VERSION ""

NS_ :

BS_:

BU_: AHLM ASBS CADM CBC DIAGNOST DPDM DTCM ECM EHPS ESC ESL ESM ETM EVCU2 GPF IC IRCM LTM OCM ORC PTS RF_HUB SCCM SGW TBM TCM

BO_ 996 NET_CFG_PT: 8 CBC
 SG_ NetCfg_TTPM : 59|1@1+ (1,0) [0|0] ""  RF_HUB,SGW
 SG_ NetCfg_TIM : 60|1@1+ (1,0) [0|0] ""  RF_HUB,SGW
 SG_ NetCfg_DPDM : 33|1@1+ (1,0) [0|0] ""  CADM,IRCM,RF_HUB,SGW
 SG_ NetCfg_SGW : 34|1@1+ (1,0) [0|0] ""  RF_HUB,SGW
 SG_ NetCfg_HCP : 38|1@1+ (1,0) [0|0] ""  CADM,EHPS,IRCM,RF_HUB,SGW
 SG_ NetCfg_ANC : 39|1@1+ (1,0) [0|0] ""  RF_HUB,SGW
 SG_ NetCfg_GPF : 58|1@1+ (1,0) [0|0] ""  RF_HUB,SGW
 SG_ NetCfg_AFLS : 28|1@1+ (1,0) [0|0] ""  RF_HUB,SGW
 SG_ NetCfg_ITBM : 29|1@1+ (1,0) [0|0] ""  RF_HUB,SGW
 SG_ NetCfg_OCM : 30|1@1+ (1,0) [0|0] ""  ORC,RF_HUB,SGW
 SG_ NetCfg_BSMO : 36|1@1+ (1,0) [0|0] ""  CADM,EHPS,IRCM,RF_HUB,SGW
 SG_ NetCfg_ELSD : 24|1@1+ (1,0) [0|0] ""  ESC,RF_HUB,SGW
 SG_ NetCfg_TCM : 25|1@1+ (1,0) [0|0] ""  CADM,ECM,ESM,IRCM,ORC,RF_HUB,SGW
 SG_ NetCfg_TPM : 26|1@1+ (1,0) [0|0] ""  RF_HUB,SGW
 SG_ NetCfg_ORC : 19|1@1+ (1,0) [0|0] ""  CADM,ECM,IRCM,RF_HUB,SGW
 SG_ NetCfg_PTS : 20|1@1+ (1,0) [0|0] ""  IC,RF_HUB,SGW
 SG_ NetCfg_DASM : 16|1@1+ (1,0) [0|0] ""  CADM,ECM,ESC,IC,IRCM,ORC,RF_HUB,SCCM,SGW,TCM
 SG_ NetCfg_FDCM : 17|1@1+ (1,0) [0|0] ""  RF_HUB,SGW
 SG_ NetCfg_ECM : 9|1@1+ (1,0) [0|0] ""  CADM,ECM,EHPS,IRCM,RF_HUB,SGW,TCM
 SG_ NetCfg_EPS : 10|1@1+ (1,0) [0|0] ""  ECM,IC,ORC,RF_HUB,SGW
 SG_ NetCfg_ESM : 11|1@1+ (1,0) [0|0] ""  ECM,RF_HUB,SGW
 SG_ NetCfg_ESC : 12|1@1+ (1,0) [0|0] ""  CADM,ECM,EHPS,IRCM,RF_HUB,SGW,TCM
 SG_ NetCfg_EPB : 13|1@1+ (1,0) [0|0] ""  ECM,RF_HUB,SGW
 SG_ NetCfg_RF_HUB : 14|1@1+ (1,0) [0|0] ""  CADM,ECM,IRCM,RF_HUB,SGW
 SG_ NetCfg_ADCM : 3|1@1+ (1,0) [0|0] ""  RF_HUB,SGW
 SG_ NetCfg_AHLM : 4|1@1+ (1,0) [0|0] ""  AHLM,RF_HUB,SGW
 SG_ NetCfg_VSIM_C : 5|1@1+ (1,0) [0|0] ""  ECM,RF_HUB,SGW
 SG_ NetCfg_ASCM : 6|1@1+ (1,0) [0|0] ""  RF_HUB,SGW
 SG_ NetCfg_CBC_PT : 7|1@1+ (1,0) [0|0] ""  CADM,ECM,EHPS,IRCM,RF_HUB,SGW,TCM
 SG_ NET_CFG_STAT_PT : 0|2@1+ (1,0) [0|0] ""  AHLM,ASBS,CADM,DPDM,DTCM,ECM,EHPS,ESC,ESL,ESM,EVCU2,IC,IRCM,OCM,ORC,PTS,RF_HUB,SCCM,SGW,TCM
 SG_ NetCfg_ACC : 2|1@1+ (1,0) [0|0] ""  RF_HUB,SGW
 SG_ NetCfg_DTCM : 8|1@1+ (1,0) [0|0] ""  CADM,ECM,ESC,EVCU2,IC,IRCM,PTS,RF_HUB,SGW,TCM
 SG_ NetCfg_IC : 15|1@1+ (1,0) [0|0] ""  CADM,ECM,EHPS,IRCM,RF_HUB,SGW,TCM
 SG_ NetCfg_EPPM : 18|1@1+ (1,0) [0|0] ""  RF_HUB,SGW
 SG_ NetCfg_SCCM : 23|1@1+ (1,0) [0|0] ""  CADM,ECM,EHPS,IRCM,RF_HUB,SGW
 SG_ NetCfg_PASS_PT : 27|1@1+ (1,0) [0|0] ""  RF_HUB,SGW
 SG_ NetCfg_HaLF : 31|1@1+ (1,0) [0|0] ""  RF_HUB,SGW
 SG_ NetCfg_ASBS : 35|1@1+ (1,0) [0|0] ""  IC,RF_HUB,SGW
 SG_ NetCfg_ESL : 37|1@1+ (1,0) [0|0] ""  RF_HUB,SGW
 SG_ NetCfg_EVCU2 : 61|1@1+ (1,0) [0|0] ""  RF_HUB,SGW

BO_ 998 BU_NET_CFG_INT: 8 RF_HUB
 SG_ BU_NetCfg_TBM : 38|1@1+ (1,0) [0|0] ""  CBC,SGW
 SG_ BU_NetCfg_ANC_I : 39|1@1+ (1,0) [0|0] ""  CBC,SGW
 SG_ BU_NetCfg_UPFM : 46|1@1+ (1,0) [0|0] ""  CBC,SGW
 SG_ BU_NetCfg_TTM : 47|1@1+ (1,0) [0|0] ""  CBC,SGW
 SG_ BU_NetCfg_PSSM : 45|1@1+ (1,0) [0|0] ""  CBC,SGW
 SG_ BU_NetCfg_MSM_PASS : 35|1@1+ (1,0) [0|0] ""  CBC,SGW
 SG_ BU_NetCfg_VRM : 36|1@1+ (1,0) [0|0] ""  CBC,SGW
 SG_ BU_NetCfg_DCSD : 37|1@1+ (1,0) [0|0] ""  CBC,SGW
 SG_ BU_NetCfg_HVAC_R : 31|1@1+ (1,0) [0|0] ""  CBC,SGW
 SG_ BU_NetCfg_CVPM : 32|1@1+ (1,0) [0|0] ""  CBC,SGW
 SG_ BU_NetCfg_TMM : 33|1@1+ (1,0) [0|0] ""  CBC,SGW
 SG_ BU_NetCfg_HFM_CTM : 26|1@1+ (1,0) [0|0] ""  CBC,SGW
 SG_ BU_NetCfg_ICS_I : 27|1@1+ (1,0) [0|0] ""  CBC,SGW
 SG_ BU_NetCfg_VES2_I : 28|1@1+ (1,0) [0|0] ""  CBC,SGW
 SG_ BU_NetCfg_VES3_I : 29|1@1+ (1,0) [0|0] ""  CBC,SGW
 SG_ BU_NetCfg_AMP_I : 24|1@1+ (1,0) [0|0] ""  CBC,SGW
 SG_ BU_NetCfg_CLOCK : 21|1@1+ (1,0) [0|0] ""  CBC,SGW
 SG_ BU_NetCfg_VSIM : 22|1@1+ (1,0) [0|0] ""  CBC,SGW
 SG_ BU_NetCfg_DTV : 19|1@1+ (1,0) [0|0] ""  CBC,SGW
 SG_ BU_NetCfg_FSM : 16|1@1+ (1,0) [0|0] ""  CBC,SGW
 SG_ BU_NetCfg_PTCM : 17|1@1+ (1,0) [0|0] ""  CBC,SGW
 SG_ BU_NetCfg_DCM_RR : 9|1@1+ (1,0) [0|0] ""  CBC,SGW
 SG_ BU_NetCfg_HVAC : 10|1@1+ (1,0) [0|0] ""  CBC,SGW
 SG_ BU_NetCfg_MSM : 11|1@1+ (1,0) [0|0] ""  CBC,SGW
 SG_ BU_NetCfg_PLG : 12|1@1+ (1,0) [0|0] ""  CBC,SGW
 SG_ BU_NetCfg_VTM : 13|1@1+ (1,0) [0|0] ""  CBC,SGW
 SG_ BU_NetCfg_PSD_LT : 14|1@1+ (1,0) [0|0] ""  CBC,SGW
 SG_ BU_NetCfg_DCM_RL : 8|1@1+ (1,0) [0|0] ""  CBC,SGW
 SG_ BU_NetCfg_PSD_RT : 15|1@1+ (1,0) [0|0] ""  CBC,SGW
 SG_ BU_NetCfg_RBC : 18|1@1+ (1,0) [0|0] ""  CBC,SGW
 SG_ BU_NetCfg_RBSS : 2|1@1+ (1,0) [0|0] ""  CBC,SGW
 SG_ BU_NetCfg_BSM : 3|1@1+ (1,0) [0|0] ""  CBC,SGW
 SG_ BU_NetCfg_CBC_IN : 4|1@1+ (1,0) [0|0] ""  CBC,SGW
 SG_ BU_NetCfg_CSWM : 5|1@1+ (1,0) [0|0] ""  CBC,SGW
 SG_ BU_NetCfg_DCM_DR : 6|1@1+ (1,0) [0|0] ""  CBC,SGW
 SG_ BU_NetCfg_DCM_PASS : 7|1@1+ (1,0) [0|0] ""  CBC,SGW
 SG_ BU_NetCfg_TGW : 20|1@1+ (1,0) [0|0] ""  CBC,SGW
 SG_ BU_NetCfg_ITM : 23|1@1+ (1,0) [0|0] ""  CBC,SGW
 SG_ BU_NetCfg_DVD_CDM : 25|1@1+ (1,0) [0|0] ""  CBC,SGW
 SG_ BU_NetCfg_CRSM : 30|1@1+ (1,0) [0|0] ""  CBC,SGW
 SG_ BU_NetCfg_ICS_R : 34|1@1+ (1,0) [0|0] ""  CBC,SGW
 SG_ BU_NET_CFG_STAT_INT : 0|2@1+ (1,0) [0|0] ""  CBC,SGW
 SG_ BU_NetCfg_TGWM : 42|1@1+ (1,0) [0|0] ""  CBC,SGW

BO_ 999 BU_NET_CFG_PT: 8 RF_HUB
 SG_ BU_NetCfg_TIM : 60|1@1+ (1,0) [0|0] ""  CBC,SGW
 SG_ BU_NetCfg_ACC : 2|1@1+ (1,0) [0|0] ""  CBC,SGW
 SG_ BU_NetCfg_DTCM : 8|1@1+ (1,0) [0|0] ""  CBC,SGW
 SG_ BU_NetCfg_EPB : 13|1@1+ (1,0) [0|0] ""  CBC,SGW
 SG_ BU_NetCfg_ORC : 19|1@1+ (1,0) [0|0] ""  CBC,SGW
 SG_ BU_NetCfg_SCCM : 23|1@1+ (1,0) [0|0] ""  CBC,SGW
 SG_ BU_NetCfg_PASS_PT : 27|1@1+ (1,0) [0|0] ""  CBC,SGW
 SG_ BU_NetCfg_HaLF : 31|1@1+ (1,0) [0|0] ""  CBC,SGW
 SG_ BU_NetCfg_ASBS : 35|1@1+ (1,0) [0|0] ""  CBC,SGW
 SG_ BU_NetCfg_ANC : 39|1@1+ (1,0) [0|0] ""  CBC,SGW
 SG_ BU_NetCfg_GPF : 58|1@1+ (1,0) [0|0] ""  CBC,SGW
 SG_ BU_NetCfg_BSMO : 36|1@1+ (1,0) [0|0] ""  CBC,SGW
 SG_ BU_NetCfg_ESL : 37|1@1+ (1,0) [0|0] ""  CBC,SGW
 SG_ BU_NetCfg_HCP : 38|1@1+ (1,0) [0|0] ""  CBC,SGW
 SG_ BU_NetCfg_DPDM : 33|1@1+ (1,0) [0|0] ""  CBC,SGW
 SG_ BU_NetCfg_SGW : 34|1@1+ (1,0) [0|0] ""  CBC,SGW
 SG_ BU_NetCfg_AFLS : 28|1@1+ (1,0) [0|0] ""  CBC,SGW
 SG_ BU_NetCfg_ITBM : 29|1@1+ (1,0) [0|0] ""  CBC,SGW
 SG_ BU_NetCfg_OCM : 30|1@1+ (1,0) [0|0] ""  CBC,SGW
 SG_ BU_NetCfg_ELSD : 24|1@1+ (1,0) [0|0] ""  CBC,SGW
 SG_ BU_NetCfg_TCM : 25|1@1+ (1,0) [0|0] ""  CBC,SGW
 SG_ BU_NetCfg_TPM : 26|1@1+ (1,0) [0|0] ""  CBC,SGW
 SG_ BU_NetCfg_PTS : 20|1@1+ (1,0) [0|0] ""  CBC,SGW
 SG_ BU_NetCfg_RF_HUB : 14|1@1+ (1,0) [0|0] ""  CBC,SGW
 SG_ BU_NetCfg_IC : 15|1@1+ (1,0) [0|0] ""  CBC,SGW
 SG_ BU_NetCfg_DASM : 16|1@1+ (1,0) [0|0] ""  CBC,SGW
 SG_ BU_NetCfg_FDCM : 17|1@1+ (1,0) [0|0] ""  CBC,SGW
 SG_ BU_NetCfg_EPPM : 18|1@1+ (1,0) [0|0] ""  CBC,SGW
 SG_ BU_NetCfg_ECM : 9|1@1+ (1,0) [0|0] ""  CBC,SGW
 SG_ BU_NetCfg_EPS : 10|1@1+ (1,0) [0|0] ""  CBC,SGW
 SG_ BU_NetCfg_ESM : 11|1@1+ (1,0) [0|0] ""  CBC,SGW
 SG_ BU_NetCfg_ESC : 12|1@1+ (1,0) [0|0] ""  CBC,SGW
 SG_ BU_NetCfg_ADCM : 3|1@1+ (1,0) [0|0] ""  CBC,SGW
 SG_ BU_NetCfg_AHLM : 4|1@1+ (1,0) [0|0] ""  CBC,SGW
 SG_ BU_NetCfg_VSIM_C : 5|1@1+ (1,0) [0|0] ""  CBC,SGW
 SG_ BU_NetCfg_ASCM : 6|1@1+ (1,0) [0|0] ""  CBC,SGW
 SG_ BU_NetCfg_CBC_PT : 7|1@1+ (1,0) [0|0] ""  CBC,SGW
 SG_ BU_NET_CFG_STAT_PT : 0|2@1+ (1,0) [0|0] ""  CBC,SGW
 SG_ BU_NetCfg_TTPM : 59|1@1+ (1,0) [0|0] ""  CBC,SGW
 SG_ BU_NetCfg_EVCU2 : 61|1@1+ (1,0) [0|0] ""  CBC,SGW

BO_ 1000 VehCfg1: 8 CBC
 SG_ VC_MODEL_YEAR : 2|6@1+ (1,2000) [2000|2062] "model-year"  AHLM,ASBS,CADM,DPDM,DTCM,ECM,EHPS,ESC,ESL,ESM,ETM,EVCU2,IC,IRCM,OCM,ORC,PTS,RF_HUB,SCCM,SGW,TBM,TCM
 SG_ VC_COUNTRY : 16|5@1+ (1,0) [0|0] ""  AHLM,ASBS,CADM,DPDM,DTCM,ECM,EHPS,ESC,ESL,ESM,ETM,EVCU2,IC,IRCM,OCM,ORC,PTS,RF_HUB,SCCM,SGW,TBM,TCM
 SG_ VC_LHD_RHD : 21|2@1+ (1,0) [0|0] ""  CADM,DTCM,ESC,ETM,IC,IRCM,RF_HUB,SGW,TBM
 SG_ VC_VehCfg1_Stat : 0|2@1+ (1,0) [0|0] ""  AHLM,ASBS,CADM,DPDM,DTCM,ECM,EHPS,ESC,ESL,ESM,EVCU2,IC,IRCM,OCM,ORC,PTS,RF_HUB,SCCM,SGW,TCM
 SG_ VC_RemStPrsnt : 23|1@1+ (1,0) [0|0] ""  IC,ORC,RF_HUB,SGW,TCM
 SG_ VC_AUTO_HB : 27|1@1+ (1,0) [0|0] ""  CADM,IC,IRCM,RF_HUB,SGW
 SG_ VC_PTS_DispTyp : 44|3@1+ (1,0) [0|0] ""  RF_HUB,SGW
 SG_ VC_RVCM_Prsnt : 60|1@1+ (1,0) [0|0] ""  RF_HUB,SGW
 SG_ VC_VEH_LINE : 8|8@1+ (1,0) [0|0] ""  AHLM,ASBS,CADM,DPDM,DTCM,ECM,EHPS,ESC,ESL,ESM,ETM,EVCU2,IC,IRCM,OCM,ORC,PTS,RF_HUB,SCCM,SGW,TBM,TCM
 SG_ VC_CHMCM_Prsnt : 61|1@1+ (1,0) [0|0] ""  RF_HUB,SGW
 SG_ VC_HDC_Prsnt : 62|1@1+ (1,0) [0|0] ""  CADM,ECM,ESC,EVCU2,IC,IRCM,RF_HUB,SGW,TCM
 SG_ VC_SSC_Prsnt : 63|1@1+ (1,0) [0|0] ""  DTCM,ECM,ESC,EVCU2,IC,RF_HUB,SGW,TCM
 SG_ VC_PP_Prsnt : 47|1@1+ (1,0) [0|0] ""  RF_HUB,SGW
 SG_ VC_SpecialPKG : 48|8@1+ (1,0) [1|254] ""  RF_HUB,SGW
 SG_ VC_HdRstPrsnt : 56|1@1+ (1,0) [0|0] ""  RF_HUB,SGW
 SG_ VC_SCR_Prsnt : 57|1@1+ (1,0) [0|0] ""  IC,RF_HUB,SGW
 SG_ VC_PTS_Config : 58|2@1+ (1,0) [0|0] ""  IC,RF_HUB,SGW
 SG_ VC_BODY_STYLE : 28|4@1+ (1,0) [0|0] ""  AHLM,ASBS,CADM,DPDM,DTCM,ECM,EHPS,ESC,ESL,ESM,EVCU2,IC,IRCM,OCM,ORC,PTS,RF_HUB,SCCM,SGW,TCM
 SG_ VC_MAX_VEH_SPD : 32|8@1+ (2,0) [0|506] "kph"  CADM,IRCM,RF_HUB,SGW
 SG_ VC_ShftrTyp : 40|4@1+ (1,0) [0|0] ""  IC,RF_HUB,SGW,TCM
 SG_ VC_XWD : 24|2@1+ (1,0) [0|0] ""  CADM,DTCM,ECM,EHPS,ESC,EVCU2,IRCM,RF_HUB,SGW,TCM
 SG_ VC_EmodePrsnt : 26|1@1+ (1,0) [0|0] ""  RF_HUB,SGW

BO_ 1001 VehCfg2: 8 CBC
 SG_ VC_ThatchamPrsnt : 4|1@1+ (1,0) [0|0] ""  RF_HUB,SGW
 SG_ VC_MaseratiMd : 6|2@1+ (1,0) [0|0] ""  RF_HUB,SGW
 SG_ VC_RainSnsPrsnt : 9|1@1+ (1,0) [0|0] ""  CADM,RF_HUB,SGW
 SG_ VC_CRUISE_PRSNT : 12|1@1+ (1,0) [0|0] ""  CADM,ECM,EVCU2,IC,IRCM,ORC,RF_HUB,SCCM,SGW,TCM
 SG_ VC_DRVMD_Prsnt : 25|1@1+ (1,0) [0|0] ""  RF_HUB,SGW
 SG_ VC_ShftInd_Prsnt : 30|2@1+ (1,0) [0|0] ""  ECM,EVCU2,IC,RF_HUB,SGW
 SG_ VC_LgtLdPressFtTr : 56|8@1+ (1,0) [0|126] "psi"  RF_HUB,SGW
 SG_ VC_MaxLdPressRrTr : 32|8@1+ (1,0) [0|126] "psi"  IC,RF_HUB,SGW
 SG_ VC_MaxLdPressFtTr : 40|8@1+ (1,0) [0|126] "psi"  IC,RF_HUB,SGW
 SG_ VC_LgtLdPressRrTr : 48|8@1+ (1,0) [0|126] "psi"  RF_HUB,SGW
 SG_ VC_MemoryDRVMD_Prsnt : 26|1@1+ (1,0) [0|0] ""  RF_HUB,SGW
 SG_ VC_ESCDrvMd_Prsnt : 27|1@1+ (1,0) [0|0] ""  RF_HUB,SGW
 SG_ VC_EngPowerDrvMd_Prsnt : 28|1@1+ (1,0) [0|0] ""  RF_HUB,SGW
 SG_ VC_SecPrkPrsnt : 29|1@1+ (1,0) [0|0] ""  RF_HUB,SGW
 SG_ VC_FG_PRSNT : 13|1@1+ (1,0) [0|0] ""  RF_HUB,SGW
 SG_ VC_FULL_SPARE : 14|1@1+ (1,0) [0|0] ""  RF_HUB,SGW
 SG_ VC_OffRoad : 15|1@1+ (1,0) [0|0] ""  RF_HUB,SGW
 SG_ VC_ECO_Indicator : 24|1@1+ (1,0) [0|0] ""  RF_HUB,SGW
 SG_ VC_SKIM_PRSNT : 10|1@1+ (1,0) [0|0] ""  RF_HUB,SGW
 SG_ VC_AC_Prsnt : 11|1@1+ (1,0) [0|0] ""  RF_HUB,SGW
 SG_ VC_PADS_Prsnt : 8|1@1+ (1,0) [0|0] ""  IC,ORC,RF_HUB,SGW
 SG_ VC_RunFlatTirePrsnt : 5|1@1+ (1,0) [0|0] ""  RF_HUB,SGW
 SG_ VC_VehCfg2_Stat : 0|2@1+ (1,0) [0|0] ""  ECM,ESC,ESM,EVCU2,IC,IRCM,ORC,RF_HUB,SCCM,SGW,TCM
 SG_ VC_PwrIvtrTyp : 2|2@1+ (1,0) [0|0] ""  RF_HUB,SGW
 SG_ VC_SpecialPKG_IC : 16|8@1+ (1,0) [0|0] ""  CADM,IC,IRCM,RF_HUB,SGW

BO_ 1002 VehCfg3: 8 CBC
 SG_ VC_PDDL_PRSNT : 59|1@1+ (1,0) [0|0] ""  IC,RF_HUB,SGW,TCM
 SG_ VC_SPORT_PRSNT : 60|1@1+ (1,0) [0|0] ""  RF_HUB,SGW
 SG_ VC_HID_HL : 51|1@1+ (1,0) [0|0] ""  RF_HUB,SGW
 SG_ VC_SecLkPrsnt : 52|1@1+ (1,0) [0|0] ""  RF_HUB,SGW
 SG_ VC_Liftgate_Trunk : 53|2@1+ (1,0) [0|0] ""  RF_HUB,SGW
 SG_ VC_CMS : 55|1@1+ (1,0) [0|0] ""  IC,CADM,ESC,IRCM,ORC,RF_HUB,SGW
 SG_ VC_FCW : 56|1@1+ (1,0) [0|0] ""  IC,CADM,ESC,IRCM,ORC,RF_HUB,SGW
 SG_ VC_Base_TPM : 57|1@1+ (1,0) [0|0] ""  ORC,RF_HUB,SGW
 SG_ VC_TEMP_DISP : 39|1@1+ (1,0) [0|0] ""  IC,RF_HUB,SGW
 SG_ VC_HVAC_Config : 40|4@1+ (1,0) [0|0] ""  RF_HUB,SGW
 SG_ VC_VEH_BRAND : 44|4@1+ (1,0) [0|0] ""  PTS,RF_HUB,SGW
 SG_ VC_CMP_DISP : 48|1@1+ (1,0) [0|0] ""  IC,RF_HUB,SGW
 SG_ VC_IntEC_MIRR : 49|1@1+ (1,0) [0|0] ""  RF_HUB,SGW
 SG_ VC_SRT_PRSNT : 30|1@1+ (1,0) [0|0] ""  DTCM,IC,RF_HUB,SGW
 SG_ VC_DSBL_CLK_DISP : 31|1@1+ (1,0) [0|0] ""  RF_HUB,SGW
 SG_ VC_SunShade_Present : 7|1@1+ (1,0) [0|0] ""  RF_HUB,SGW
 SG_ VC_WIN_EXPR_FEAT : 24|2@1+ (1,0) [0|0] ""  RF_HUB,SGW
 SG_ VC_DualFuelSens : 29|1@1+ (1,0) [0|0] ""  IC,RF_HUB,SGW
 SG_ VC_ChassisType : 32|7@1+ (1,0) [0|126] ""  DTCM,EHPS,ESC,RF_HUB,SGW
 SG_ VC_ESCL_PRSNT : 50|1@1+ (1,0) [0|0] ""  RF_HUB,SGW
 SG_ VC_Prem_TPM : 58|1@1+ (1,0) [0|0] ""  IC,ORC,RF_HUB,SGW
 SG_ VC_AutoParkPrsnt : 61|1@1+ (1,0) [0|0] ""  RF_HUB,SGW
 SG_ VC_ADJ_PDL_PRSNT : 26|1@1+ (1,0) [0|0] ""  RF_HUB,SGW
 SG_ VC_AUTO_HL : 27|1@1+ (1,0) [0|0] ""  RF_HUB,SGW
 SG_ VC_DrAlrPrsnt : 28|1@1+ (1,0) [0|0] ""  RF_HUB,SGW
 SG_ VC_WHL_BASE : 12|2@1+ (1,0) [0|0] ""  CADM,IC,IRCM,RF_HUB,SGW
 SG_ VC_FOBIKsafeENBL : 14|1@1+ (1,0) [0|0] ""  RF_HUB,SGW
 SG_ VC_ELV_Prsnt : 15|1@1+ (1,0) [0|0] ""  RF_HUB,SGW
 SG_ VC_FUEL_CAP : 16|8@1+ (1,36) [36|290] "liters"  IC,RF_HUB,SGW
 SG_ VC_VehCfg3_Stat : 0|2@1+ (1,0) [0|0] ""  DTCM,ECM,EHPS,ESC,ESM,EVCU2,IC,IRCM,ORC,PTS,RF_HUB,SGW,TCM
 SG_ VC_POLICE : 2|1@1+ (1,0) [0|0] ""  RF_HUB,SGW
 SG_ VC_PWR_LFT_GT : 3|1@1+ (1,0) [0|0] ""  RF_HUB,SGW
 SG_ VC_PWR_RT_SLDR : 4|1@1+ (1,0) [0|0] ""  RF_HUB,SGW
 SG_ VC_PWR_LT_SLDR : 5|1@1+ (1,0) [0|0] ""  RF_HUB,SGW
 SG_ VC_RKE_PRSNT : 6|1@1+ (1,0) [0|0] ""  RF_HUB,SGW
 SG_ VC_TcaseTyp : 8|4@1+ (1,0) [0|0] ""  DTCM,ESC,EVCU2,IC,RF_HUB,SGW
 SG_ VC_PE_Prsnt : 62|1@1+ (1,0) [0|0] ""  RF_HUB,SGW
 SG_ VC_KG_Prsnt : 63|1@1+ (1,0) [0|0] ""  IC,RF_HUB,SGW,TCM

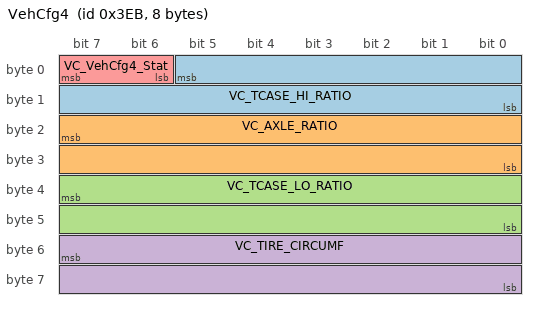
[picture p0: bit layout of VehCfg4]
BO_ 1003 VehCfg4: 8 CBC
 SG_ VC_TCASE_HI_RATIO : 5|14@0+ (0.001,0) [0|16.382] ""  DTCM,ECM,ESC,EVCU2,RF_HUB,SGW,TCM
 SG_ VC_AXLE_RATIO : 23|16@0+ (0.001,0) [0|65.534] ""  CADM,DTCM,ECM,ESC,EVCU2,IRCM,RF_HUB,SGW,TCM
 SG_ VC_TCASE_LO_RATIO : 39|16@0+ (0.001,0) [0|65.534] ""  DTCM,ECM,ESC,EVCU2,RF_HUB,SGW,TCM
 SG_ VC_TIRE_CIRCUMF : 55|16@0+ (1,0) [0|65534] "mm"  CADM,DTCM,ECM,EHPS,ESC,EVCU2,IRCM,ORC,RF_HUB,SGW,TCM
 SG_ VC_VehCfg4_Stat : 6|2@1+ (1,0) [0|0] ""  DTCM,ECM,EHPS,ESC,EVCU2,IRCM,ORC,PTS,RF_HUB,SGW,TCM

BO_ 1004 VehCfgBu1: 8 RF_HUB
 SG_ VC_BU_VehCfg1_Stat : 0|2@1+ (1,0) [0|0] ""  CBC,SGW
 SG_ VC_BU_COUNTRY : 16|5@1+ (1,0) [0|0] ""  CBC,SGW
 SG_ VC_BU_MAX_VEH_SPD : 32|8@1+ (2,0) [0|506] "kph"  CBC,SGW
 SG_ VC_BU_PTS_DispTyp : 44|3@1+ (1,0) [0|0] ""  CBC,SGW
 SG_ VC_BU_HdRstPrsnt : 56|1@1+ (1,0) [0|0] ""  CBC,SGW
 SG_ VC_BU_RVCM_Prsnt : 60|1@1+ (1,0) [0|0] ""  CBC,SGW
 SG_ VC_BU_SSC_Prsnt : 63|1@1+ (1,0) [0|0] ""  CBC,SGW
 SG_ VC_BU_CHMCM_Prsnt : 61|1@1+ (1,0) [0|0] ""  CBC,SGW
 SG_ VC_BU_HDC_Prsnt : 62|1@1+ (1,0) [0|0] ""  CBC,SGW
 SG_ VC_BU_SCR_Prsnt : 57|1@1+ (1,0) [0|0] ""  CBC,SGW
 SG_ VC_BU_PTS_Config : 58|2@1+ (1,0) [0|0] ""  CBC,SGW
 SG_ VC_BU_PP_Prsnt : 47|1@1+ (1,0) [0|0] ""  CBC,SGW
 SG_ VC_BU_SpecialPKG : 48|8@1+ (1,0) [1|254] ""  CBC,SGW
 SG_ VC_BU_ShftrTyp : 40|4@1+ (1,0) [0|0] ""  CBC,SGW
 SG_ VC_BU_LHD_RHD : 21|2@1+ (1,0) [0|0] ""  CBC,SGW
 SG_ VC_BU_RemStPrsnt : 23|1@1+ (1,0) [0|0] ""  CBC,SGW
 SG_ VC_BU_XWD : 24|2@1+ (1,0) [0|0] ""  CBC,SGW
 SG_ VC_BU_EmodePrsnt : 26|1@1+ (1,0) [0|0] ""  CBC,SGW
 SG_ VC_BU_AUTO_HB : 27|1@1+ (1,0) [0|0] ""  CBC,SGW
 SG_ VC_BU_BODY_STYLE : 28|4@1+ (1,0) [0|0] ""  CBC,SGW
 SG_ VC_BU_MODEL_YEAR : 2|6@1+ (1,2000) [2000|2062] "model-year"  CBC,SGW
 SG_ VC_BU_VEH_LINE : 8|8@1+ (1,0) [0|0] ""  CBC,SGW

CM_ SG_ 996 NetCfg_TTPM "TTPM (1=present)";
CM_ SG_ 996 NetCfg_TIM "TIM (1=present)";
CM_ SG_ 996 NetCfg_DPDM "Driver Presence Detection Module (1=present)";
CM_ SG_ 996 NetCfg_SGW "Security GateWay (1=present)";
CM_ SG_ 996 NetCfg_HCP "Hybrid Control Processor (1=present)";
CM_ SG_ 996 NetCfg_ANC "Active Noise Cancellation (1=present)";
CM_ SG_ 996 NetCfg_GPF "Gasoline Particulate Filter Net Config, Present=1";
CM_ SG_ 996 NetCfg_AFLS "Advanced Front Lighting System (1=present)";
CM_ SG_ 996 NetCfg_ITBM "Integrated Trailer Brake Module (1=present)";
CM_ SG_ 996 NetCfg_OCM "Occupant Classification Module (1=present)";
CM_ SG_ 996 NetCfg_BSMO "Brake System Module - OBD (1=present)";
CM_ SG_ 996 NetCfg_ELSD "Electric Limited Slip Differential (1=present)";
CM_ SG_ 996 NetCfg_TCM "Automatic Transmission Controller (1=present)";
CM_ SG_ 996 NetCfg_TPM "Tire Pressure Monitor (1=present)";
CM_ SG_ 996 NetCfg_ORC "Occupant Restraint Controller (1=present)";
CM_ SG_ 996 NetCfg_PTS "Parktronics System (1=present)";
CM_ SG_ 996 NetCfg_DASM "Driver Assistance System Module (1=present)";
CM_ SG_ 996 NetCfg_FDCM "Final Drive Control Module (1=present)";
CM_ SG_ 996 NetCfg_ECM "Engine Control Module (1=present)";
CM_ SG_ 996 NetCfg_EPS "Electric Power Steering (1=present)";
CM_ SG_ 996 NetCfg_ESM "Electronic Shift Module (1=present)";
CM_ SG_ 996 NetCfg_ESC "Electronic Stability Module / Anti-Lock Brake (1=present)";
CM_ SG_ 996 NetCfg_EPB "Electric Park Brake Module (1=present)";
CM_ SG_ 996 NetCfg_RF_HUB "RF Hub Node (1=present)";
CM_ SG_ 996 NetCfg_ADCM "Active Damping Control Module (1=present)";
CM_ SG_ 996 NetCfg_AHLM "Automatic Headlamp Leveling Module (1=present)";
CM_ SG_ 996 NetCfg_VSIM_C "Vehicle System Interface Module (1=present)";
CM_ SG_ 996 NetCfg_ASCM "Air Suspension Control Module (1=present)";
CM_ SG_ 996 NetCfg_CBC_PT "Common Body Controller PT Bus (1=present)";
CM_ SG_ 996 NET_CFG_STAT_PT "Network configuration status";
CM_ SG_ 996 NetCfg_ACC "Active Cruise Control (1=present)";
CM_ SG_ 996 NetCfg_DTCM "Drivetrain Control Module (1=present)";
CM_ SG_ 996 NetCfg_IC "Instrument Cluster (1=present)";
CM_ SG_ 996 NetCfg_EPPM "Elect. Pedestrian protection module (1=present)";
CM_ SG_ 996 NetCfg_SCCM "Steering Column Control Module (1=present)";
CM_ SG_ 996 NetCfg_PASS_PT "Personal Assistant Safety System Module PT Bus (1=present)";
CM_ SG_ 996 NetCfg_HaLF "Haptic Lane Feedback module (1=present)";
CM_ SG_ 996 NetCfg_ASBS "Automatic Sway Bar System Module (Present = 1, Not Present = 0)";
CM_ SG_ 996 NetCfg_ESL "Electric Steering Lock (1=present)";
CM_ SG_ 996 NetCfg_EVCU2 "Electric Vehicle Control Unit 2 (1=present)";
CM_ SG_ 998 BU_NetCfg_TBM "Backup for Telematics Box Module (1=present)";
CM_ SG_ 998 BU_NetCfg_ANC_I "Backup for Active Noise Cancellation interior (1=present)";
CM_ SG_ 998 BU_NetCfg_UPFM "Backup for Upfitter Module (1=present)";
CM_ SG_ 998 BU_NetCfg_TTM "0= Not Present;  1= Present";
CM_ SG_ 998 BU_NetCfg_PSSM "NetCfg PSSM";
CM_ SG_ 998 BU_NetCfg_MSM_PASS "Backup for CAN I Memory Seat Module Passenger (1=present)";
CM_ SG_ 998 BU_NetCfg_VRM "Backup for Video Routing Module (1=present)";
CM_ SG_ 998 BU_NetCfg_DCSD "Backup for Disassociated Center Stack Display Module (1=present)";
CM_ SG_ 998 BU_NetCfg_HVAC_R "Backup for CAN I Rear Heating Ventilation Air Conditioning (1=present)";
CM_ SG_ 998 BU_NetCfg_CVPM "Backup for CAN I Central Vision Processing Module (1=present)";
CM_ SG_ 998 BU_NetCfg_TMM "Backup for CAN I Track Mapping Module (1=present)";
CM_ SG_ 998 BU_NetCfg_HFM_CTM "Backup for Convergence Telematics Module (1=present)";
CM_ SG_ 998 BU_NetCfg_ICS_I "Backup for CAN I Integrated Center Stack Module (1=present)";
CM_ SG_ 998 BU_NetCfg_VES2_I "Backup for CAN I Video Ent. System screen 2 Module (1=present)";
CM_ SG_ 998 BU_NetCfg_VES3_I "Backup for CAN I Video Ent. System screen 1 Module (1=present)";
CM_ SG_ 998 BU_NetCfg_AMP_I "Backup for CAN I Amplifier Module (1=present)";
CM_ SG_ 998 BU_NetCfg_CLOCK "Backup for CAN I Clock Module (1=present)";
CM_ SG_ 998 BU_NetCfg_VSIM "Backup for Vehicle System Interface Module (1=present)";
CM_ SG_ 998 BU_NetCfg_DTV "Backup for Digital TV Module (1=present)";
CM_ SG_ 998 BU_NetCfg_FSM "Backup for Folding Seat Module (1=present)";
CM_ SG_ 998 BU_NetCfg_PTCM "Backup for Power Top Control Module (1=present)";
CM_ SG_ 998 BU_NetCfg_DCM_RR "Backup for Door Control Module Rear Right (1=present)";
CM_ SG_ 998 BU_NetCfg_HVAC "Backup for Heating Ventilation Air Conditioning (1=present)";
CM_ SG_ 998 BU_NetCfg_MSM "Backup for Memory Seat Module (1=present)";
CM_ SG_ 998 BU_NetCfg_PLG "Backup for Power Liftgate Module (1=present)";
CM_ SG_ 998 BU_NetCfg_VTM "Backup for vehicle theft / tax module (1=present)";
CM_ SG_ 998 BU_NetCfg_PSD_LT "Backup for Power Sliding Door Left Module (1=present)";
CM_ SG_ 998 BU_NetCfg_DCM_RL "Backup for Door Control Module Rear Left (1=present)";
CM_ SG_ 998 BU_NetCfg_PSD_RT "Backup for Power Sliding Door Right Module (1=present)";
CM_ SG_ 998 BU_NetCfg_RBC "Backup for Rear Body Controller Module (1=present)";
CM_ SG_ 998 BU_NetCfg_RBSS "Backup for Right Blind-Spot Module (1=present)";
CM_ SG_ 998 BU_NetCfg_BSM "Backup for Blind-Spot Module (1=present)";
CM_ SG_ 998 BU_NetCfg_CBC_IN "Backup for Common Body Controller Int Bus (1=present)";
CM_ SG_ 998 BU_NetCfg_CSWM "Backup for Comfot Seats and Wheel Module (1=present)";
CM_ SG_ 998 BU_NetCfg_DCM_DR "Backup for Door Control Module Driver (1=present)";
CM_ SG_ 998 BU_NetCfg_DCM_PASS "Backup for Door Control Module Passenger (1=present)";
CM_ SG_ 998 BU_NetCfg_TGW "Backup for Telematics gateway (1=present)";
CM_ SG_ 998 BU_NetCfg_ITM "Backup for Intrusion module (1=present)";
CM_ SG_ 998 BU_NetCfg_DVD_CDM "Backup for CAN I in-dash disc player module (1=present)";
CM_ SG_ 998 BU_NetCfg_CRSM "Backup for CAN I Comfort Rear Seat Module (1=present)";
CM_ SG_ 998 BU_NetCfg_ICS_R "Backup for CAN I Integrated rear Center Stack Module (1=present)";
CM_ SG_ 998 BU_NET_CFG_STAT_INT "Backup for network configuration status";
CM_ SG_ 998 BU_NetCfg_TGWM "Backup for NetCfg_TGWM(1=present)";
CM_ SG_ 999 BU_NetCfg_TIM "Backup for TIM (1=present)";
CM_ SG_ 999 BU_NetCfg_ACC "Backup for Active Cruise Control (1=present)";
CM_ SG_ 999 BU_NetCfg_DTCM "Backup for Drivetrain Control Module (1=present)";
CM_ SG_ 999 BU_NetCfg_EPB "Backup for Electric Park Brake Module (1=present)";
CM_ SG_ 999 BU_NetCfg_ORC "Backup for Occupant Restraint Controller (1=present)";
CM_ SG_ 999 BU_NetCfg_SCCM "Backup for Steering Column Control Module (1=present)";
CM_ SG_ 999 BU_NetCfg_PASS_PT "Backup for Personal Assistant Safety System Module PT Bus (1=present)";
CM_ SG_ 999 BU_NetCfg_HaLF "Backup for Haptic Lane Feedback module (1=present)";
CM_ SG_ 999 BU_NetCfg_ASBS "Automatic Sway Bar System Module (Present = 1, Not Present = 0)";
CM_ SG_ 999 BU_NetCfg_ANC "Backup for Active Noise Cancellation (1=present)";
CM_ SG_ 999 BU_NetCfg_GPF "Gasoline Particulate Filter Net Config Backup, Present=1";
CM_ SG_ 999 BU_NetCfg_BSMO "Backup for Brake System Module - OBD (1=present)";
CM_ SG_ 999 BU_NetCfg_ESL "Backup for Electric Steering Lock (1=present)";
CM_ SG_ 999 BU_NetCfg_HCP "Backup for Hybrid Control Processor (1=present)";
CM_ SG_ 999 BU_NetCfg_DPDM "Backup for Driver Presence Detection Module (1=present)";
CM_ SG_ 999 BU_NetCfg_SGW "Backup for Security GateWay (1=present)";
CM_ SG_ 999 BU_NetCfg_AFLS "Backup for Advanced Front Lighting System (1=present)";
CM_ SG_ 999 BU_NetCfg_ITBM "Backup for Integrated Trailer Brake Module (1=present)";
CM_ SG_ 999 BU_NetCfg_OCM "Backup for Occupant Classification Module (1=present)";
CM_ SG_ 999 BU_NetCfg_ELSD "Backup for Electric Limited Slip Differential (1=present)";
CM_ SG_ 999 BU_NetCfg_TCM "Backup for Automatic Transmission Controller (1=present)";
CM_ SG_ 999 BU_NetCfg_TPM "Backup for Tire Pressure Monitor (1=present)";
CM_ SG_ 999 BU_NetCfg_PTS "Backup for Parktronics System (1=present)";
CM_ SG_ 999 BU_NetCfg_RF_HUB "Backup for RF HUB Node (1=present)";
CM_ SG_ 999 BU_NetCfg_IC "Backup for Instrument Cluster (1=present)";
CM_ SG_ 999 BU_NetCfg_DASM "Backup for Driver Assistance System Module (1=present)";
CM_ SG_ 999 BU_NetCfg_FDCM "Backup for Final Drive Control Module (1=present)";
CM_ SG_ 999 BU_NetCfg_EPPM "Backup for  Elect. Pedestrian protection module (1=present)";
CM_ SG_ 999 BU_NetCfg_ECM "Backup for Engine Control Module (1=present)";
CM_ SG_ 999 BU_NetCfg_EPS "Backup for Electric Power Steering (1=present)";
CM_ SG_ 999 BU_NetCfg_ESM "Backup for Electronic Shift Module (1=present)";
CM_ SG_ 999 BU_NetCfg_ESC "Backup for Electronic Stability Module / Anti-Lock Brake (1=present)";
CM_ SG_ 999 BU_NetCfg_ADCM "Backup for Active Damping Control Module (1=present)";
CM_ SG_ 999 BU_NetCfg_AHLM "Backup for Automatic Headlamp Leveling Module (1=present)";
CM_ SG_ 999 BU_NetCfg_VSIM_C "Backup for Vehicle System Interface Module (1=present)";
CM_ SG_ 999 BU_NetCfg_ASCM "Backup for Air Suspension Control Module (1=present)";
CM_ SG_ 999 BU_NetCfg_CBC_PT "Backup for Common Body Controller PT Bus (1=present)";
CM_ SG_ 999 BU_NET_CFG_STAT_PT "Backup for network configuration status";
CM_ SG_ 999 BU_NetCfg_TTPM "Backup for TTPM (1=present)";
CM_ SG_ 999 BU_NetCfg_EVCU2 "Electric Vehicle Control Unit 2 (1=present)";
CM_ SG_ 1000 VC_MODEL_YEAR "Model year";
CM_ SG_ 1000 VC_COUNTRY "Country Code";
CM_ SG_ 1000 VC_LHD_RHD "Left/right hand drive";
CM_ SG_ 1000 VC_VehCfg1_Stat "Configuration messages status 1";
CM_ SG_ 1000 VC_RemStPrsnt "Remote start present; present = [1]";
CM_ SG_ 1000 VC_AUTO_HB "Auto Highbeam feature present; present = [1]";
CM_ SG_ 1000 VC_PTS_DispTyp "PTS display type and location";
CM_ SG_ 1000 VC_RVCM_Prsnt "Rear view camera (1=present)";
CM_ SG_ 1000 VC_VEH_LINE "Vehicle line";
CM_ SG_ 1000 VC_CHMCM_Prsnt "CHMSL camera (1=present)";
CM_ SG_ 1000 VC_HDC_Prsnt "Hill descent feature is present; present = [1]";
CM_ SG_ 1000 VC_SSC_Prsnt "Select speed control feature is present; present = [1]";
CM_ SG_ 1000 VC_PP_Prsnt "Performance Pages Present (1=present)";
CM_ SG_ 1000 VC_SpecialPKG "Special sales code package";
CM_ SG_ 1000 VC_HdRstPrsnt "Headrest present; present = [1]";
CM_ SG_ 1000 VC_SCR_Prsnt "Urea/SCR system present; present = [1]";
CM_ SG_ 1000 VC_PTS_Config "Parktronics system configuration";
CM_ SG_ 1000 VC_BODY_STYLE "Body style";
CM_ SG_ 1000 VC_MAX_VEH_SPD "Maximum vehicle speed";
CM_ SG_ 1000 VC_ShftrTyp "Shifter type";
CM_ SG_ 1000 VC_XWD "Drive configuration";
CM_ SG_ 1000 VC_EmodePrsnt "E-Mode feature present; True = [1]";
CM_ SG_ 1001 VC_ThatchamPrsnt "Thatcham present; present = [1]";
CM_ SG_ 1001 VC_MaseratiMd "Maserati vehicle mode";
CM_ SG_ 1001 VC_RainSnsPrsnt "Rain sensor present; present = [1]";
CM_ SG_ 1001 VC_CRUISE_PRSNT "Cruise feature is present; present = [1]";
CM_ SG_ 1001 VC_DRVMD_Prsnt "Drive mode feature configuration (1 = Present)";
CM_ SG_ 1001 VC_ShftInd_Prsnt "Configuration for performance & gear shift indication";
CM_ SG_ 1001 VC_LgtLdPressFtTr "Light Load Inflation Pressure Front Tire";
CM_ SG_ 1001 VC_MaxLdPressRrTr "Max Load Inflation Pressure Rear Tire";
CM_ SG_ 1001 VC_MaxLdPressFtTr "Max Load Inflation Pressure Front Tire";
CM_ SG_ 1001 VC_LgtLdPressRrTr "Light Load Inflation Pressure Rear Tire";
CM_ SG_ 1001 VC_MemoryDRVMD_Prsnt "Memory drive mode sub-feature configuration (1 = Present)";
CM_ SG_ 1001 VC_ESCDrvMd_Prsnt "ESC drive mode sub-feature configuration (1 = Present)";
CM_ SG_ 1001 VC_EngPowerDrvMd_Prsnt "ECM drive mode sub-feature configuration (1 = Present)";
CM_ SG_ 1001 VC_SecPrkPrsnt "Secure park feature present; present = [1]";
CM_ SG_ 1001 VC_FG_PRSNT "Flipper glass present; present = [1]";
CM_ SG_ 1001 VC_FULL_SPARE "Full size spare; present = [1]";
CM_ SG_ 1001 VC_OffRoad "Off road capable; present = [1]";
CM_ SG_ 1001 VC_ECO_Indicator "ECO Indicator present on vehicle; True = [1]";
CM_ SG_ 1001 VC_SKIM_PRSNT "SKIM system present; present = [1]";
CM_ SG_ 1001 VC_AC_Prsnt "Vehicle is equipped with air conditioning; present = [1]";
CM_ SG_ 1001 VC_PADS_Prsnt "Pass. airbag disable switch present; present = [1]";
CM_ SG_ 1001 VC_RunFlatTirePrsnt "Run flat tires present; present = [1]";
CM_ SG_ 1001 VC_VehCfg2_Stat "Configuration messages status 2";
CM_ SG_ 1001 VC_PwrIvtrTyp "Power inverter type";
CM_ SG_ 1001 VC_SpecialPKG_IC "Special sales code package";
CM_ SG_ 1002 VC_PDDL_PRSNT "Paddle shift feature is present; present = [1]";
CM_ SG_ 1002 VC_SPORT_PRSNT "Sport mode is present; present = [1]";
CM_ SG_ 1002 VC_HID_HL "High intensity discharge head lamps; present = [1]";
CM_ SG_ 1002 VC_SecLkPrsnt "Secondary Lock Present; [1] = True";
CM_ SG_ 1002 VC_Liftgate_Trunk "Liftgate or trunk";
CM_ SG_ 1002 VC_CMS "Collision Mitigation System present; present = [1]";
CM_ SG_ 1002 VC_FCW "Forward Collision Warning present; present = [1]";
CM_ SG_ 1002 VC_Base_TPM "Base TPM system present; present = [1]";
CM_ SG_ 1002 VC_TEMP_DISP "Display outside temperature present; present = [1]";
CM_ SG_ 1002 VC_HVAC_Config "HVAC Configuration";
CM_ SG_ 1002 VC_VEH_BRAND "Vehicle brand type";
CM_ SG_ 1002 VC_CMP_DISP "Display compass heading present; present = [1]";
CM_ SG_ 1002 VC_IntEC_MIRR "Vehicle is equipped with an interior EC mirror; present = [1]";
CM_ SG_ 1002 VC_SRT_PRSNT "Vehicle is an SRT; present = [1]";
CM_ SG_ 1002 VC_DSBL_CLK_DISP "Disable display of radio clock; 1 = clock display disabled";
CM_ SG_ 1002 VC_SunShade_Present "Vehicle equipped w/SunShade (1=present)";
CM_ SG_ 1002 VC_WIN_EXPR_FEAT "Window express feature configuration";
CM_ SG_ 1002 VC_DualFuelSens "Vehicle equipped with two fuel sending units; present = [1]";
CM_ SG_ 1002 VC_ChassisType "Chassis type (including suspension, brakes, and tires)";
CM_ SG_ 1002 VC_ESCL_PRSNT "ESCL system present; enabled=[1], disabled=[0]";
CM_ SG_ 1002 VC_Prem_TPM "Premium TPM system present; present = [1]";
CM_ SG_ 1002 VC_AutoParkPrsnt "Automatic transmission parking feature is present; present = [1]";
CM_ SG_ 1002 VC_ADJ_PDL_PRSNT "Adjustable pedal system present (non-memory); present = [1]";
CM_ SG_ 1002 VC_AUTO_HL "Auto headlamp feature present; present = [1]";
CM_ SG_ 1002 VC_DrAlrPrsnt "Door alert feature present; present = [1]";
CM_ SG_ 1002 VC_WHL_BASE "Wheel base";
CM_ SG_ 1002 VC_FOBIKsafeENBL "Feature FOBIK safe is enabled; present = [1]";
CM_ SG_ 1002 VC_ELV_Prsnt "ELV system present; enabled=[1], disabled=[0]";
CM_ SG_ 1002 VC_FUEL_CAP "Fuel capacity";
CM_ SG_ 1002 VC_VehCfg3_Stat "Configuration messages status 3";
CM_ SG_ 1002 VC_POLICE "Police lighting feature; present = [1]";
CM_ SG_ 1002 VC_PWR_LFT_GT "Power lift gate present; present = [1]";
CM_ SG_ 1002 VC_PWR_RT_SLDR "Power right sliding door present; present = [1]";
CM_ SG_ 1002 VC_PWR_LT_SLDR "Power left sliding door present; present = [1]";
CM_ SG_ 1002 VC_RKE_PRSNT "RKE system present; present = [1]";
CM_ SG_ 1002 VC_TcaseTyp "Tcase type";
CM_ SG_ 1002 VC_PE_Prsnt "Feature passive entry is present; present = [1]";
CM_ SG_ 1002 VC_KG_Prsnt "Feature keyless go is present; present = [1]";
CM_ SG_ 1003 VC_TCASE_HI_RATIO "Transfer case high ratio";
CM_ SG_ 1003 VC_AXLE_RATIO "Axle ratio";
CM_ SG_ 1003 VC_TCASE_LO_RATIO "Transfer case low range reduction ratio";
CM_ SG_ 1003 VC_TIRE_CIRCUMF "Dynamic tire circumference (all or rear)";
CM_ SG_ 1003 VC_VehCfg4_Stat "Configuration messages status 4";
CM_ SG_ 1004 VC_BU_VehCfg1_Stat "Backup for Configuration messages status 1";
CM_ SG_ 1004 VC_BU_COUNTRY "Backup for Country Code";
CM_ SG_ 1004 VC_BU_MAX_VEH_SPD "Backup for Maximum vehicle speed";
CM_ SG_ 1004 VC_BU_PTS_DispTyp "PTS display type and location";
CM_ SG_ 1004 VC_BU_HdRstPrsnt "Backup for headrest present; present = [1]";
CM_ SG_ 1004 VC_BU_RVCM_Prsnt "Backup for rear view camera (1=present)";
CM_ SG_ 1004 VC_BU_SSC_Prsnt "Backup for Select speed control feature is present; present = [1]";
CM_ SG_ 1004 VC_BU_CHMCM_Prsnt "Backup for CHMSL camera (1=present)";
CM_ SG_ 1004 VC_BU_HDC_Prsnt "Backup for Hill descent feature is present; present = [1]";
CM_ SG_ 1004 VC_BU_SCR_Prsnt "Backup for Urea/SCR system present; present = [1]";
CM_ SG_ 1004 VC_BU_PTS_Config "Backup for Parktronics system configuration";
CM_ SG_ 1004 VC_BU_PP_Prsnt "Backup for Performance Pages Present (1=present)";
CM_ SG_ 1004 VC_BU_SpecialPKG "Special sales code package";
CM_ SG_ 1004 VC_BU_ShftrTyp "Shifter type";
CM_ SG_ 1004 VC_BU_LHD_RHD "Backup for Left/right hand drive";
CM_ SG_ 1004 VC_BU_RemStPrsnt "Backup for Remote start present; present = [1]";
CM_ SG_ 1004 VC_BU_XWD "Backup for Drive configuration";
CM_ SG_ 1004 VC_BU_EmodePrsnt "Backup for E-Mode feature present; True = [1]";
CM_ SG_ 1004 VC_BU_AUTO_HB "Backup for Auto Highbeam feature present; present = [1]";
CM_ SG_ 1004 VC_BU_BODY_STYLE "Backup for Body style";
CM_ SG_ 1004 VC_BU_MODEL_YEAR "Backup for Model year";
CM_ SG_ 1004 VC_BU_VEH_LINE "Backup for Vehicle line";
BA_DEF_ BO_  "App-Botschaft" ENUM  "nein","ja";
BA_DEF_ BO_  "CanMsgMinLen" INT 0 8;
BA_DEF_ BO_  "DiagRequest" ENUM  "nein","ja";
BA_DEF_ BO_  "DiagResponse" ENUM  "nein","ja";
BA_DEF_ BO_  "DiagState" ENUM  "nein","ja";
BA_DEF_ BO_  "GenMsgCycleTime" INT 0 65535;
BA_DEF_ BO_  "GenMsgCycleTimeActive" INT 0 65535;
BA_DEF_ BO_  "GenMsgDelayTime" INT 0 65535;
BA_DEF_ BO_  "GenMsgNrOfRepetitions" INT 0 65535;
BA_DEF_ BO_  "GenMsgSendType" ENUM  "cyclicX","spontanX","cyclicIfActiveX","spontanWithDelay","cyclicAndSpontanX","cyclicAndSpontanWithDelay","spontanWithRepitition","cyclicIfActiveAndSpontanWD","cyclicIfActiveFast","cyclicWithRepeatOnDemand","none";
BA_DEF_ BO_  "GenMsgStartDelayTime" INT 0 65535;
BA_DEF_ BO_  "GenMsgStartValue" STRING ;
BA_DEF_ BO_  "NWM-Botschaft" ENUM  "nein","ja";
BA_DEF_ BO_  "TpTxIndex" INT 0 99;
BA_DEF_ SG_  "FlexKomComment" STRING ;
BA_DEF_ SG_  "FlexKomIsMotorola" ENUM  "nein","ja";
BA_DEF_ SG_  "FlexKomSID" INT 0 2147483647;
BA_DEF_ SG_  "FlexKomSigLaenge" INT 0 64;
BA_DEF_ SG_  "FlexKomSigName" STRING ;
BA_DEF_ SG_  "FlexKomSigStartPos" INT 0 63;
BA_DEF_ SG_  "FlexKomSigStartValue" STRING ;
BA_DEF_ SG_  "GenSigCycleTime" INT 0 65535;
BA_DEF_ SG_  "GenSigCycleTimeActive" INT 0 65535;
BA_DEF_ SG_  "GenSigSendType" ENUM  "cyclicX","spontanX","cyclicIfActiveX","spontanWithDelay","cyclicAndSpontanX","cyclicAndSpontanWithDelay","spontanWithRepitition","cyclicIfActiveAndSpontanWD","cyclicIfActiveFast","cyclicWithRepeatOnDemand","none";
BA_DEF_ SG_  "GenSigSNA" STRING ;
BA_DEF_ SG_  "GenSigStartValue" HEX 0 2147483648;
BA_DEF_ SG_  "GenSigTimeout_AHLM" INT 0 65535;
BA_DEF_ SG_  "GenSigTimeout_ASBS" INT 0 65535;
BA_DEF_ SG_  "GenSigTimeout_CBC" INT 0 65535;
BA_DEF_ SG_  "GenSigTimeout_DPDM" INT 0 65535;
BA_DEF_ SG_  "GenSigTimeout_DTCM" INT 0 65535;
BA_DEF_ SG_  "GenSigTimeout_EHPS" INT 0 65535;
BA_DEF_ SG_  "GenSigTimeout_ESC" INT 0 65535;
BA_DEF_ SG_  "GenSigTimeout_ESL" INT 0 65535;
BA_DEF_ SG_  "GenSigTimeout_ESM" INT 0 65535;
BA_DEF_ SG_  "GenSigTimeout_ETM" INT 0 65535;
BA_DEF_ SG_  "GenSigTimeout_IC" INT 0 65535;
BA_DEF_ SG_  "GenSigTimeout_OCM" INT 0 65535;
BA_DEF_ SG_  "GenSigTimeout_ORC" INT 0 65535;
BA_DEF_ SG_  "GenSigTimeout_PTS" INT 0 65535;
BA_DEF_ SG_  "GenSigTimeout_RF_HUB" INT 0 65535;
BA_DEF_ SG_  "GenSigTimeout_SCCM" INT 0 65535;
BA_DEF_ SG_  "GenSigTimeout_TBM" INT 0 65535;
BA_DEF_ SG_  "GenSigTimeout_TCM" INT 0 65535;
BA_DEF_ SG_  "GenSigTimeout_TPM" INT 0 65535;
BA_DEF_ SG_  "RID" STRING ;
BA_DEF_ SG_  "SystemSignalLongSymbol" STRING ;
BA_DEF_DEF_  "App-Botschaft" "nein";
BA_DEF_DEF_  "CanMsgMinLen" 0;
BA_DEF_DEF_  "DiagRequest" "nein";
BA_DEF_DEF_  "DiagResponse" "nein";
BA_DEF_DEF_  "DiagState" "nein";
BA_DEF_DEF_  "GenMsgCycleTime" 0;
BA_DEF_DEF_  "GenMsgCycleTimeActive" 0;
BA_DEF_DEF_  "GenMsgDelayTime" 0;
BA_DEF_DEF_  "GenMsgNrOfRepetitions" 0;
BA_DEF_DEF_  "GenMsgSendType" "cyclicX";
BA_DEF_DEF_  "GenMsgStartDelayTime" 0;
BA_DEF_DEF_  "GenMsgStartValue" "";
BA_DEF_DEF_  "NWM-Botschaft" "nein";
BA_DEF_DEF_  "TpTxIndex" 0;
BA_DEF_DEF_  "FlexKomComment" "";
BA_DEF_DEF_  "FlexKomIsMotorola" "nein";
BA_DEF_DEF_  "FlexKomSID" 0;
BA_DEF_DEF_  "FlexKomSigLaenge" 0;
BA_DEF_DEF_  "FlexKomSigName" "";
BA_DEF_DEF_  "FlexKomSigStartPos" 0;
BA_DEF_DEF_  "FlexKomSigStartValue" "";
BA_DEF_DEF_  "GenSigCycleTime" 0;
BA_DEF_DEF_  "GenSigCycleTimeActive" 0;
BA_DEF_DEF_  "GenSigSendType" "cyclicX";
BA_DEF_DEF_  "GenSigSNA" "";
BA_DEF_DEF_  "GenSigStartValue" 0;
BA_DEF_DEF_  "GenSigTimeout_AHLM" 0;
BA_DEF_DEF_  "GenSigTimeout_ASBS" 0;
BA_DEF_DEF_  "GenSigTimeout_CBC" 0;
BA_DEF_DEF_  "GenSigTimeout_DPDM" 0;
BA_DEF_DEF_  "GenSigTimeout_DTCM" 0;
BA_DEF_DEF_  "GenSigTimeout_EHPS" 0;
BA_DEF_DEF_  "GenSigTimeout_ESC" 0;
BA_DEF_DEF_  "GenSigTimeout_ESL" 0;
BA_DEF_DEF_  "GenSigTimeout_ESM" 0;
BA_DEF_DEF_  "GenSigTimeout_ETM" 0;
BA_DEF_DEF_  "GenSigTimeout_IC" 0;
BA_DEF_DEF_  "GenSigTimeout_OCM" 0;
BA_DEF_DEF_  "GenSigTimeout_ORC" 0;
BA_DEF_DEF_  "GenSigTimeout_PTS" 0;
BA_DEF_DEF_  "GenSigTimeout_RF_HUB" 0;
BA_DEF_DEF_  "GenSigTimeout_SCCM" 0;
BA_DEF_DEF_  "GenSigTimeout_TBM" 0;
BA_DEF_DEF_  "GenSigTimeout_TCM" 0;
BA_DEF_DEF_  "GenSigTimeout_TPM" 0;
BA_DEF_DEF_  "RID" "";
BA_DEF_DEF_  "SystemSignalLongSymbol" "";
BA_ "GenMsgStartValue" BO_ 996 "0300000000000000h";
BA_ "GenMsgStartDelayTime" BO_ 996 10;
BA_ "GenMsgSendType" BO_ 996 5;
BA_ "GenMsgNrOfRepetitions" BO_ 996 2;
BA_ "GenMsgDelayTime" BO_ 996 20;
BA_ "GenMsgCycleTime" BO_ 996 2000;
BA_ "GenMsgStartValue" BO_ 998 "0300000000000000h";
BA_ "GenMsgSendType" BO_ 998 1;
BA_ "GenMsgNrOfRepetitions" BO_ 998 2;
BA_ "GenMsgDelayTime" BO_ 998 20;
BA_ "GenMsgStartValue" BO_ 999 "0300000000000000h";
BA_ "GenMsgSendType" BO_ 999 1;
BA_ "GenMsgNrOfRepetitions" BO_ 999 2;
BA_ "GenMsgDelayTime" BO_ 999 20;
BA_ "GenMsgStartValue" BO_ 1000 "FFFF7FF0FF0FFF00h";
BA_ "GenMsgStartDelayTime" BO_ 1000 50;
BA_ "GenMsgSendType" BO_ 1000 5;
BA_ "GenMsgNrOfRepetitions" BO_ 1000 2;
BA_ "GenMsgDelayTime" BO_ 1000 20;
BA_ "GenMsgCycleTime" BO_ 1000 500;
BA_ "GenMsgStartValue" BO_ 1001 "0300FF00FFFFFFFFh";
BA_ "GenMsgStartDelayTime" BO_ 1001 40;
BA_ "GenMsgSendType" BO_ 1001 5;
BA_ "GenMsgNrOfRepetitions" BO_ 1001 2;
BA_ "GenMsgDelayTime" BO_ 1001 20;
BA_ "GenMsgCycleTime" BO_ 1001 2000;
BA_ "GenMsgStartValue" BO_ 1002 "0370FF037FFF0000h";
BA_ "GenMsgStartDelayTime" BO_ 1002 50;
BA_ "GenMsgSendType" BO_ 1002 5;
BA_ "GenMsgNrOfRepetitions" BO_ 1002 2;
BA_ "GenMsgDelayTime" BO_ 1002 20;
BA_ "GenMsgCycleTime" BO_ 1002 2000;
BA_ "GenMsgStartValue" BO_ 1003 "FFFFFFFFFFFFFFFFh";
BA_ "GenMsgStartDelayTime" BO_ 1003 120;
BA_ "GenMsgSendType" BO_ 1003 5;
BA_ "GenMsgNrOfRepetitions" BO_ 1003 2;
BA_ "GenMsgDelayTime" BO_ 1003 20;
BA_ "GenMsgCycleTime" BO_ 1003 1000;
BA_ "GenMsgStartValue" BO_ 1004 "FFFF7FF0FF0FFF00h";
BA_ "GenMsgSendType" BO_ 1004 1;
BA_ "GenMsgNrOfRepetitions" BO_ 1004 2;
BA_ "GenMsgDelayTime" BO_ 1004 20;
BA_ "GenSigSNA" SG_ 996 NetCfg_TTPM "0h";
BA_ "GenSigSendType" SG_ 996 NetCfg_TTPM 5;
BA_ "GenSigCycleTime" SG_ 996 NetCfg_TTPM 2000;
BA_ "FlexKomSigStartValue" SG_ 996 NetCfg_TTPM "0300000000000000h";
BA_ "FlexKomSigStartPos" SG_ 996 NetCfg_TTPM 7;
BA_ "FlexKomSigName" SG_ 996 NetCfg_TTPM "NET_CFG_DATA_PT";
BA_ "FlexKomSigLaenge" SG_ 996 NetCfg_TTPM 64;
BA_ "FlexKomSID" SG_ 996 NetCfg_TTPM 39;
BA_ "FlexKomIsMotorola" SG_ 996 NetCfg_TTPM 1;
BA_ "FlexKomComment" SG_ 996 NetCfg_TTPM "Network ECU config data for Powertrain";
BA_ "GenSigSNA" SG_ 996 NetCfg_TIM "0h";
BA_ "GenSigSendType" SG_ 996 NetCfg_TIM 5;
BA_ "GenSigCycleTime" SG_ 996 NetCfg_TIM 2000;
BA_ "FlexKomSigStartValue" SG_ 996 NetCfg_TIM "0300000000000000h";
BA_ "FlexKomSigStartPos" SG_ 996 NetCfg_TIM 7;
BA_ "FlexKomSigName" SG_ 996 NetCfg_TIM "NET_CFG_DATA_PT";
BA_ "FlexKomSigLaenge" SG_ 996 NetCfg_TIM 64;
BA_ "FlexKomSID" SG_ 996 NetCfg_TIM 39;
BA_ "FlexKomIsMotorola" SG_ 996 NetCfg_TIM 1;
BA_ "FlexKomComment" SG_ 996 NetCfg_TIM "Network ECU config data for Powertrain";
BA_ "GenSigSNA" SG_ 996 NetCfg_DPDM "0h";
BA_ "GenSigSendType" SG_ 996 NetCfg_DPDM 5;
BA_ "GenSigCycleTime" SG_ 996 NetCfg_DPDM 2000;
BA_ "FlexKomSigStartValue" SG_ 996 NetCfg_DPDM "0300000000000000h";
BA_ "FlexKomSigStartPos" SG_ 996 NetCfg_DPDM 7;
BA_ "FlexKomSigName" SG_ 996 NetCfg_DPDM "NET_CFG_DATA_PT";
BA_ "FlexKomSigLaenge" SG_ 996 NetCfg_DPDM 64;
BA_ "FlexKomSID" SG_ 996 NetCfg_DPDM 39;
BA_ "FlexKomIsMotorola" SG_ 996 NetCfg_DPDM 1;
BA_ "FlexKomComment" SG_ 996 NetCfg_DPDM "Network ECU config data for Powertrain";
BA_ "GenSigSNA" SG_ 996 NetCfg_SGW "0h";
BA_ "GenSigSendType" SG_ 996 NetCfg_SGW 5;
BA_ "GenSigCycleTime" SG_ 996 NetCfg_SGW 2000;
BA_ "FlexKomSigStartValue" SG_ 996 NetCfg_SGW "0300000000000000h";
BA_ "FlexKomSigStartPos" SG_ 996 NetCfg_SGW 7;
BA_ "FlexKomSigName" SG_ 996 NetCfg_SGW "NET_CFG_DATA_PT";
BA_ "FlexKomSigLaenge" SG_ 996 NetCfg_SGW 64;
BA_ "FlexKomSID" SG_ 996 NetCfg_SGW 39;
BA_ "FlexKomIsMotorola" SG_ 996 NetCfg_SGW 1;
BA_ "FlexKomComment" SG_ 996 NetCfg_SGW "Network ECU config data for Powertrain";
BA_ "GenSigTimeout_ORC" SG_ 996 NetCfg_HCP 7000;
BA_ "GenSigSNA" SG_ 996 NetCfg_HCP "0h";
BA_ "GenSigSendType" SG_ 996 NetCfg_HCP 5;
BA_ "GenSigCycleTime" SG_ 996 NetCfg_HCP 2000;
BA_ "FlexKomSigStartValue" SG_ 996 NetCfg_HCP "0300000000000000h";
BA_ "FlexKomSigStartPos" SG_ 996 NetCfg_HCP 7;
BA_ "FlexKomSigName" SG_ 996 NetCfg_HCP "NET_CFG_DATA_PT";
BA_ "FlexKomSigLaenge" SG_ 996 NetCfg_HCP 64;
BA_ "FlexKomSID" SG_ 996 NetCfg_HCP 39;
BA_ "FlexKomIsMotorola" SG_ 996 NetCfg_HCP 1;
BA_ "FlexKomComment" SG_ 996 NetCfg_HCP "Network ECU config data for Powertrain";
BA_ "GenSigSNA" SG_ 996 NetCfg_ANC "0h";
BA_ "GenSigSendType" SG_ 996 NetCfg_ANC 5;
BA_ "GenSigCycleTime" SG_ 996 NetCfg_ANC 2000;
BA_ "FlexKomSigStartValue" SG_ 996 NetCfg_ANC "0300000000000000h";
BA_ "FlexKomSigStartPos" SG_ 996 NetCfg_ANC 7;
BA_ "FlexKomSigName" SG_ 996 NetCfg_ANC "NET_CFG_DATA_PT";
BA_ "FlexKomSigLaenge" SG_ 996 NetCfg_ANC 64;
BA_ "FlexKomSID" SG_ 996 NetCfg_ANC 39;
BA_ "FlexKomIsMotorola" SG_ 996 NetCfg_ANC 1;
BA_ "FlexKomComment" SG_ 996 NetCfg_ANC "Network ECU config data for Powertrain";
BA_ "GenSigTimeout_ORC" SG_ 996 NetCfg_GPF 7000;
BA_ "GenSigTimeout_OCM" SG_ 996 NetCfg_GPF 21000;
BA_ "GenSigTimeout_IC" SG_ 996 NetCfg_GPF 21000;
BA_ "GenSigTimeout_ESM" SG_ 996 NetCfg_GPF 21000;
BA_ "GenSigTimeout_EHPS" SG_ 996 NetCfg_GPF 21000;
BA_ "GenSigTimeout_DTCM" SG_ 996 NetCfg_GPF 21000;
BA_ "GenSigTimeout_DPDM" SG_ 996 NetCfg_GPF 21000;
BA_ "GenSigSNA" SG_ 996 NetCfg_GPF "0h";
BA_ "GenSigSendType" SG_ 996 NetCfg_GPF 5;
BA_ "GenSigCycleTime" SG_ 996 NetCfg_GPF 2000;
BA_ "FlexKomSigStartValue" SG_ 996 NetCfg_GPF "0300000000000000h";
BA_ "FlexKomSigStartPos" SG_ 996 NetCfg_GPF 7;
BA_ "FlexKomSigName" SG_ 996 NetCfg_GPF "NET_CFG_DATA_PT";
BA_ "FlexKomSigLaenge" SG_ 996 NetCfg_GPF 64;
BA_ "FlexKomSID" SG_ 996 NetCfg_GPF 39;
BA_ "FlexKomIsMotorola" SG_ 996 NetCfg_GPF 1;
BA_ "FlexKomComment" SG_ 996 NetCfg_GPF "Network ECU config data for Powertrain";
BA_ "GenSigTimeout_IC" SG_ 996 NetCfg_AFLS 21000;
BA_ "GenSigSNA" SG_ 996 NetCfg_AFLS "0h";
BA_ "GenSigSendType" SG_ 996 NetCfg_AFLS 5;
BA_ "GenSigCycleTime" SG_ 996 NetCfg_AFLS 2000;
BA_ "FlexKomSigStartValue" SG_ 996 NetCfg_AFLS "0300000000000000h";
BA_ "FlexKomSigStartPos" SG_ 996 NetCfg_AFLS 7;
BA_ "FlexKomSigName" SG_ 996 NetCfg_AFLS "NET_CFG_DATA_PT";
BA_ "FlexKomSigLaenge" SG_ 996 NetCfg_AFLS 64;
BA_ "FlexKomSID" SG_ 996 NetCfg_AFLS 39;
BA_ "FlexKomIsMotorola" SG_ 996 NetCfg_AFLS 1;
BA_ "FlexKomComment" SG_ 996 NetCfg_AFLS "Network ECU config data for Powertrain";
BA_ "GenSigTimeout_IC" SG_ 996 NetCfg_ITBM 21000;
BA_ "GenSigSNA" SG_ 996 NetCfg_ITBM "0h";
BA_ "GenSigSendType" SG_ 996 NetCfg_ITBM 5;
BA_ "GenSigCycleTime" SG_ 996 NetCfg_ITBM 2000;
BA_ "FlexKomSigStartValue" SG_ 996 NetCfg_ITBM "0300000000000000h";
BA_ "FlexKomSigStartPos" SG_ 996 NetCfg_ITBM 7;
BA_ "FlexKomSigName" SG_ 996 NetCfg_ITBM "NET_CFG_DATA_PT";
BA_ "FlexKomSigLaenge" SG_ 996 NetCfg_ITBM 64;
BA_ "FlexKomSID" SG_ 996 NetCfg_ITBM 39;
BA_ "FlexKomIsMotorola" SG_ 996 NetCfg_ITBM 1;
BA_ "FlexKomComment" SG_ 996 NetCfg_ITBM "Network ECU config data for Powertrain";
BA_ "GenSigTimeout_ORC" SG_ 996 NetCfg_OCM 7000;
BA_ "GenSigSNA" SG_ 996 NetCfg_OCM "0h";
BA_ "GenSigSendType" SG_ 996 NetCfg_OCM 5;
BA_ "GenSigCycleTime" SG_ 996 NetCfg_OCM 2000;
BA_ "FlexKomSigStartValue" SG_ 996 NetCfg_OCM "0300000000000000h";
BA_ "FlexKomSigStartPos" SG_ 996 NetCfg_OCM 7;
BA_ "FlexKomSigName" SG_ 996 NetCfg_OCM "NET_CFG_DATA_PT";
BA_ "FlexKomSigLaenge" SG_ 996 NetCfg_OCM 64;
BA_ "FlexKomSID" SG_ 996 NetCfg_OCM 39;
BA_ "FlexKomIsMotorola" SG_ 996 NetCfg_OCM 1;
BA_ "FlexKomComment" SG_ 996 NetCfg_OCM "Network ECU config data for Powertrain";
BA_ "GenSigSNA" SG_ 996 NetCfg_BSMO "0h";
BA_ "GenSigSendType" SG_ 996 NetCfg_BSMO 5;
BA_ "GenSigCycleTime" SG_ 996 NetCfg_BSMO 2000;
BA_ "FlexKomSigStartValue" SG_ 996 NetCfg_BSMO "0300000000000000h";
BA_ "FlexKomSigStartPos" SG_ 996 NetCfg_BSMO 7;
BA_ "FlexKomSigName" SG_ 996 NetCfg_BSMO "NET_CFG_DATA_PT";
BA_ "FlexKomSigLaenge" SG_ 996 NetCfg_BSMO 64;
BA_ "FlexKomSID" SG_ 996 NetCfg_BSMO 39;
BA_ "FlexKomIsMotorola" SG_ 996 NetCfg_BSMO 1;
BA_ "FlexKomComment" SG_ 996 NetCfg_BSMO "Network ECU config data for Powertrain";
BA_ "GenSigTimeout_IC" SG_ 996 NetCfg_ELSD 21000;
BA_ "GenSigSNA" SG_ 996 NetCfg_ELSD "0h";
BA_ "GenSigSendType" SG_ 996 NetCfg_ELSD 5;
BA_ "GenSigCycleTime" SG_ 996 NetCfg_ELSD 2000;
BA_ "FlexKomSigStartValue" SG_ 996 NetCfg_ELSD "0300000000000000h";
BA_ "FlexKomSigStartPos" SG_ 996 NetCfg_ELSD 7;
BA_ "FlexKomSigName" SG_ 996 NetCfg_ELSD "NET_CFG_DATA_PT";
BA_ "FlexKomSigLaenge" SG_ 996 NetCfg_ELSD 64;
BA_ "FlexKomSID" SG_ 996 NetCfg_ELSD 39;
BA_ "FlexKomIsMotorola" SG_ 996 NetCfg_ELSD 1;
BA_ "FlexKomComment" SG_ 996 NetCfg_ELSD "Network ECU config data for Powertrain";
BA_ "GenSigTimeout_ORC" SG_ 996 NetCfg_TCM 7000;
BA_ "GenSigTimeout_IC" SG_ 996 NetCfg_TCM 21000;
BA_ "GenSigTimeout_ESM" SG_ 996 NetCfg_TCM 21000;
BA_ "GenSigTimeout_DTCM" SG_ 996 NetCfg_TCM 21000;
BA_ "GenSigSNA" SG_ 996 NetCfg_TCM "0h";
BA_ "GenSigSendType" SG_ 996 NetCfg_TCM 5;
BA_ "GenSigCycleTime" SG_ 996 NetCfg_TCM 2000;
BA_ "FlexKomSigStartValue" SG_ 996 NetCfg_TCM "0300000000000000h";
BA_ "FlexKomSigStartPos" SG_ 996 NetCfg_TCM 7;
BA_ "FlexKomSigName" SG_ 996 NetCfg_TCM "NET_CFG_DATA_PT";
BA_ "FlexKomSigLaenge" SG_ 996 NetCfg_TCM 64;
BA_ "FlexKomSID" SG_ 996 NetCfg_TCM 39;
BA_ "FlexKomIsMotorola" SG_ 996 NetCfg_TCM 1;
BA_ "FlexKomComment" SG_ 996 NetCfg_TCM "Network ECU config data for Powertrain";
BA_ "GenSigTimeout_ORC" SG_ 996 NetCfg_TPM 7000;
BA_ "GenSigTimeout_IC" SG_ 996 NetCfg_TPM 21000;
BA_ "GenSigSNA" SG_ 996 NetCfg_TPM "0h";
BA_ "GenSigSendType" SG_ 996 NetCfg_TPM 5;
BA_ "GenSigCycleTime" SG_ 996 NetCfg_TPM 2000;
BA_ "FlexKomSigStartValue" SG_ 996 NetCfg_TPM "0300000000000000h";
BA_ "FlexKomSigStartPos" SG_ 996 NetCfg_TPM 7;
BA_ "FlexKomSigName" SG_ 996 NetCfg_TPM "NET_CFG_DATA_PT";
BA_ "FlexKomSigLaenge" SG_ 996 NetCfg_TPM 64;
BA_ "FlexKomSID" SG_ 996 NetCfg_TPM 39;
BA_ "FlexKomIsMotorola" SG_ 996 NetCfg_TPM 1;
BA_ "FlexKomComment" SG_ 996 NetCfg_TPM "Network ECU config data for Powertrain";
BA_ "GenSigTimeout_OCM" SG_ 996 NetCfg_ORC 21000;
BA_ "GenSigTimeout_IC" SG_ 996 NetCfg_ORC 21000;
BA_ "GenSigTimeout_DPDM" SG_ 996 NetCfg_ORC 21000;
BA_ "GenSigSNA" SG_ 996 NetCfg_ORC "0h";
BA_ "GenSigSendType" SG_ 996 NetCfg_ORC 5;
BA_ "GenSigCycleTime" SG_ 996 NetCfg_ORC 2000;
BA_ "FlexKomSigStartValue" SG_ 996 NetCfg_ORC "0300000000000000h";
BA_ "FlexKomSigStartPos" SG_ 996 NetCfg_ORC 7;
BA_ "FlexKomSigName" SG_ 996 NetCfg_ORC "NET_CFG_DATA_PT";
BA_ "FlexKomSigLaenge" SG_ 996 NetCfg_ORC 64;
BA_ "FlexKomSID" SG_ 996 NetCfg_ORC 39;
BA_ "FlexKomIsMotorola" SG_ 996 NetCfg_ORC 1;
BA_ "FlexKomComment" SG_ 996 NetCfg_ORC "Network ECU config data for Powertrain";
BA_ "GenSigTimeout_IC" SG_ 996 NetCfg_PTS 21000;
BA_ "GenSigSNA" SG_ 996 NetCfg_PTS "0h";
BA_ "GenSigSendType" SG_ 996 NetCfg_PTS 5;
BA_ "GenSigCycleTime" SG_ 996 NetCfg_PTS 2000;
BA_ "FlexKomSigStartValue" SG_ 996 NetCfg_PTS "0300000000000000h";
BA_ "FlexKomSigStartPos" SG_ 996 NetCfg_PTS 7;
BA_ "FlexKomSigName" SG_ 996 NetCfg_PTS "NET_CFG_DATA_PT";
BA_ "FlexKomSigLaenge" SG_ 996 NetCfg_PTS 64;
BA_ "FlexKomSID" SG_ 996 NetCfg_PTS 39;
BA_ "FlexKomIsMotorola" SG_ 996 NetCfg_PTS 1;
BA_ "FlexKomComment" SG_ 996 NetCfg_PTS "Network ECU config data for Powertrain";
BA_ "GenSigTimeout_ORC" SG_ 996 NetCfg_DASM 7000;
BA_ "GenSigTimeout_IC" SG_ 996 NetCfg_DASM 21000;
BA_ "GenSigSNA" SG_ 996 NetCfg_DASM "0h";
BA_ "GenSigSendType" SG_ 996 NetCfg_DASM 5;
BA_ "GenSigCycleTime" SG_ 996 NetCfg_DASM 2000;
BA_ "FlexKomSigStartValue" SG_ 996 NetCfg_DASM "0300000000000000h";
BA_ "FlexKomSigStartPos" SG_ 996 NetCfg_DASM 7;
BA_ "FlexKomSigName" SG_ 996 NetCfg_DASM "NET_CFG_DATA_PT";
BA_ "FlexKomSigLaenge" SG_ 996 NetCfg_DASM 64;
BA_ "FlexKomSID" SG_ 996 NetCfg_DASM 39;
BA_ "FlexKomIsMotorola" SG_ 996 NetCfg_DASM 1;
BA_ "FlexKomComment" SG_ 996 NetCfg_DASM "Network ECU config data for Powertrain";
BA_ "GenSigSNA" SG_ 996 NetCfg_FDCM "0h";
BA_ "GenSigSendType" SG_ 996 NetCfg_FDCM 5;
BA_ "GenSigCycleTime" SG_ 996 NetCfg_FDCM 2000;
BA_ "FlexKomSigStartValue" SG_ 996 NetCfg_FDCM "0300000000000000h";
BA_ "FlexKomSigStartPos" SG_ 996 NetCfg_FDCM 7;
BA_ "FlexKomSigName" SG_ 996 NetCfg_FDCM "NET_CFG_DATA_PT";
BA_ "FlexKomSigLaenge" SG_ 996 NetCfg_FDCM 64;
BA_ "FlexKomSID" SG_ 996 NetCfg_FDCM 39;
BA_ "FlexKomIsMotorola" SG_ 996 NetCfg_FDCM 1;
BA_ "FlexKomComment" SG_ 996 NetCfg_FDCM "Network ECU config data for Powertrain";
BA_ "GenSigTimeout_ORC" SG_ 996 NetCfg_ECM 7000;
BA_ "GenSigTimeout_OCM" SG_ 996 NetCfg_ECM 21000;
BA_ "GenSigTimeout_IC" SG_ 996 NetCfg_ECM 21000;
BA_ "GenSigTimeout_ESM" SG_ 996 NetCfg_ECM 21000;
BA_ "GenSigTimeout_EHPS" SG_ 996 NetCfg_ECM 21000;
BA_ "GenSigTimeout_DTCM" SG_ 996 NetCfg_ECM 21000;
BA_ "GenSigTimeout_DPDM" SG_ 996 NetCfg_ECM 21000;
BA_ "GenSigSNA" SG_ 996 NetCfg_ECM "0h";
BA_ "GenSigSendType" SG_ 996 NetCfg_ECM 5;
BA_ "GenSigCycleTime" SG_ 996 NetCfg_ECM 2000;
BA_ "FlexKomSigStartValue" SG_ 996 NetCfg_ECM "0300000000000000h";
BA_ "FlexKomSigStartPos" SG_ 996 NetCfg_ECM 7;
BA_ "FlexKomSigName" SG_ 996 NetCfg_ECM "NET_CFG_DATA_PT";
BA_ "FlexKomSigLaenge" SG_ 996 NetCfg_ECM 64;
BA_ "FlexKomSID" SG_ 996 NetCfg_ECM 39;
BA_ "FlexKomIsMotorola" SG_ 996 NetCfg_ECM 1;
BA_ "FlexKomComment" SG_ 996 NetCfg_ECM "Network ECU config data for Powertrain";
BA_ "GenSigTimeout_ORC" SG_ 996 NetCfg_EPS 7000;
BA_ "GenSigTimeout_IC" SG_ 996 NetCfg_EPS 21000;
BA_ "GenSigSNA" SG_ 996 NetCfg_EPS "0h";
BA_ "GenSigSendType" SG_ 996 NetCfg_EPS 5;
BA_ "GenSigCycleTime" SG_ 996 NetCfg_EPS 2000;
BA_ "FlexKomSigStartValue" SG_ 996 NetCfg_EPS "0300000000000000h";
BA_ "FlexKomSigStartPos" SG_ 996 NetCfg_EPS 7;
BA_ "FlexKomSigName" SG_ 996 NetCfg_EPS "NET_CFG_DATA_PT";
BA_ "FlexKomSigLaenge" SG_ 996 NetCfg_EPS 64;
BA_ "FlexKomSID" SG_ 996 NetCfg_EPS 39;
BA_ "FlexKomIsMotorola" SG_ 996 NetCfg_EPS 1;
BA_ "FlexKomComment" SG_ 996 NetCfg_EPS "Network ECU config data for Powertrain";
BA_ "GenSigTimeout_IC" SG_ 996 NetCfg_ESM 21000;
BA_ "GenSigTimeout_ESM" SG_ 996 NetCfg_ESM 21000;
BA_ "GenSigTimeout_DTCM" SG_ 996 NetCfg_ESM 21000;
BA_ "GenSigSNA" SG_ 996 NetCfg_ESM "0h";
BA_ "GenSigSendType" SG_ 996 NetCfg_ESM 5;
BA_ "GenSigCycleTime" SG_ 996 NetCfg_ESM 2000;
BA_ "FlexKomSigStartValue" SG_ 996 NetCfg_ESM "0300000000000000h";
BA_ "FlexKomSigStartPos" SG_ 996 NetCfg_ESM 7;
BA_ "FlexKomSigName" SG_ 996 NetCfg_ESM "NET_CFG_DATA_PT";
BA_ "FlexKomSigLaenge" SG_ 996 NetCfg_ESM 64;
BA_ "FlexKomSID" SG_ 996 NetCfg_ESM 39;
BA_ "FlexKomIsMotorola" SG_ 996 NetCfg_ESM 1;
BA_ "FlexKomComment" SG_ 996 NetCfg_ESM "Network ECU config data for Powertrain";
BA_ "GenSigTimeout_ORC" SG_ 996 NetCfg_ESC 7000;
BA_ "GenSigTimeout_IC" SG_ 996 NetCfg_ESC 21000;
BA_ "GenSigTimeout_ESM" SG_ 996 NetCfg_ESC 21000;
BA_ "GenSigTimeout_EHPS" SG_ 996 NetCfg_ESC 21000;
BA_ "GenSigTimeout_DTCM" SG_ 996 NetCfg_ESC 21000;
BA_ "GenSigSNA" SG_ 996 NetCfg_ESC "0h";
BA_ "GenSigSendType" SG_ 996 NetCfg_ESC 5;
BA_ "GenSigCycleTime" SG_ 996 NetCfg_ESC 2000;
BA_ "FlexKomSigStartValue" SG_ 996 NetCfg_ESC "0300000000000000h";
BA_ "FlexKomSigStartPos" SG_ 996 NetCfg_ESC 7;
BA_ "FlexKomSigName" SG_ 996 NetCfg_ESC "NET_CFG_DATA_PT";
BA_ "FlexKomSigLaenge" SG_ 996 NetCfg_ESC 64;
BA_ "FlexKomSID" SG_ 996 NetCfg_ESC 39;
BA_ "FlexKomIsMotorola" SG_ 996 NetCfg_ESC 1;
BA_ "FlexKomComment" SG_ 996 NetCfg_ESC "Network ECU config data for Powertrain";
BA_ "GenSigTimeout_ORC" SG_ 996 NetCfg_EPB 7000;
BA_ "GenSigTimeout_IC" SG_ 996 NetCfg_EPB 21000;
BA_ "GenSigSNA" SG_ 996 NetCfg_EPB "0h";
BA_ "GenSigSendType" SG_ 996 NetCfg_EPB 5;
BA_ "GenSigCycleTime" SG_ 996 NetCfg_EPB 2000;
BA_ "FlexKomSigStartValue" SG_ 996 NetCfg_EPB "0300000000000000h";
BA_ "FlexKomSigStartPos" SG_ 996 NetCfg_EPB 7;
BA_ "FlexKomSigName" SG_ 996 NetCfg_EPB "NET_CFG_DATA_PT";
BA_ "FlexKomSigLaenge" SG_ 996 NetCfg_EPB 64;
BA_ "FlexKomSID" SG_ 996 NetCfg_EPB 39;
BA_ "FlexKomIsMotorola" SG_ 996 NetCfg_EPB 1;
BA_ "FlexKomComment" SG_ 996 NetCfg_EPB "Network ECU config data for Powertrain";
BA_ "GenSigTimeout_IC" SG_ 996 NetCfg_RF_HUB 21000;
BA_ "GenSigSNA" SG_ 996 NetCfg_RF_HUB "0h";
BA_ "GenSigSendType" SG_ 996 NetCfg_RF_HUB 5;
BA_ "GenSigCycleTime" SG_ 996 NetCfg_RF_HUB 2000;
BA_ "FlexKomSigStartValue" SG_ 996 NetCfg_RF_HUB "0300000000000000h";
BA_ "FlexKomSigStartPos" SG_ 996 NetCfg_RF_HUB 7;
BA_ "FlexKomSigName" SG_ 996 NetCfg_RF_HUB "NET_CFG_DATA_PT";
BA_ "FlexKomSigLaenge" SG_ 996 NetCfg_RF_HUB 64;
BA_ "FlexKomSID" SG_ 996 NetCfg_RF_HUB 39;
BA_ "FlexKomIsMotorola" SG_ 996 NetCfg_RF_HUB 1;
BA_ "FlexKomComment" SG_ 996 NetCfg_RF_HUB "Network ECU config data for Powertrain";
BA_ "GenSigTimeout_ORC" SG_ 996 NetCfg_ADCM 7000;
BA_ "GenSigTimeout_IC" SG_ 996 NetCfg_ADCM 21000;
BA_ "GenSigSNA" SG_ 996 NetCfg_ADCM "0h";
BA_ "GenSigSendType" SG_ 996 NetCfg_ADCM 5;
BA_ "GenSigCycleTime" SG_ 996 NetCfg_ADCM 2000;
BA_ "FlexKomSigStartValue" SG_ 996 NetCfg_ADCM "0300000000000000h";
BA_ "FlexKomSigStartPos" SG_ 996 NetCfg_ADCM 7;
BA_ "FlexKomSigName" SG_ 996 NetCfg_ADCM "NET_CFG_DATA_PT";
BA_ "FlexKomSigLaenge" SG_ 996 NetCfg_ADCM 64;
BA_ "FlexKomSID" SG_ 996 NetCfg_ADCM 39;
BA_ "FlexKomIsMotorola" SG_ 996 NetCfg_ADCM 1;
BA_ "FlexKomComment" SG_ 996 NetCfg_ADCM "Network ECU config data for Powertrain";
BA_ "GenSigTimeout_IC" SG_ 996 NetCfg_AHLM 21000;
BA_ "GenSigSNA" SG_ 996 NetCfg_AHLM "0h";
BA_ "GenSigSendType" SG_ 996 NetCfg_AHLM 5;
BA_ "GenSigCycleTime" SG_ 996 NetCfg_AHLM 2000;
BA_ "FlexKomSigStartValue" SG_ 996 NetCfg_AHLM "0300000000000000h";
BA_ "FlexKomSigStartPos" SG_ 996 NetCfg_AHLM 7;
BA_ "FlexKomSigName" SG_ 996 NetCfg_AHLM "NET_CFG_DATA_PT";
BA_ "FlexKomSigLaenge" SG_ 996 NetCfg_AHLM 64;
BA_ "FlexKomSID" SG_ 996 NetCfg_AHLM 39;
BA_ "FlexKomIsMotorola" SG_ 996 NetCfg_AHLM 1;
BA_ "FlexKomComment" SG_ 996 NetCfg_AHLM "Network ECU config data for Powertrain";
BA_ "GenSigTimeout_IC" SG_ 996 NetCfg_VSIM_C 21000;
BA_ "GenSigSNA" SG_ 996 NetCfg_VSIM_C "0h";
BA_ "GenSigSendType" SG_ 996 NetCfg_VSIM_C 5;
BA_ "GenSigCycleTime" SG_ 996 NetCfg_VSIM_C 2000;
BA_ "FlexKomSigStartValue" SG_ 996 NetCfg_VSIM_C "0300000000000000h";
BA_ "FlexKomSigStartPos" SG_ 996 NetCfg_VSIM_C 7;
BA_ "FlexKomSigName" SG_ 996 NetCfg_VSIM_C "NET_CFG_DATA_PT";
BA_ "FlexKomSigLaenge" SG_ 996 NetCfg_VSIM_C 64;
BA_ "FlexKomSID" SG_ 996 NetCfg_VSIM_C 39;
BA_ "FlexKomIsMotorola" SG_ 996 NetCfg_VSIM_C 1;
BA_ "FlexKomComment" SG_ 996 NetCfg_VSIM_C "Network ECU config data for Powertrain";
BA_ "GenSigTimeout_IC" SG_ 996 NetCfg_ASCM 21000;
BA_ "GenSigSNA" SG_ 996 NetCfg_ASCM "0h";
BA_ "GenSigSendType" SG_ 996 NetCfg_ASCM 5;
BA_ "GenSigCycleTime" SG_ 996 NetCfg_ASCM 2000;
BA_ "FlexKomSigStartValue" SG_ 996 NetCfg_ASCM "0300000000000000h";
BA_ "FlexKomSigStartPos" SG_ 996 NetCfg_ASCM 7;
BA_ "FlexKomSigName" SG_ 996 NetCfg_ASCM "NET_CFG_DATA_PT";
BA_ "FlexKomSigLaenge" SG_ 996 NetCfg_ASCM 64;
BA_ "FlexKomSID" SG_ 996 NetCfg_ASCM 39;
BA_ "FlexKomIsMotorola" SG_ 996 NetCfg_ASCM 1;
BA_ "FlexKomComment" SG_ 996 NetCfg_ASCM "Network ECU config data for Powertrain";
BA_ "GenSigTimeout_ORC" SG_ 996 NetCfg_CBC_PT 7000;
BA_ "GenSigTimeout_OCM" SG_ 996 NetCfg_CBC_PT 21000;
BA_ "GenSigTimeout_IC" SG_ 996 NetCfg_CBC_PT 21000;
BA_ "GenSigTimeout_ESM" SG_ 996 NetCfg_CBC_PT 21000;
BA_ "GenSigTimeout_EHPS" SG_ 996 NetCfg_CBC_PT 21000;
BA_ "GenSigTimeout_DPDM" SG_ 996 NetCfg_CBC_PT 21000;
BA_ "GenSigSNA" SG_ 996 NetCfg_CBC_PT "0h";
BA_ "GenSigSendType" SG_ 996 NetCfg_CBC_PT 5;
BA_ "GenSigCycleTime" SG_ 996 NetCfg_CBC_PT 2000;
BA_ "FlexKomSigStartValue" SG_ 996 NetCfg_CBC_PT "0300000000000000h";
BA_ "FlexKomSigStartPos" SG_ 996 NetCfg_CBC_PT 7;
BA_ "FlexKomSigName" SG_ 996 NetCfg_CBC_PT "NET_CFG_DATA_PT";
BA_ "FlexKomSigLaenge" SG_ 996 NetCfg_CBC_PT 64;
BA_ "FlexKomSID" SG_ 996 NetCfg_CBC_PT 39;
BA_ "FlexKomIsMotorola" SG_ 996 NetCfg_CBC_PT 1;
BA_ "FlexKomComment" SG_ 996 NetCfg_CBC_PT "Network ECU config data for Powertrain";
BA_ "GenSigTimeout_ORC" SG_ 996 NET_CFG_STAT_PT 7000;
BA_ "GenSigTimeout_OCM" SG_ 996 NET_CFG_STAT_PT 21000;
BA_ "GenSigTimeout_IC" SG_ 996 NET_CFG_STAT_PT 21000;
BA_ "GenSigTimeout_ESM" SG_ 996 NET_CFG_STAT_PT 21000;
BA_ "GenSigTimeout_EHPS" SG_ 996 NET_CFG_STAT_PT 21000;
BA_ "GenSigTimeout_DTCM" SG_ 996 NET_CFG_STAT_PT 21000;
BA_ "GenSigTimeout_DPDM" SG_ 996 NET_CFG_STAT_PT 21000;
BA_ "GenSigStartValue" SG_ 996 NET_CFG_STAT_PT 3;
BA_ "GenSigSNA" SG_ 996 NET_CFG_STAT_PT "3h";
BA_ "GenSigSendType" SG_ 996 NET_CFG_STAT_PT 5;
BA_ "GenSigCycleTime" SG_ 996 NET_CFG_STAT_PT 2000;
BA_ "FlexKomSigStartValue" SG_ 996 NET_CFG_STAT_PT "0300000000000000h";
BA_ "FlexKomSigStartPos" SG_ 996 NET_CFG_STAT_PT 7;
BA_ "FlexKomSigName" SG_ 996 NET_CFG_STAT_PT "NET_CFG_DATA_PT";
BA_ "FlexKomSigLaenge" SG_ 996 NET_CFG_STAT_PT 64;
BA_ "FlexKomSID" SG_ 996 NET_CFG_STAT_PT 39;
BA_ "FlexKomIsMotorola" SG_ 996 NET_CFG_STAT_PT 1;
BA_ "FlexKomComment" SG_ 996 NET_CFG_STAT_PT "Network ECU config data for Powertrain";
BA_ "GenSigTimeout_IC" SG_ 996 NetCfg_ACC 21000;
BA_ "GenSigSNA" SG_ 996 NetCfg_ACC "0h";
BA_ "GenSigSendType" SG_ 996 NetCfg_ACC 5;
BA_ "GenSigCycleTime" SG_ 996 NetCfg_ACC 2000;
BA_ "FlexKomSigStartValue" SG_ 996 NetCfg_ACC "0300000000000000h";
BA_ "FlexKomSigStartPos" SG_ 996 NetCfg_ACC 7;
BA_ "FlexKomSigName" SG_ 996 NetCfg_ACC "NET_CFG_DATA_PT";
BA_ "FlexKomSigLaenge" SG_ 996 NetCfg_ACC 64;
BA_ "FlexKomSID" SG_ 996 NetCfg_ACC 39;
BA_ "FlexKomIsMotorola" SG_ 996 NetCfg_ACC 1;
BA_ "FlexKomComment" SG_ 996 NetCfg_ACC "Network ECU config data for Powertrain";
BA_ "GenSigTimeout_ORC" SG_ 996 NetCfg_DTCM 7000;
BA_ "GenSigTimeout_IC" SG_ 996 NetCfg_DTCM 21000;
BA_ "GenSigSNA" SG_ 996 NetCfg_DTCM "0h";
BA_ "GenSigSendType" SG_ 996 NetCfg_DTCM 5;
BA_ "GenSigCycleTime" SG_ 996 NetCfg_DTCM 2000;
BA_ "FlexKomSigStartValue" SG_ 996 NetCfg_DTCM "0300000000000000h";
BA_ "FlexKomSigStartPos" SG_ 996 NetCfg_DTCM 7;
BA_ "FlexKomSigName" SG_ 996 NetCfg_DTCM "NET_CFG_DATA_PT";
BA_ "FlexKomSigLaenge" SG_ 996 NetCfg_DTCM 64;
BA_ "FlexKomSID" SG_ 996 NetCfg_DTCM 39;
BA_ "FlexKomIsMotorola" SG_ 996 NetCfg_DTCM 1;
BA_ "FlexKomComment" SG_ 996 NetCfg_DTCM "Network ECU config data for Powertrain";
BA_ "GenSigTimeout_IC" SG_ 996 NetCfg_IC 21000;
BA_ "GenSigTimeout_ESM" SG_ 996 NetCfg_IC 21000;
BA_ "GenSigTimeout_EHPS" SG_ 996 NetCfg_IC 21000;
BA_ "GenSigSNA" SG_ 996 NetCfg_IC "0h";
BA_ "GenSigSendType" SG_ 996 NetCfg_IC 5;
BA_ "GenSigCycleTime" SG_ 996 NetCfg_IC 2000;
BA_ "FlexKomSigStartValue" SG_ 996 NetCfg_IC "0300000000000000h";
BA_ "FlexKomSigStartPos" SG_ 996 NetCfg_IC 7;
BA_ "FlexKomSigName" SG_ 996 NetCfg_IC "NET_CFG_DATA_PT";
BA_ "FlexKomSigLaenge" SG_ 996 NetCfg_IC 64;
BA_ "FlexKomSID" SG_ 996 NetCfg_IC 39;
BA_ "FlexKomIsMotorola" SG_ 996 NetCfg_IC 1;
BA_ "FlexKomComment" SG_ 996 NetCfg_IC "Network ECU config data for Powertrain";
BA_ "GenSigTimeout_ORC" SG_ 996 NetCfg_EPPM 7000;
BA_ "GenSigSNA" SG_ 996 NetCfg_EPPM "0h";
BA_ "GenSigSendType" SG_ 996 NetCfg_EPPM 5;
BA_ "GenSigCycleTime" SG_ 996 NetCfg_EPPM 2000;
BA_ "FlexKomSigStartValue" SG_ 996 NetCfg_EPPM "0300000000000000h";
BA_ "FlexKomSigStartPos" SG_ 996 NetCfg_EPPM 7;
BA_ "FlexKomSigName" SG_ 996 NetCfg_EPPM "NET_CFG_DATA_PT";
BA_ "FlexKomSigLaenge" SG_ 996 NetCfg_EPPM 64;
BA_ "FlexKomSID" SG_ 996 NetCfg_EPPM 39;
BA_ "FlexKomIsMotorola" SG_ 996 NetCfg_EPPM 1;
BA_ "FlexKomComment" SG_ 996 NetCfg_EPPM "Network ECU config data for Powertrain";
BA_ "GenSigTimeout_SCCM" SG_ 996 NetCfg_SCCM 21000;
BA_ "GenSigTimeout_ORC" SG_ 996 NetCfg_SCCM 7000;
BA_ "GenSigTimeout_IC" SG_ 996 NetCfg_SCCM 21000;
BA_ "GenSigTimeout_EHPS" SG_ 996 NetCfg_SCCM 21000;
BA_ "GenSigTimeout_DTCM" SG_ 996 NetCfg_SCCM 21000;
BA_ "GenSigSNA" SG_ 996 NetCfg_SCCM "0h";
BA_ "GenSigSendType" SG_ 996 NetCfg_SCCM 5;
BA_ "GenSigCycleTime" SG_ 996 NetCfg_SCCM 2000;
BA_ "FlexKomSigStartValue" SG_ 996 NetCfg_SCCM "0300000000000000h";
BA_ "FlexKomSigStartPos" SG_ 996 NetCfg_SCCM 7;
BA_ "FlexKomSigName" SG_ 996 NetCfg_SCCM "NET_CFG_DATA_PT";
BA_ "FlexKomSigLaenge" SG_ 996 NetCfg_SCCM 64;
BA_ "FlexKomSID" SG_ 996 NetCfg_SCCM 39;
BA_ "FlexKomIsMotorola" SG_ 996 NetCfg_SCCM 1;
BA_ "FlexKomComment" SG_ 996 NetCfg_SCCM "Network ECU config data for Powertrain";
BA_ "GenSigTimeout_IC" SG_ 996 NetCfg_PASS_PT 21000;
BA_ "GenSigSNA" SG_ 996 NetCfg_PASS_PT "0h";
BA_ "GenSigSendType" SG_ 996 NetCfg_PASS_PT 5;
BA_ "GenSigCycleTime" SG_ 996 NetCfg_PASS_PT 2000;
BA_ "FlexKomSigStartValue" SG_ 996 NetCfg_PASS_PT "0300000000000000h";
BA_ "FlexKomSigStartPos" SG_ 996 NetCfg_PASS_PT 7;
BA_ "FlexKomSigName" SG_ 996 NetCfg_PASS_PT "NET_CFG_DATA_PT";
BA_ "FlexKomSigLaenge" SG_ 996 NetCfg_PASS_PT 64;
BA_ "FlexKomSID" SG_ 996 NetCfg_PASS_PT 39;
BA_ "FlexKomIsMotorola" SG_ 996 NetCfg_PASS_PT 1;
BA_ "FlexKomComment" SG_ 996 NetCfg_PASS_PT "Network ECU config data for Powertrain";
BA_ "GenSigSNA" SG_ 996 NetCfg_HaLF "0h";
BA_ "GenSigSendType" SG_ 996 NetCfg_HaLF 5;
BA_ "GenSigCycleTime" SG_ 996 NetCfg_HaLF 2000;
BA_ "FlexKomSigStartValue" SG_ 996 NetCfg_HaLF "0300000000000000h";
BA_ "FlexKomSigStartPos" SG_ 996 NetCfg_HaLF 7;
BA_ "FlexKomSigName" SG_ 996 NetCfg_HaLF "NET_CFG_DATA_PT";
BA_ "FlexKomSigLaenge" SG_ 996 NetCfg_HaLF 64;
BA_ "FlexKomSID" SG_ 996 NetCfg_HaLF 39;
BA_ "FlexKomIsMotorola" SG_ 996 NetCfg_HaLF 1;
BA_ "FlexKomComment" SG_ 996 NetCfg_HaLF "Network ECU config data for Powertrain";
BA_ "GenSigTimeout_IC" SG_ 996 NetCfg_ASBS 21000;
BA_ "GenSigSNA" SG_ 996 NetCfg_ASBS "0h";
BA_ "GenSigSendType" SG_ 996 NetCfg_ASBS 5;
BA_ "GenSigCycleTime" SG_ 996 NetCfg_ASBS 2000;
BA_ "FlexKomSigStartValue" SG_ 996 NetCfg_ASBS "0300000000000000h";
BA_ "FlexKomSigStartPos" SG_ 996 NetCfg_ASBS 7;
BA_ "FlexKomSigName" SG_ 996 NetCfg_ASBS "NET_CFG_DATA_PT";
BA_ "FlexKomSigLaenge" SG_ 996 NetCfg_ASBS 64;
BA_ "FlexKomSID" SG_ 996 NetCfg_ASBS 39;
BA_ "FlexKomIsMotorola" SG_ 996 NetCfg_ASBS 1;
BA_ "FlexKomComment" SG_ 996 NetCfg_ASBS "Network ECU config data for Powertrain";
BA_ "GenSigSNA" SG_ 996 NetCfg_ESL "0h";
BA_ "GenSigSendType" SG_ 996 NetCfg_ESL 5;
BA_ "GenSigCycleTime" SG_ 996 NetCfg_ESL 2000;
BA_ "FlexKomSigStartValue" SG_ 996 NetCfg_ESL "0300000000000000h";
BA_ "FlexKomSigStartPos" SG_ 996 NetCfg_ESL 7;
BA_ "FlexKomSigName" SG_ 996 NetCfg_ESL "NET_CFG_DATA_PT";
BA_ "FlexKomSigLaenge" SG_ 996 NetCfg_ESL 64;
BA_ "FlexKomSID" SG_ 996 NetCfg_ESL 39;
BA_ "FlexKomIsMotorola" SG_ 996 NetCfg_ESL 1;
BA_ "FlexKomComment" SG_ 996 NetCfg_ESL "Network ECU config data for Powertrain";
BA_ "GenSigSNA" SG_ 996 NetCfg_EVCU2 "0h";
BA_ "GenSigSendType" SG_ 996 NetCfg_EVCU2 5;
BA_ "GenSigCycleTime" SG_ 996 NetCfg_EVCU2 2000;
BA_ "FlexKomSigStartValue" SG_ 996 NetCfg_EVCU2 "0300000000000000h";
BA_ "FlexKomSigStartPos" SG_ 996 NetCfg_EVCU2 7;
BA_ "FlexKomSigName" SG_ 996 NetCfg_EVCU2 "NET_CFG_DATA_PT";
BA_ "FlexKomSigLaenge" SG_ 996 NetCfg_EVCU2 64;
BA_ "FlexKomSID" SG_ 996 NetCfg_EVCU2 39;
BA_ "FlexKomIsMotorola" SG_ 996 NetCfg_EVCU2 1;
BA_ "FlexKomComment" SG_ 996 NetCfg_EVCU2 "Network ECU config data for Powertrain";
BA_ "GenSigSNA" SG_ 998 BU_NetCfg_TBM "0h";
BA_ "GenSigSendType" SG_ 998 BU_NetCfg_TBM 1;
BA_ "FlexKomSigStartValue" SG_ 998 BU_NetCfg_TBM "0300000000000000h";
BA_ "FlexKomSigStartPos" SG_ 998 BU_NetCfg_TBM 7;
BA_ "FlexKomSigName" SG_ 998 BU_NetCfg_TBM "BU_NET_CFG_DATA_INT";
BA_ "FlexKomSigLaenge" SG_ 998 BU_NetCfg_TBM 64;
BA_ "FlexKomSID" SG_ 998 BU_NetCfg_TBM 871;
BA_ "FlexKomIsMotorola" SG_ 998 BU_NetCfg_TBM 1;
BA_ "FlexKomComment" SG_ 998 BU_NetCfg_TBM "Backup for network ECU config data for interior";
BA_ "GenSigSNA" SG_ 998 BU_NetCfg_ANC_I "0h";
BA_ "GenSigSendType" SG_ 998 BU_NetCfg_ANC_I 1;
BA_ "FlexKomSigStartValue" SG_ 998 BU_NetCfg_ANC_I "0300000000000000h";
BA_ "FlexKomSigStartPos" SG_ 998 BU_NetCfg_ANC_I 7;
BA_ "FlexKomSigName" SG_ 998 BU_NetCfg_ANC_I "BU_NET_CFG_DATA_INT";
BA_ "FlexKomSigLaenge" SG_ 998 BU_NetCfg_ANC_I 64;
BA_ "FlexKomSID" SG_ 998 BU_NetCfg_ANC_I 871;
BA_ "FlexKomIsMotorola" SG_ 998 BU_NetCfg_ANC_I 1;
BA_ "FlexKomComment" SG_ 998 BU_NetCfg_ANC_I "Backup for network ECU config data for interior";
BA_ "GenSigSNA" SG_ 998 BU_NetCfg_UPFM "0h";
BA_ "GenSigSendType" SG_ 998 BU_NetCfg_UPFM 1;
BA_ "FlexKomSigStartValue" SG_ 998 BU_NetCfg_UPFM "0300000000000000h";
BA_ "FlexKomSigStartPos" SG_ 998 BU_NetCfg_UPFM 7;
BA_ "FlexKomSigName" SG_ 998 BU_NetCfg_UPFM "BU_NET_CFG_DATA_INT";
BA_ "FlexKomSigLaenge" SG_ 998 BU_NetCfg_UPFM 64;
BA_ "FlexKomSID" SG_ 998 BU_NetCfg_UPFM 871;
BA_ "FlexKomIsMotorola" SG_ 998 BU_NetCfg_UPFM 1;
BA_ "FlexKomComment" SG_ 998 BU_NetCfg_UPFM "Backup for network ECU config data for interior";
BA_ "GenSigSNA" SG_ 998 BU_NetCfg_TTM "0h";
BA_ "GenSigSendType" SG_ 998 BU_NetCfg_TTM 1;
BA_ "FlexKomSigStartValue" SG_ 998 BU_NetCfg_TTM "0300000000000000h";
BA_ "FlexKomSigStartPos" SG_ 998 BU_NetCfg_TTM 7;
BA_ "FlexKomSigName" SG_ 998 BU_NetCfg_TTM "BU_NET_CFG_DATA_INT";
BA_ "FlexKomSigLaenge" SG_ 998 BU_NetCfg_TTM 64;
BA_ "FlexKomSID" SG_ 998 BU_NetCfg_TTM 871;
BA_ "FlexKomIsMotorola" SG_ 998 BU_NetCfg_TTM 1;
BA_ "FlexKomComment" SG_ 998 BU_NetCfg_TTM "Backup for network ECU config data for interior";
BA_ "GenSigSNA" SG_ 998 BU_NetCfg_PSSM "0h";
BA_ "GenSigSendType" SG_ 998 BU_NetCfg_PSSM 1;
BA_ "FlexKomSigStartValue" SG_ 998 BU_NetCfg_PSSM "0300000000000000h";
BA_ "FlexKomSigStartPos" SG_ 998 BU_NetCfg_PSSM 7;
BA_ "FlexKomSigName" SG_ 998 BU_NetCfg_PSSM "BU_NET_CFG_DATA_INT";
BA_ "FlexKomSigLaenge" SG_ 998 BU_NetCfg_PSSM 64;
BA_ "FlexKomSID" SG_ 998 BU_NetCfg_PSSM 871;
BA_ "FlexKomIsMotorola" SG_ 998 BU_NetCfg_PSSM 1;
BA_ "FlexKomComment" SG_ 998 BU_NetCfg_PSSM "Backup for network ECU config data for interior";
BA_ "GenSigSNA" SG_ 998 BU_NetCfg_MSM_PASS "0h";
BA_ "GenSigSendType" SG_ 998 BU_NetCfg_MSM_PASS 1;
BA_ "FlexKomSigStartValue" SG_ 998 BU_NetCfg_MSM_PASS "0300000000000000h";
BA_ "FlexKomSigStartPos" SG_ 998 BU_NetCfg_MSM_PASS 7;
BA_ "FlexKomSigName" SG_ 998 BU_NetCfg_MSM_PASS "BU_NET_CFG_DATA_INT";
BA_ "FlexKomSigLaenge" SG_ 998 BU_NetCfg_MSM_PASS 64;
BA_ "FlexKomSID" SG_ 998 BU_NetCfg_MSM_PASS 871;
BA_ "FlexKomIsMotorola" SG_ 998 BU_NetCfg_MSM_PASS 1;
BA_ "FlexKomComment" SG_ 998 BU_NetCfg_MSM_PASS "Backup for network ECU config data for interior";
BA_ "GenSigSNA" SG_ 998 BU_NetCfg_VRM "0h";
BA_ "GenSigSendType" SG_ 998 BU_NetCfg_VRM 1;
BA_ "FlexKomSigStartValue" SG_ 998 BU_NetCfg_VRM "0300000000000000h";
BA_ "FlexKomSigStartPos" SG_ 998 BU_NetCfg_VRM 7;
BA_ "FlexKomSigName" SG_ 998 BU_NetCfg_VRM "BU_NET_CFG_DATA_INT";
BA_ "FlexKomSigLaenge" SG_ 998 BU_NetCfg_VRM 64;
BA_ "FlexKomSID" SG_ 998 BU_NetCfg_VRM 871;
BA_ "FlexKomIsMotorola" SG_ 998 BU_NetCfg_VRM 1;
BA_ "FlexKomComment" SG_ 998 BU_NetCfg_VRM "Backup for network ECU config data for interior";
BA_ "GenSigSNA" SG_ 998 BU_NetCfg_DCSD "0h";
BA_ "GenSigSendType" SG_ 998 BU_NetCfg_DCSD 1;
BA_ "FlexKomSigStartValue" SG_ 998 BU_NetCfg_DCSD "0300000000000000h";
BA_ "FlexKomSigStartPos" SG_ 998 BU_NetCfg_DCSD 7;
BA_ "FlexKomSigName" SG_ 998 BU_NetCfg_DCSD "BU_NET_CFG_DATA_INT";
BA_ "FlexKomSigLaenge" SG_ 998 BU_NetCfg_DCSD 64;
BA_ "FlexKomSID" SG_ 998 BU_NetCfg_DCSD 871;
BA_ "FlexKomIsMotorola" SG_ 998 BU_NetCfg_DCSD 1;
BA_ "FlexKomComment" SG_ 998 BU_NetCfg_DCSD "Backup for network ECU config data for interior";
BA_ "GenSigSNA" SG_ 998 BU_NetCfg_HVAC_R "0h";
BA_ "GenSigSendType" SG_ 998 BU_NetCfg_HVAC_R 1;
BA_ "FlexKomSigStartValue" SG_ 998 BU_NetCfg_HVAC_R "0300000000000000h";
BA_ "FlexKomSigStartPos" SG_ 998 BU_NetCfg_HVAC_R 7;
BA_ "FlexKomSigName" SG_ 998 BU_NetCfg_HVAC_R "BU_NET_CFG_DATA_INT";
BA_ "FlexKomSigLaenge" SG_ 998 BU_NetCfg_HVAC_R 64;
BA_ "FlexKomSID" SG_ 998 BU_NetCfg_HVAC_R 871;
BA_ "FlexKomIsMotorola" SG_ 998 BU_NetCfg_HVAC_R 1;
BA_ "FlexKomComment" SG_ 998 BU_NetCfg_HVAC_R "Backup for network ECU config data for interior";
BA_ "GenSigSNA" SG_ 998 BU_NetCfg_CVPM "0h";
BA_ "GenSigSendType" SG_ 998 BU_NetCfg_CVPM 1;
BA_ "FlexKomSigStartValue" SG_ 998 BU_NetCfg_CVPM "0300000000000000h";
BA_ "FlexKomSigStartPos" SG_ 998 BU_NetCfg_CVPM 7;
BA_ "FlexKomSigName" SG_ 998 BU_NetCfg_CVPM "BU_NET_CFG_DATA_INT";
BA_ "FlexKomSigLaenge" SG_ 998 BU_NetCfg_CVPM 64;
BA_ "FlexKomSID" SG_ 998 BU_NetCfg_CVPM 871;
BA_ "FlexKomIsMotorola" SG_ 998 BU_NetCfg_CVPM 1;
BA_ "FlexKomComment" SG_ 998 BU_NetCfg_CVPM "Backup for network ECU config data for interior";
BA_ "GenSigSNA" SG_ 998 BU_NetCfg_TMM "0h";
BA_ "GenSigSendType" SG_ 998 BU_NetCfg_TMM 1;
BA_ "FlexKomSigStartValue" SG_ 998 BU_NetCfg_TMM "0300000000000000h";
BA_ "FlexKomSigStartPos" SG_ 998 BU_NetCfg_TMM 7;
BA_ "FlexKomSigName" SG_ 998 BU_NetCfg_TMM "BU_NET_CFG_DATA_INT";
BA_ "FlexKomSigLaenge" SG_ 998 BU_NetCfg_TMM 64;
BA_ "FlexKomSID" SG_ 998 BU_NetCfg_TMM 871;
BA_ "FlexKomIsMotorola" SG_ 998 BU_NetCfg_TMM 1;
BA_ "FlexKomComment" SG_ 998 BU_NetCfg_TMM "Backup for network ECU config data for interior";
BA_ "GenSigSNA" SG_ 998 BU_NetCfg_HFM_CTM "0h";
BA_ "GenSigSendType" SG_ 998 BU_NetCfg_HFM_CTM 1;
BA_ "FlexKomSigStartValue" SG_ 998 BU_NetCfg_HFM_CTM "0300000000000000h";
BA_ "FlexKomSigStartPos" SG_ 998 BU_NetCfg_HFM_CTM 7;
BA_ "FlexKomSigName" SG_ 998 BU_NetCfg_HFM_CTM "BU_NET_CFG_DATA_INT";
BA_ "FlexKomSigLaenge" SG_ 998 BU_NetCfg_HFM_CTM 64;
BA_ "FlexKomSID" SG_ 998 BU_NetCfg_HFM_CTM 871;
BA_ "FlexKomIsMotorola" SG_ 998 BU_NetCfg_HFM_CTM 1;
BA_ "FlexKomComment" SG_ 998 BU_NetCfg_HFM_CTM "Backup for network ECU config data for interior";
BA_ "GenSigSNA" SG_ 998 BU_NetCfg_ICS_I "0h";
BA_ "GenSigSendType" SG_ 998 BU_NetCfg_ICS_I 1;
BA_ "FlexKomSigStartValue" SG_ 998 BU_NetCfg_ICS_I "0300000000000000h";
BA_ "FlexKomSigStartPos" SG_ 998 BU_NetCfg_ICS_I 7;
BA_ "FlexKomSigName" SG_ 998 BU_NetCfg_ICS_I "BU_NET_CFG_DATA_INT";
BA_ "FlexKomSigLaenge" SG_ 998 BU_NetCfg_ICS_I 64;
BA_ "FlexKomSID" SG_ 998 BU_NetCfg_ICS_I 871;
BA_ "FlexKomIsMotorola" SG_ 998 BU_NetCfg_ICS_I 1;
BA_ "FlexKomComment" SG_ 998 BU_NetCfg_ICS_I "Backup for network ECU config data for interior";
BA_ "GenSigSNA" SG_ 998 BU_NetCfg_VES2_I "0h";
BA_ "GenSigSendType" SG_ 998 BU_NetCfg_VES2_I 1;
BA_ "FlexKomSigStartValue" SG_ 998 BU_NetCfg_VES2_I "0300000000000000h";
BA_ "FlexKomSigStartPos" SG_ 998 BU_NetCfg_VES2_I 7;
BA_ "FlexKomSigName" SG_ 998 BU_NetCfg_VES2_I "BU_NET_CFG_DATA_INT";
BA_ "FlexKomSigLaenge" SG_ 998 BU_NetCfg_VES2_I 64;
BA_ "FlexKomSID" SG_ 998 BU_NetCfg_VES2_I 871;
BA_ "FlexKomIsMotorola" SG_ 998 BU_NetCfg_VES2_I 1;
BA_ "FlexKomComment" SG_ 998 BU_NetCfg_VES2_I "Backup for network ECU config data for interior";
BA_ "GenSigSNA" SG_ 998 BU_NetCfg_VES3_I "0h";
BA_ "GenSigSendType" SG_ 998 BU_NetCfg_VES3_I 1;
BA_ "FlexKomSigStartValue" SG_ 998 BU_NetCfg_VES3_I "0300000000000000h";
BA_ "FlexKomSigStartPos" SG_ 998 BU_NetCfg_VES3_I 7;
BA_ "FlexKomSigName" SG_ 998 BU_NetCfg_VES3_I "BU_NET_CFG_DATA_INT";
BA_ "FlexKomSigLaenge" SG_ 998 BU_NetCfg_VES3_I 64;
BA_ "FlexKomSID" SG_ 998 BU_NetCfg_VES3_I 871;
BA_ "FlexKomIsMotorola" SG_ 998 BU_NetCfg_VES3_I 1;
BA_ "FlexKomComment" SG_ 998 BU_NetCfg_VES3_I "Backup for network ECU config data for interior";
BA_ "GenSigSNA" SG_ 998 BU_NetCfg_AMP_I "0h";
BA_ "GenSigSendType" SG_ 998 BU_NetCfg_AMP_I 1;
BA_ "FlexKomSigStartValue" SG_ 998 BU_NetCfg_AMP_I "0300000000000000h";
BA_ "FlexKomSigStartPos" SG_ 998 BU_NetCfg_AMP_I 7;
BA_ "FlexKomSigName" SG_ 998 BU_NetCfg_AMP_I "BU_NET_CFG_DATA_INT";
BA_ "FlexKomSigLaenge" SG_ 998 BU_NetCfg_AMP_I 64;
BA_ "FlexKomSID" SG_ 998 BU_NetCfg_AMP_I 871;
BA_ "FlexKomIsMotorola" SG_ 998 BU_NetCfg_AMP_I 1;
BA_ "FlexKomComment" SG_ 998 BU_NetCfg_AMP_I "Backup for network ECU config data for interior";
BA_ "GenSigSNA" SG_ 998 BU_NetCfg_CLOCK "0h";
BA_ "GenSigSendType" SG_ 998 BU_NetCfg_CLOCK 1;
BA_ "FlexKomSigStartValue" SG_ 998 BU_NetCfg_CLOCK "0300000000000000h";
BA_ "FlexKomSigStartPos" SG_ 998 BU_NetCfg_CLOCK 7;
BA_ "FlexKomSigName" SG_ 998 BU_NetCfg_CLOCK "BU_NET_CFG_DATA_INT";
BA_ "FlexKomSigLaenge" SG_ 998 BU_NetCfg_CLOCK 64;
BA_ "FlexKomSID" SG_ 998 BU_NetCfg_CLOCK 871;
BA_ "FlexKomIsMotorola" SG_ 998 BU_NetCfg_CLOCK 1;
BA_ "FlexKomComment" SG_ 998 BU_NetCfg_CLOCK "Backup for network ECU config data for interior";
BA_ "GenSigSNA" SG_ 998 BU_NetCfg_VSIM "0h";
BA_ "GenSigSendType" SG_ 998 BU_NetCfg_VSIM 1;
BA_ "FlexKomSigStartValue" SG_ 998 BU_NetCfg_VSIM "0300000000000000h";
BA_ "FlexKomSigStartPos" SG_ 998 BU_NetCfg_VSIM 7;
BA_ "FlexKomSigName" SG_ 998 BU_NetCfg_VSIM "BU_NET_CFG_DATA_INT";
BA_ "FlexKomSigLaenge" SG_ 998 BU_NetCfg_VSIM 64;
BA_ "FlexKomSID" SG_ 998 BU_NetCfg_VSIM 871;
BA_ "FlexKomIsMotorola" SG_ 998 BU_NetCfg_VSIM 1;
BA_ "FlexKomComment" SG_ 998 BU_NetCfg_VSIM "Backup for network ECU config data for interior";
BA_ "GenSigSNA" SG_ 998 BU_NetCfg_DTV "0h";
BA_ "GenSigSendType" SG_ 998 BU_NetCfg_DTV 1;
BA_ "FlexKomSigStartValue" SG_ 998 BU_NetCfg_DTV "0300000000000000h";
BA_ "FlexKomSigStartPos" SG_ 998 BU_NetCfg_DTV 7;
BA_ "FlexKomSigName" SG_ 998 BU_NetCfg_DTV "BU_NET_CFG_DATA_INT";
BA_ "FlexKomSigLaenge" SG_ 998 BU_NetCfg_DTV 64;
BA_ "FlexKomSID" SG_ 998 BU_NetCfg_DTV 871;
BA_ "FlexKomIsMotorola" SG_ 998 BU_NetCfg_DTV 1;
BA_ "FlexKomComment" SG_ 998 BU_NetCfg_DTV "Backup for network ECU config data for interior";
BA_ "GenSigSNA" SG_ 998 BU_NetCfg_FSM "0h";
BA_ "GenSigSendType" SG_ 998 BU_NetCfg_FSM 1;
BA_ "FlexKomSigStartValue" SG_ 998 BU_NetCfg_FSM "0300000000000000h";
BA_ "FlexKomSigStartPos" SG_ 998 BU_NetCfg_FSM 7;
BA_ "FlexKomSigName" SG_ 998 BU_NetCfg_FSM "BU_NET_CFG_DATA_INT";
BA_ "FlexKomSigLaenge" SG_ 998 BU_NetCfg_FSM 64;
BA_ "FlexKomSID" SG_ 998 BU_NetCfg_FSM 871;
BA_ "FlexKomIsMotorola" SG_ 998 BU_NetCfg_FSM 1;
BA_ "FlexKomComment" SG_ 998 BU_NetCfg_FSM "Backup for network ECU config data for interior";
BA_ "GenSigSNA" SG_ 998 BU_NetCfg_PTCM "0h";
BA_ "GenSigSendType" SG_ 998 BU_NetCfg_PTCM 1;
BA_ "FlexKomSigStartValue" SG_ 998 BU_NetCfg_PTCM "0300000000000000h";
BA_ "FlexKomSigStartPos" SG_ 998 BU_NetCfg_PTCM 7;
BA_ "FlexKomSigName" SG_ 998 BU_NetCfg_PTCM "BU_NET_CFG_DATA_INT";
BA_ "FlexKomSigLaenge" SG_ 998 BU_NetCfg_PTCM 64;
BA_ "FlexKomSID" SG_ 998 BU_NetCfg_PTCM 871;
BA_ "FlexKomIsMotorola" SG_ 998 BU_NetCfg_PTCM 1;
BA_ "FlexKomComment" SG_ 998 BU_NetCfg_PTCM "Backup for network ECU config data for interior";
BA_ "GenSigSNA" SG_ 998 BU_NetCfg_DCM_RR "0h";
BA_ "GenSigSendType" SG_ 998 BU_NetCfg_DCM_RR 1;
BA_ "FlexKomSigStartValue" SG_ 998 BU_NetCfg_DCM_RR "0300000000000000h";
BA_ "FlexKomSigStartPos" SG_ 998 BU_NetCfg_DCM_RR 7;
BA_ "FlexKomSigName" SG_ 998 BU_NetCfg_DCM_RR "BU_NET_CFG_DATA_INT";
BA_ "FlexKomSigLaenge" SG_ 998 BU_NetCfg_DCM_RR 64;
BA_ "FlexKomSID" SG_ 998 BU_NetCfg_DCM_RR 871;
BA_ "FlexKomIsMotorola" SG_ 998 BU_NetCfg_DCM_RR 1;
BA_ "FlexKomComment" SG_ 998 BU_NetCfg_DCM_RR "Backup for network ECU config data for interior";
BA_ "GenSigSNA" SG_ 998 BU_NetCfg_HVAC "0h";
BA_ "GenSigSendType" SG_ 998 BU_NetCfg_HVAC 1;
BA_ "FlexKomSigStartValue" SG_ 998 BU_NetCfg_HVAC "0300000000000000h";
BA_ "FlexKomSigStartPos" SG_ 998 BU_NetCfg_HVAC 7;
BA_ "FlexKomSigName" SG_ 998 BU_NetCfg_HVAC "BU_NET_CFG_DATA_INT";
BA_ "FlexKomSigLaenge" SG_ 998 BU_NetCfg_HVAC 64;
BA_ "FlexKomSID" SG_ 998 BU_NetCfg_HVAC 871;
BA_ "FlexKomIsMotorola" SG_ 998 BU_NetCfg_HVAC 1;
BA_ "FlexKomComment" SG_ 998 BU_NetCfg_HVAC "Backup for network ECU config data for interior";
BA_ "GenSigSNA" SG_ 998 BU_NetCfg_MSM "0h";
BA_ "GenSigSendType" SG_ 998 BU_NetCfg_MSM 1;
BA_ "FlexKomSigStartValue" SG_ 998 BU_NetCfg_MSM "0300000000000000h";
BA_ "FlexKomSigStartPos" SG_ 998 BU_NetCfg_MSM 7;
BA_ "FlexKomSigName" SG_ 998 BU_NetCfg_MSM "BU_NET_CFG_DATA_INT";
BA_ "FlexKomSigLaenge" SG_ 998 BU_NetCfg_MSM 64;
BA_ "FlexKomSID" SG_ 998 BU_NetCfg_MSM 871;
BA_ "FlexKomIsMotorola" SG_ 998 BU_NetCfg_MSM 1;
BA_ "FlexKomComment" SG_ 998 BU_NetCfg_MSM "Backup for network ECU config data for interior";
BA_ "GenSigSNA" SG_ 998 BU_NetCfg_PLG "0h";
BA_ "GenSigSendType" SG_ 998 BU_NetCfg_PLG 1;
BA_ "FlexKomSigStartValue" SG_ 998 BU_NetCfg_PLG "0300000000000000h";
BA_ "FlexKomSigStartPos" SG_ 998 BU_NetCfg_PLG 7;
BA_ "FlexKomSigName" SG_ 998 BU_NetCfg_PLG "BU_NET_CFG_DATA_INT";
BA_ "FlexKomSigLaenge" SG_ 998 BU_NetCfg_PLG 64;
BA_ "FlexKomSID" SG_ 998 BU_NetCfg_PLG 871;
BA_ "FlexKomIsMotorola" SG_ 998 BU_NetCfg_PLG 1;
BA_ "FlexKomComment" SG_ 998 BU_NetCfg_PLG "Backup for network ECU config data for interior";
BA_ "GenSigSNA" SG_ 998 BU_NetCfg_VTM "0h";
BA_ "GenSigSendType" SG_ 998 BU_NetCfg_VTM 1;
BA_ "FlexKomSigStartValue" SG_ 998 BU_NetCfg_VTM "0300000000000000h";
BA_ "FlexKomSigStartPos" SG_ 998 BU_NetCfg_VTM 7;
BA_ "FlexKomSigName" SG_ 998 BU_NetCfg_VTM "BU_NET_CFG_DATA_INT";
BA_ "FlexKomSigLaenge" SG_ 998 BU_NetCfg_VTM 64;
BA_ "FlexKomSID" SG_ 998 BU_NetCfg_VTM 871;
BA_ "FlexKomIsMotorola" SG_ 998 BU_NetCfg_VTM 1;
BA_ "FlexKomComment" SG_ 998 BU_NetCfg_VTM "Backup for network ECU config data for interior";
BA_ "GenSigSNA" SG_ 998 BU_NetCfg_PSD_LT "0h";
BA_ "GenSigSendType" SG_ 998 BU_NetCfg_PSD_LT 1;
BA_ "FlexKomSigStartValue" SG_ 998 BU_NetCfg_PSD_LT "0300000000000000h";
BA_ "FlexKomSigStartPos" SG_ 998 BU_NetCfg_PSD_LT 7;
BA_ "FlexKomSigName" SG_ 998 BU_NetCfg_PSD_LT "BU_NET_CFG_DATA_INT";
BA_ "FlexKomSigLaenge" SG_ 998 BU_NetCfg_PSD_LT 64;
BA_ "FlexKomSID" SG_ 998 BU_NetCfg_PSD_LT 871;
BA_ "FlexKomIsMotorola" SG_ 998 BU_NetCfg_PSD_LT 1;
BA_ "FlexKomComment" SG_ 998 BU_NetCfg_PSD_LT "Backup for network ECU config data for interior";
BA_ "GenSigSNA" SG_ 998 BU_NetCfg_DCM_RL "0h";
BA_ "GenSigSendType" SG_ 998 BU_NetCfg_DCM_RL 1;
BA_ "FlexKomSigStartValue" SG_ 998 BU_NetCfg_DCM_RL "0300000000000000h";
BA_ "FlexKomSigStartPos" SG_ 998 BU_NetCfg_DCM_RL 7;
BA_ "FlexKomSigName" SG_ 998 BU_NetCfg_DCM_RL "BU_NET_CFG_DATA_INT";
BA_ "FlexKomSigLaenge" SG_ 998 BU_NetCfg_DCM_RL 64;
BA_ "FlexKomSID" SG_ 998 BU_NetCfg_DCM_RL 871;
BA_ "FlexKomIsMotorola" SG_ 998 BU_NetCfg_DCM_RL 1;
BA_ "FlexKomComment" SG_ 998 BU_NetCfg_DCM_RL "Backup for network ECU config data for interior";
BA_ "GenSigSNA" SG_ 998 BU_NetCfg_PSD_RT "0h";
BA_ "GenSigSendType" SG_ 998 BU_NetCfg_PSD_RT 1;
BA_ "FlexKomSigStartValue" SG_ 998 BU_NetCfg_PSD_RT "0300000000000000h";
BA_ "FlexKomSigStartPos" SG_ 998 BU_NetCfg_PSD_RT 7;
BA_ "FlexKomSigName" SG_ 998 BU_NetCfg_PSD_RT "BU_NET_CFG_DATA_INT";
BA_ "FlexKomSigLaenge" SG_ 998 BU_NetCfg_PSD_RT 64;
BA_ "FlexKomSID" SG_ 998 BU_NetCfg_PSD_RT 871;
BA_ "FlexKomIsMotorola" SG_ 998 BU_NetCfg_PSD_RT 1;
BA_ "FlexKomComment" SG_ 998 BU_NetCfg_PSD_RT "Backup for network ECU config data for interior";
BA_ "GenSigSNA" SG_ 998 BU_NetCfg_RBC "0h";
BA_ "GenSigSendType" SG_ 998 BU_NetCfg_RBC 1;
BA_ "FlexKomSigStartValue" SG_ 998 BU_NetCfg_RBC "0300000000000000h";
BA_ "FlexKomSigStartPos" SG_ 998 BU_NetCfg_RBC 7;
BA_ "FlexKomSigName" SG_ 998 BU_NetCfg_RBC "BU_NET_CFG_DATA_INT";
BA_ "FlexKomSigLaenge" SG_ 998 BU_NetCfg_RBC 64;
BA_ "FlexKomSID" SG_ 998 BU_NetCfg_RBC 871;
BA_ "FlexKomIsMotorola" SG_ 998 BU_NetCfg_RBC 1;
BA_ "FlexKomComment" SG_ 998 BU_NetCfg_RBC "Backup for network ECU config data for interior";
BA_ "GenSigSNA" SG_ 998 BU_NetCfg_RBSS "0h";
BA_ "GenSigSendType" SG_ 998 BU_NetCfg_RBSS 1;
BA_ "FlexKomSigStartValue" SG_ 998 BU_NetCfg_RBSS "0300000000000000h";
BA_ "FlexKomSigStartPos" SG_ 998 BU_NetCfg_RBSS 7;
BA_ "FlexKomSigName" SG_ 998 BU_NetCfg_RBSS "BU_NET_CFG_DATA_INT";
BA_ "FlexKomSigLaenge" SG_ 998 BU_NetCfg_RBSS 64;
BA_ "FlexKomSID" SG_ 998 BU_NetCfg_RBSS 871;
BA_ "FlexKomIsMotorola" SG_ 998 BU_NetCfg_RBSS 1;
BA_ "FlexKomComment" SG_ 998 BU_NetCfg_RBSS "Backup for network ECU config data for interior";
BA_ "GenSigSNA" SG_ 998 BU_NetCfg_BSM "0h";
BA_ "GenSigSendType" SG_ 998 BU_NetCfg_BSM 1;
BA_ "FlexKomSigStartValue" SG_ 998 BU_NetCfg_BSM "0300000000000000h";
BA_ "FlexKomSigStartPos" SG_ 998 BU_NetCfg_BSM 7;
BA_ "FlexKomSigName" SG_ 998 BU_NetCfg_BSM "BU_NET_CFG_DATA_INT";
BA_ "FlexKomSigLaenge" SG_ 998 BU_NetCfg_BSM 64;
BA_ "FlexKomSID" SG_ 998 BU_NetCfg_BSM 871;
BA_ "FlexKomIsMotorola" SG_ 998 BU_NetCfg_BSM 1;
BA_ "FlexKomComment" SG_ 998 BU_NetCfg_BSM "Backup for network ECU config data for interior";
BA_ "GenSigSNA" SG_ 998 BU_NetCfg_CBC_IN "0h";
BA_ "GenSigSendType" SG_ 998 BU_NetCfg_CBC_IN 1;
BA_ "FlexKomSigStartValue" SG_ 998 BU_NetCfg_CBC_IN "0300000000000000h";
BA_ "FlexKomSigStartPos" SG_ 998 BU_NetCfg_CBC_IN 7;
BA_ "FlexKomSigName" SG_ 998 BU_NetCfg_CBC_IN "BU_NET_CFG_DATA_INT";
BA_ "FlexKomSigLaenge" SG_ 998 BU_NetCfg_CBC_IN 64;
BA_ "FlexKomSID" SG_ 998 BU_NetCfg_CBC_IN 871;
BA_ "FlexKomIsMotorola" SG_ 998 BU_NetCfg_CBC_IN 1;
BA_ "FlexKomComment" SG_ 998 BU_NetCfg_CBC_IN "Backup for network ECU config data for interior";
BA_ "GenSigSNA" SG_ 998 BU_NetCfg_CSWM "0h";
BA_ "GenSigSendType" SG_ 998 BU_NetCfg_CSWM 1;
BA_ "FlexKomSigStartValue" SG_ 998 BU_NetCfg_CSWM "0300000000000000h";
BA_ "FlexKomSigStartPos" SG_ 998 BU_NetCfg_CSWM 7;
BA_ "FlexKomSigName" SG_ 998 BU_NetCfg_CSWM "BU_NET_CFG_DATA_INT";
BA_ "FlexKomSigLaenge" SG_ 998 BU_NetCfg_CSWM 64;
BA_ "FlexKomSID" SG_ 998 BU_NetCfg_CSWM 871;
BA_ "FlexKomIsMotorola" SG_ 998 BU_NetCfg_CSWM 1;
BA_ "FlexKomComment" SG_ 998 BU_NetCfg_CSWM "Backup for network ECU config data for interior";
BA_ "GenSigSNA" SG_ 998 BU_NetCfg_DCM_DR "0h";
BA_ "GenSigSendType" SG_ 998 BU_NetCfg_DCM_DR 1;
BA_ "FlexKomSigStartValue" SG_ 998 BU_NetCfg_DCM_DR "0300000000000000h";
BA_ "FlexKomSigStartPos" SG_ 998 BU_NetCfg_DCM_DR 7;
BA_ "FlexKomSigName" SG_ 998 BU_NetCfg_DCM_DR "BU_NET_CFG_DATA_INT";
BA_ "FlexKomSigLaenge" SG_ 998 BU_NetCfg_DCM_DR 64;
BA_ "FlexKomSID" SG_ 998 BU_NetCfg_DCM_DR 871;
BA_ "FlexKomIsMotorola" SG_ 998 BU_NetCfg_DCM_DR 1;
BA_ "FlexKomComment" SG_ 998 BU_NetCfg_DCM_DR "Backup for network ECU config data for interior";
BA_ "GenSigSNA" SG_ 998 BU_NetCfg_DCM_PASS "0h";
BA_ "GenSigSendType" SG_ 998 BU_NetCfg_DCM_PASS 1;
BA_ "FlexKomSigStartValue" SG_ 998 BU_NetCfg_DCM_PASS "0300000000000000h";
BA_ "FlexKomSigStartPos" SG_ 998 BU_NetCfg_DCM_PASS 7;
BA_ "FlexKomSigName" SG_ 998 BU_NetCfg_DCM_PASS "BU_NET_CFG_DATA_INT";
BA_ "FlexKomSigLaenge" SG_ 998 BU_NetCfg_DCM_PASS 64;
BA_ "FlexKomSID" SG_ 998 BU_NetCfg_DCM_PASS 871;
BA_ "FlexKomIsMotorola" SG_ 998 BU_NetCfg_DCM_PASS 1;
BA_ "FlexKomComment" SG_ 998 BU_NetCfg_DCM_PASS "Backup for network ECU config data for interior";
BA_ "GenSigSNA" SG_ 998 BU_NetCfg_TGW "0h";
BA_ "GenSigSendType" SG_ 998 BU_NetCfg_TGW 1;
BA_ "FlexKomSigStartValue" SG_ 998 BU_NetCfg_TGW "0300000000000000h";
BA_ "FlexKomSigStartPos" SG_ 998 BU_NetCfg_TGW 7;
BA_ "FlexKomSigName" SG_ 998 BU_NetCfg_TGW "BU_NET_CFG_DATA_INT";
BA_ "FlexKomSigLaenge" SG_ 998 BU_NetCfg_TGW 64;
BA_ "FlexKomSID" SG_ 998 BU_NetCfg_TGW 871;
BA_ "FlexKomIsMotorola" SG_ 998 BU_NetCfg_TGW 1;
BA_ "FlexKomComment" SG_ 998 BU_NetCfg_TGW "Backup for network ECU config data for interior";
BA_ "GenSigSNA" SG_ 998 BU_NetCfg_ITM "0h";
BA_ "GenSigSendType" SG_ 998 BU_NetCfg_ITM 1;
BA_ "FlexKomSigStartValue" SG_ 998 BU_NetCfg_ITM "0300000000000000h";
BA_ "FlexKomSigStartPos" SG_ 998 BU_NetCfg_ITM 7;
BA_ "FlexKomSigName" SG_ 998 BU_NetCfg_ITM "BU_NET_CFG_DATA_INT";
BA_ "FlexKomSigLaenge" SG_ 998 BU_NetCfg_ITM 64;
BA_ "FlexKomSID" SG_ 998 BU_NetCfg_ITM 871;
BA_ "FlexKomIsMotorola" SG_ 998 BU_NetCfg_ITM 1;
BA_ "FlexKomComment" SG_ 998 BU_NetCfg_ITM "Backup for network ECU config data for interior";
BA_ "GenSigSNA" SG_ 998 BU_NetCfg_DVD_CDM "0h";
BA_ "GenSigSendType" SG_ 998 BU_NetCfg_DVD_CDM 1;
BA_ "FlexKomSigStartValue" SG_ 998 BU_NetCfg_DVD_CDM "0300000000000000h";
BA_ "FlexKomSigStartPos" SG_ 998 BU_NetCfg_DVD_CDM 7;
BA_ "FlexKomSigName" SG_ 998 BU_NetCfg_DVD_CDM "BU_NET_CFG_DATA_INT";
BA_ "FlexKomSigLaenge" SG_ 998 BU_NetCfg_DVD_CDM 64;
BA_ "FlexKomSID" SG_ 998 BU_NetCfg_DVD_CDM 871;
BA_ "FlexKomIsMotorola" SG_ 998 BU_NetCfg_DVD_CDM 1;
BA_ "FlexKomComment" SG_ 998 BU_NetCfg_DVD_CDM "Backup for network ECU config data for interior";
BA_ "GenSigSNA" SG_ 998 BU_NetCfg_CRSM "0h";
BA_ "GenSigSendType" SG_ 998 BU_NetCfg_CRSM 1;
BA_ "FlexKomSigStartValue" SG_ 998 BU_NetCfg_CRSM "0300000000000000h";
BA_ "FlexKomSigStartPos" SG_ 998 BU_NetCfg_CRSM 7;
BA_ "FlexKomSigName" SG_ 998 BU_NetCfg_CRSM "BU_NET_CFG_DATA_INT";
BA_ "FlexKomSigLaenge" SG_ 998 BU_NetCfg_CRSM 64;
BA_ "FlexKomSID" SG_ 998 BU_NetCfg_CRSM 871;
BA_ "FlexKomIsMotorola" SG_ 998 BU_NetCfg_CRSM 1;
BA_ "FlexKomComment" SG_ 998 BU_NetCfg_CRSM "Backup for network ECU config data for interior";
BA_ "GenSigSNA" SG_ 998 BU_NetCfg_ICS_R "0h";
BA_ "GenSigSendType" SG_ 998 BU_NetCfg_ICS_R 1;
BA_ "FlexKomSigStartValue" SG_ 998 BU_NetCfg_ICS_R "0300000000000000h";
BA_ "FlexKomSigStartPos" SG_ 998 BU_NetCfg_ICS_R 7;
BA_ "FlexKomSigName" SG_ 998 BU_NetCfg_ICS_R "BU_NET_CFG_DATA_INT";
BA_ "FlexKomSigLaenge" SG_ 998 BU_NetCfg_ICS_R 64;
BA_ "FlexKomSID" SG_ 998 BU_NetCfg_ICS_R 871;
BA_ "FlexKomIsMotorola" SG_ 998 BU_NetCfg_ICS_R 1;
BA_ "FlexKomComment" SG_ 998 BU_NetCfg_ICS_R "Backup for network ECU config data for interior";
BA_ "GenSigStartValue" SG_ 998 BU_NET_CFG_STAT_INT 3;
BA_ "GenSigSNA" SG_ 998 BU_NET_CFG_STAT_INT "3h";
BA_ "GenSigSendType" SG_ 998 BU_NET_CFG_STAT_INT 1;
BA_ "FlexKomSigStartValue" SG_ 998 BU_NET_CFG_STAT_INT "0300000000000000h";
BA_ "FlexKomSigStartPos" SG_ 998 BU_NET_CFG_STAT_INT 7;
BA_ "FlexKomSigName" SG_ 998 BU_NET_CFG_STAT_INT "BU_NET_CFG_DATA_INT";
BA_ "FlexKomSigLaenge" SG_ 998 BU_NET_CFG_STAT_INT 64;
BA_ "FlexKomSID" SG_ 998 BU_NET_CFG_STAT_INT 871;
BA_ "FlexKomIsMotorola" SG_ 998 BU_NET_CFG_STAT_INT 1;
BA_ "FlexKomComment" SG_ 998 BU_NET_CFG_STAT_INT "Backup for network ECU config data for interior";
BA_ "GenSigSNA" SG_ 998 BU_NetCfg_TGWM "0h";
BA_ "GenSigSendType" SG_ 998 BU_NetCfg_TGWM 1;
BA_ "FlexKomSigStartValue" SG_ 998 BU_NetCfg_TGWM "0300000000000000h";
BA_ "FlexKomSigStartPos" SG_ 998 BU_NetCfg_TGWM 7;
BA_ "FlexKomSigName" SG_ 998 BU_NetCfg_TGWM "BU_NET_CFG_DATA_INT";
BA_ "FlexKomSigLaenge" SG_ 998 BU_NetCfg_TGWM 64;
BA_ "FlexKomSID" SG_ 998 BU_NetCfg_TGWM 871;
BA_ "FlexKomIsMotorola" SG_ 998 BU_NetCfg_TGWM 1;
BA_ "FlexKomComment" SG_ 998 BU_NetCfg_TGWM "Backup for network ECU config data for interior";
BA_ "GenSigSNA" SG_ 999 BU_NetCfg_TIM "0h";
BA_ "GenSigSendType" SG_ 999 BU_NetCfg_TIM 1;
BA_ "FlexKomSigStartValue" SG_ 999 BU_NetCfg_TIM "0300000000000000h";
BA_ "FlexKomSigStartPos" SG_ 999 BU_NetCfg_TIM 7;
BA_ "FlexKomSigName" SG_ 999 BU_NetCfg_TIM "BU_NET_CFG_DATA_PT";
BA_ "FlexKomSigLaenge" SG_ 999 BU_NetCfg_TIM 64;
BA_ "FlexKomSID" SG_ 999 BU_NetCfg_TIM 872;
BA_ "FlexKomIsMotorola" SG_ 999 BU_NetCfg_TIM 1;
BA_ "FlexKomComment" SG_ 999 BU_NetCfg_TIM "Backup for network ECU config data for Powertrain";
BA_ "GenSigSNA" SG_ 999 BU_NetCfg_ACC "0h";
BA_ "GenSigSendType" SG_ 999 BU_NetCfg_ACC 1;
BA_ "FlexKomSigStartValue" SG_ 999 BU_NetCfg_ACC "0300000000000000h";
BA_ "FlexKomSigStartPos" SG_ 999 BU_NetCfg_ACC 7;
BA_ "FlexKomSigName" SG_ 999 BU_NetCfg_ACC "BU_NET_CFG_DATA_PT";
BA_ "FlexKomSigLaenge" SG_ 999 BU_NetCfg_ACC 64;
BA_ "FlexKomSID" SG_ 999 BU_NetCfg_ACC 872;
BA_ "FlexKomIsMotorola" SG_ 999 BU_NetCfg_ACC 1;
BA_ "FlexKomComment" SG_ 999 BU_NetCfg_ACC "Backup for network ECU config data for Powertrain";
BA_ "GenSigSNA" SG_ 999 BU_NetCfg_DTCM "0h";
BA_ "GenSigSendType" SG_ 999 BU_NetCfg_DTCM 1;
BA_ "FlexKomSigStartValue" SG_ 999 BU_NetCfg_DTCM "0300000000000000h";
BA_ "FlexKomSigStartPos" SG_ 999 BU_NetCfg_DTCM 7;
BA_ "FlexKomSigName" SG_ 999 BU_NetCfg_DTCM "BU_NET_CFG_DATA_PT";
BA_ "FlexKomSigLaenge" SG_ 999 BU_NetCfg_DTCM 64;
BA_ "FlexKomSID" SG_ 999 BU_NetCfg_DTCM 872;
BA_ "FlexKomIsMotorola" SG_ 999 BU_NetCfg_DTCM 1;
BA_ "FlexKomComment" SG_ 999 BU_NetCfg_DTCM "Backup for network ECU config data for Powertrain";
BA_ "GenSigSNA" SG_ 999 BU_NetCfg_EPB "0h";
BA_ "GenSigSendType" SG_ 999 BU_NetCfg_EPB 1;
BA_ "FlexKomSigStartValue" SG_ 999 BU_NetCfg_EPB "0300000000000000h";
BA_ "FlexKomSigStartPos" SG_ 999 BU_NetCfg_EPB 7;
BA_ "FlexKomSigName" SG_ 999 BU_NetCfg_EPB "BU_NET_CFG_DATA_PT";
BA_ "FlexKomSigLaenge" SG_ 999 BU_NetCfg_EPB 64;
BA_ "FlexKomSID" SG_ 999 BU_NetCfg_EPB 872;
BA_ "FlexKomIsMotorola" SG_ 999 BU_NetCfg_EPB 1;
BA_ "FlexKomComment" SG_ 999 BU_NetCfg_EPB "Backup for network ECU config data for Powertrain";
BA_ "GenSigSNA" SG_ 999 BU_NetCfg_ORC "0h";
BA_ "GenSigSendType" SG_ 999 BU_NetCfg_ORC 1;
BA_ "FlexKomSigStartValue" SG_ 999 BU_NetCfg_ORC "0300000000000000h";
BA_ "FlexKomSigStartPos" SG_ 999 BU_NetCfg_ORC 7;
BA_ "FlexKomSigName" SG_ 999 BU_NetCfg_ORC "BU_NET_CFG_DATA_PT";
BA_ "FlexKomSigLaenge" SG_ 999 BU_NetCfg_ORC 64;
BA_ "FlexKomSID" SG_ 999 BU_NetCfg_ORC 872;
BA_ "FlexKomIsMotorola" SG_ 999 BU_NetCfg_ORC 1;
BA_ "FlexKomComment" SG_ 999 BU_NetCfg_ORC "Backup for network ECU config data for Powertrain";
BA_ "GenSigSNA" SG_ 999 BU_NetCfg_SCCM "0h";
BA_ "GenSigSendType" SG_ 999 BU_NetCfg_SCCM 1;
BA_ "FlexKomSigStartValue" SG_ 999 BU_NetCfg_SCCM "0300000000000000h";
BA_ "FlexKomSigStartPos" SG_ 999 BU_NetCfg_SCCM 7;
BA_ "FlexKomSigName" SG_ 999 BU_NetCfg_SCCM "BU_NET_CFG_DATA_PT";
BA_ "FlexKomSigLaenge" SG_ 999 BU_NetCfg_SCCM 64;
BA_ "FlexKomSID" SG_ 999 BU_NetCfg_SCCM 872;
BA_ "FlexKomIsMotorola" SG_ 999 BU_NetCfg_SCCM 1;
BA_ "FlexKomComment" SG_ 999 BU_NetCfg_SCCM "Backup for network ECU config data for Powertrain";
BA_ "GenSigSNA" SG_ 999 BU_NetCfg_PASS_PT "0h";
BA_ "GenSigSendType" SG_ 999 BU_NetCfg_PASS_PT 1;
BA_ "FlexKomSigStartValue" SG_ 999 BU_NetCfg_PASS_PT "0300000000000000h";
BA_ "FlexKomSigStartPos" SG_ 999 BU_NetCfg_PASS_PT 7;
BA_ "FlexKomSigName" SG_ 999 BU_NetCfg_PASS_PT "BU_NET_CFG_DATA_PT";
BA_ "FlexKomSigLaenge" SG_ 999 BU_NetCfg_PASS_PT 64;
BA_ "FlexKomSID" SG_ 999 BU_NetCfg_PASS_PT 872;
BA_ "FlexKomIsMotorola" SG_ 999 BU_NetCfg_PASS_PT 1;
BA_ "FlexKomComment" SG_ 999 BU_NetCfg_PASS_PT "Backup for network ECU config data for Powertrain";
BA_ "GenSigSNA" SG_ 999 BU_NetCfg_HaLF "0h";
BA_ "GenSigSendType" SG_ 999 BU_NetCfg_HaLF 1;
BA_ "FlexKomSigStartValue" SG_ 999 BU_NetCfg_HaLF "0300000000000000h";
BA_ "FlexKomSigStartPos" SG_ 999 BU_NetCfg_HaLF 7;
BA_ "FlexKomSigName" SG_ 999 BU_NetCfg_HaLF "BU_NET_CFG_DATA_PT";
BA_ "FlexKomSigLaenge" SG_ 999 BU_NetCfg_HaLF 64;
BA_ "FlexKomSID" SG_ 999 BU_NetCfg_HaLF 872;
BA_ "FlexKomIsMotorola" SG_ 999 BU_NetCfg_HaLF 1;
BA_ "FlexKomComment" SG_ 999 BU_NetCfg_HaLF "Backup for network ECU config data for Powertrain";
BA_ "GenSigSNA" SG_ 999 BU_NetCfg_ASBS "0h";
BA_ "GenSigSendType" SG_ 999 BU_NetCfg_ASBS 1;
BA_ "FlexKomSigStartValue" SG_ 999 BU_NetCfg_ASBS "0300000000000000h";
BA_ "FlexKomSigStartPos" SG_ 999 BU_NetCfg_ASBS 7;
BA_ "FlexKomSigName" SG_ 999 BU_NetCfg_ASBS "BU_NET_CFG_DATA_PT";
BA_ "FlexKomSigLaenge" SG_ 999 BU_NetCfg_ASBS 64;
BA_ "FlexKomSID" SG_ 999 BU_NetCfg_ASBS 872;
BA_ "FlexKomIsMotorola" SG_ 999 BU_NetCfg_ASBS 1;
BA_ "FlexKomComment" SG_ 999 BU_NetCfg_ASBS "Backup for network ECU config data for Powertrain";
BA_ "GenSigSNA" SG_ 999 BU_NetCfg_ANC "0h";
BA_ "GenSigSendType" SG_ 999 BU_NetCfg_ANC 1;
BA_ "FlexKomSigStartValue" SG_ 999 BU_NetCfg_ANC "0300000000000000h";
BA_ "FlexKomSigStartPos" SG_ 999 BU_NetCfg_ANC 7;
BA_ "FlexKomSigName" SG_ 999 BU_NetCfg_ANC "BU_NET_CFG_DATA_PT";
BA_ "FlexKomSigLaenge" SG_ 999 BU_NetCfg_ANC 64;
BA_ "FlexKomSID" SG_ 999 BU_NetCfg_ANC 872;
BA_ "FlexKomIsMotorola" SG_ 999 BU_NetCfg_ANC 1;
BA_ "FlexKomComment" SG_ 999 BU_NetCfg_ANC "Backup for network ECU config data for Powertrain";
BA_ "GenSigSNA" SG_ 999 BU_NetCfg_GPF "0h";
BA_ "GenSigSendType" SG_ 999 BU_NetCfg_GPF 1;
BA_ "FlexKomSigStartValue" SG_ 999 BU_NetCfg_GPF "0300000000000000h";
BA_ "FlexKomSigStartPos" SG_ 999 BU_NetCfg_GPF 7;
BA_ "FlexKomSigName" SG_ 999 BU_NetCfg_GPF "BU_NET_CFG_DATA_PT";
BA_ "FlexKomSigLaenge" SG_ 999 BU_NetCfg_GPF 64;
BA_ "FlexKomSID" SG_ 999 BU_NetCfg_GPF 872;
BA_ "FlexKomIsMotorola" SG_ 999 BU_NetCfg_GPF 1;
BA_ "FlexKomComment" SG_ 999 BU_NetCfg_GPF "Backup for network ECU config data for Powertrain";
BA_ "GenSigSNA" SG_ 999 BU_NetCfg_BSMO "0h";
BA_ "GenSigSendType" SG_ 999 BU_NetCfg_BSMO 1;
BA_ "FlexKomSigStartValue" SG_ 999 BU_NetCfg_BSMO "0300000000000000h";
BA_ "FlexKomSigStartPos" SG_ 999 BU_NetCfg_BSMO 7;
BA_ "FlexKomSigName" SG_ 999 BU_NetCfg_BSMO "BU_NET_CFG_DATA_PT";
BA_ "FlexKomSigLaenge" SG_ 999 BU_NetCfg_BSMO 64;
BA_ "FlexKomSID" SG_ 999 BU_NetCfg_BSMO 872;
BA_ "FlexKomIsMotorola" SG_ 999 BU_NetCfg_BSMO 1;
BA_ "FlexKomComment" SG_ 999 BU_NetCfg_BSMO "Backup for network ECU config data for Powertrain";
BA_ "GenSigSNA" SG_ 999 BU_NetCfg_ESL "0h";
BA_ "GenSigSendType" SG_ 999 BU_NetCfg_ESL 1;
BA_ "FlexKomSigStartValue" SG_ 999 BU_NetCfg_ESL "0300000000000000h";
BA_ "FlexKomSigStartPos" SG_ 999 BU_NetCfg_ESL 7;
BA_ "FlexKomSigName" SG_ 999 BU_NetCfg_ESL "BU_NET_CFG_DATA_PT";
BA_ "FlexKomSigLaenge" SG_ 999 BU_NetCfg_ESL 64;
BA_ "FlexKomSID" SG_ 999 BU_NetCfg_ESL 872;
BA_ "FlexKomIsMotorola" SG_ 999 BU_NetCfg_ESL 1;
BA_ "FlexKomComment" SG_ 999 BU_NetCfg_ESL "Backup for network ECU config data for Powertrain";
BA_ "GenSigSNA" SG_ 999 BU_NetCfg_HCP "0h";
BA_ "GenSigSendType" SG_ 999 BU_NetCfg_HCP 1;
BA_ "FlexKomSigStartValue" SG_ 999 BU_NetCfg_HCP "0300000000000000h";
BA_ "FlexKomSigStartPos" SG_ 999 BU_NetCfg_HCP 7;
BA_ "FlexKomSigName" SG_ 999 BU_NetCfg_HCP "BU_NET_CFG_DATA_PT";
BA_ "FlexKomSigLaenge" SG_ 999 BU_NetCfg_HCP 64;
BA_ "FlexKomSID" SG_ 999 BU_NetCfg_HCP 872;
BA_ "FlexKomIsMotorola" SG_ 999 BU_NetCfg_HCP 1;
BA_ "FlexKomComment" SG_ 999 BU_NetCfg_HCP "Backup for network ECU config data for Powertrain";
BA_ "GenSigSNA" SG_ 999 BU_NetCfg_DPDM "0h";
BA_ "GenSigSendType" SG_ 999 BU_NetCfg_DPDM 1;
BA_ "FlexKomSigStartValue" SG_ 999 BU_NetCfg_DPDM "0300000000000000h";
BA_ "FlexKomSigStartPos" SG_ 999 BU_NetCfg_DPDM 7;
BA_ "FlexKomSigName" SG_ 999 BU_NetCfg_DPDM "BU_NET_CFG_DATA_PT";
BA_ "FlexKomSigLaenge" SG_ 999 BU_NetCfg_DPDM 64;
BA_ "FlexKomSID" SG_ 999 BU_NetCfg_DPDM 872;
BA_ "FlexKomIsMotorola" SG_ 999 BU_NetCfg_DPDM 1;
BA_ "FlexKomComment" SG_ 999 BU_NetCfg_DPDM "Backup for network ECU config data for Powertrain";
BA_ "GenSigSNA" SG_ 999 BU_NetCfg_SGW "0h";
BA_ "GenSigSendType" SG_ 999 BU_NetCfg_SGW 1;
BA_ "FlexKomSigStartValue" SG_ 999 BU_NetCfg_SGW "0300000000000000h";
BA_ "FlexKomSigStartPos" SG_ 999 BU_NetCfg_SGW 7;
BA_ "FlexKomSigName" SG_ 999 BU_NetCfg_SGW "BU_NET_CFG_DATA_PT";
BA_ "FlexKomSigLaenge" SG_ 999 BU_NetCfg_SGW 64;
BA_ "FlexKomSID" SG_ 999 BU_NetCfg_SGW 872;
BA_ "FlexKomIsMotorola" SG_ 999 BU_NetCfg_SGW 1;
BA_ "FlexKomComment" SG_ 999 BU_NetCfg_SGW "Backup for network ECU config data for Powertrain";
BA_ "GenSigSNA" SG_ 999 BU_NetCfg_AFLS "0h";
BA_ "GenSigSendType" SG_ 999 BU_NetCfg_AFLS 1;
BA_ "FlexKomSigStartValue" SG_ 999 BU_NetCfg_AFLS "0300000000000000h";
BA_ "FlexKomSigStartPos" SG_ 999 BU_NetCfg_AFLS 7;
BA_ "FlexKomSigName" SG_ 999 BU_NetCfg_AFLS "BU_NET_CFG_DATA_PT";
BA_ "FlexKomSigLaenge" SG_ 999 BU_NetCfg_AFLS 64;
BA_ "FlexKomSID" SG_ 999 BU_NetCfg_AFLS 872;
BA_ "FlexKomIsMotorola" SG_ 999 BU_NetCfg_AFLS 1;
BA_ "FlexKomComment" SG_ 999 BU_NetCfg_AFLS "Backup for network ECU config data for Powertrain";
BA_ "GenSigSNA" SG_ 999 BU_NetCfg_ITBM "0h";
BA_ "GenSigSendType" SG_ 999 BU_NetCfg_ITBM 1;
BA_ "FlexKomSigStartValue" SG_ 999 BU_NetCfg_ITBM "0300000000000000h";
BA_ "FlexKomSigStartPos" SG_ 999 BU_NetCfg_ITBM 7;
BA_ "FlexKomSigName" SG_ 999 BU_NetCfg_ITBM "BU_NET_CFG_DATA_PT";
BA_ "FlexKomSigLaenge" SG_ 999 BU_NetCfg_ITBM 64;
BA_ "FlexKomSID" SG_ 999 BU_NetCfg_ITBM 872;
BA_ "FlexKomIsMotorola" SG_ 999 BU_NetCfg_ITBM 1;
BA_ "FlexKomComment" SG_ 999 BU_NetCfg_ITBM "Backup for network ECU config data for Powertrain";
BA_ "GenSigSNA" SG_ 999 BU_NetCfg_OCM "0h";
BA_ "GenSigSendType" SG_ 999 BU_NetCfg_OCM 1;
BA_ "FlexKomSigStartValue" SG_ 999 BU_NetCfg_OCM "0300000000000000h";
BA_ "FlexKomSigStartPos" SG_ 999 BU_NetCfg_OCM 7;
BA_ "FlexKomSigName" SG_ 999 BU_NetCfg_OCM "BU_NET_CFG_DATA_PT";
BA_ "FlexKomSigLaenge" SG_ 999 BU_NetCfg_OCM 64;
BA_ "FlexKomSID" SG_ 999 BU_NetCfg_OCM 872;
BA_ "FlexKomIsMotorola" SG_ 999 BU_NetCfg_OCM 1;
BA_ "FlexKomComment" SG_ 999 BU_NetCfg_OCM "Backup for network ECU config data for Powertrain";
BA_ "GenSigSNA" SG_ 999 BU_NetCfg_ELSD "0h";
BA_ "GenSigSendType" SG_ 999 BU_NetCfg_ELSD 1;
BA_ "FlexKomSigStartValue" SG_ 999 BU_NetCfg_ELSD "0300000000000000h";
BA_ "FlexKomSigStartPos" SG_ 999 BU_NetCfg_ELSD 7;
BA_ "FlexKomSigName" SG_ 999 BU_NetCfg_ELSD "BU_NET_CFG_DATA_PT";
BA_ "FlexKomSigLaenge" SG_ 999 BU_NetCfg_ELSD 64;
BA_ "FlexKomSID" SG_ 999 BU_NetCfg_ELSD 872;
BA_ "FlexKomIsMotorola" SG_ 999 BU_NetCfg_ELSD 1;
BA_ "FlexKomComment" SG_ 999 BU_NetCfg_ELSD "Backup for network ECU config data for Powertrain";
BA_ "GenSigSNA" SG_ 999 BU_NetCfg_TCM "0h";
BA_ "GenSigSendType" SG_ 999 BU_NetCfg_TCM 1;
BA_ "FlexKomSigStartValue" SG_ 999 BU_NetCfg_TCM "0300000000000000h";
BA_ "FlexKomSigStartPos" SG_ 999 BU_NetCfg_TCM 7;
BA_ "FlexKomSigName" SG_ 999 BU_NetCfg_TCM "BU_NET_CFG_DATA_PT";
BA_ "FlexKomSigLaenge" SG_ 999 BU_NetCfg_TCM 64;
BA_ "FlexKomSID" SG_ 999 BU_NetCfg_TCM 872;
BA_ "FlexKomIsMotorola" SG_ 999 BU_NetCfg_TCM 1;
BA_ "FlexKomComment" SG_ 999 BU_NetCfg_TCM "Backup for network ECU config data for Powertrain";
BA_ "GenSigSNA" SG_ 999 BU_NetCfg_TPM "0h";
BA_ "GenSigSendType" SG_ 999 BU_NetCfg_TPM 1;
BA_ "FlexKomSigStartValue" SG_ 999 BU_NetCfg_TPM "0300000000000000h";
BA_ "FlexKomSigStartPos" SG_ 999 BU_NetCfg_TPM 7;
BA_ "FlexKomSigName" SG_ 999 BU_NetCfg_TPM "BU_NET_CFG_DATA_PT";
BA_ "FlexKomSigLaenge" SG_ 999 BU_NetCfg_TPM 64;
BA_ "FlexKomSID" SG_ 999 BU_NetCfg_TPM 872;
BA_ "FlexKomIsMotorola" SG_ 999 BU_NetCfg_TPM 1;
BA_ "FlexKomComment" SG_ 999 BU_NetCfg_TPM "Backup for network ECU config data for Powertrain";
BA_ "GenSigSNA" SG_ 999 BU_NetCfg_PTS "0h";
BA_ "GenSigSendType" SG_ 999 BU_NetCfg_PTS 1;
BA_ "FlexKomSigStartValue" SG_ 999 BU_NetCfg_PTS "0300000000000000h";
BA_ "FlexKomSigStartPos" SG_ 999 BU_NetCfg_PTS 7;
BA_ "FlexKomSigName" SG_ 999 BU_NetCfg_PTS "BU_NET_CFG_DATA_PT";
BA_ "FlexKomSigLaenge" SG_ 999 BU_NetCfg_PTS 64;
BA_ "FlexKomSID" SG_ 999 BU_NetCfg_PTS 872;
BA_ "FlexKomIsMotorola" SG_ 999 BU_NetCfg_PTS 1;
BA_ "FlexKomComment" SG_ 999 BU_NetCfg_PTS "Backup for network ECU config data for Powertrain";
BA_ "GenSigSNA" SG_ 999 BU_NetCfg_RF_HUB "0h";
BA_ "GenSigSendType" SG_ 999 BU_NetCfg_RF_HUB 1;
BA_ "FlexKomSigStartValue" SG_ 999 BU_NetCfg_RF_HUB "0300000000000000h";
BA_ "FlexKomSigStartPos" SG_ 999 BU_NetCfg_RF_HUB 7;
BA_ "FlexKomSigName" SG_ 999 BU_NetCfg_RF_HUB "BU_NET_CFG_DATA_PT";
BA_ "FlexKomSigLaenge" SG_ 999 BU_NetCfg_RF_HUB 64;
BA_ "FlexKomSID" SG_ 999 BU_NetCfg_RF_HUB 872;
BA_ "FlexKomIsMotorola" SG_ 999 BU_NetCfg_RF_HUB 1;
BA_ "FlexKomComment" SG_ 999 BU_NetCfg_RF_HUB "Backup for network ECU config data for Powertrain";
BA_ "GenSigSNA" SG_ 999 BU_NetCfg_IC "0h";
BA_ "GenSigSendType" SG_ 999 BU_NetCfg_IC 1;
BA_ "FlexKomSigStartValue" SG_ 999 BU_NetCfg_IC "0300000000000000h";
BA_ "FlexKomSigStartPos" SG_ 999 BU_NetCfg_IC 7;
BA_ "FlexKomSigName" SG_ 999 BU_NetCfg_IC "BU_NET_CFG_DATA_PT";
BA_ "FlexKomSigLaenge" SG_ 999 BU_NetCfg_IC 64;
BA_ "FlexKomSID" SG_ 999 BU_NetCfg_IC 872;
BA_ "FlexKomIsMotorola" SG_ 999 BU_NetCfg_IC 1;
BA_ "FlexKomComment" SG_ 999 BU_NetCfg_IC "Backup for network ECU config data for Powertrain";
BA_ "GenSigSNA" SG_ 999 BU_NetCfg_DASM "0h";
BA_ "GenSigSendType" SG_ 999 BU_NetCfg_DASM 1;
BA_ "FlexKomSigStartValue" SG_ 999 BU_NetCfg_DASM "0300000000000000h";
BA_ "FlexKomSigStartPos" SG_ 999 BU_NetCfg_DASM 7;
BA_ "FlexKomSigName" SG_ 999 BU_NetCfg_DASM "BU_NET_CFG_DATA_PT";
BA_ "FlexKomSigLaenge" SG_ 999 BU_NetCfg_DASM 64;
BA_ "FlexKomSID" SG_ 999 BU_NetCfg_DASM 872;
BA_ "FlexKomIsMotorola" SG_ 999 BU_NetCfg_DASM 1;
BA_ "FlexKomComment" SG_ 999 BU_NetCfg_DASM "Backup for network ECU config data for Powertrain";
BA_ "GenSigSNA" SG_ 999 BU_NetCfg_FDCM "0h";
BA_ "GenSigSendType" SG_ 999 BU_NetCfg_FDCM 1;
BA_ "FlexKomSigStartValue" SG_ 999 BU_NetCfg_FDCM "0300000000000000h";
BA_ "FlexKomSigStartPos" SG_ 999 BU_NetCfg_FDCM 7;
BA_ "FlexKomSigName" SG_ 999 BU_NetCfg_FDCM "BU_NET_CFG_DATA_PT";
BA_ "FlexKomSigLaenge" SG_ 999 BU_NetCfg_FDCM 64;
BA_ "FlexKomSID" SG_ 999 BU_NetCfg_FDCM 872;
BA_ "FlexKomIsMotorola" SG_ 999 BU_NetCfg_FDCM 1;
BA_ "FlexKomComment" SG_ 999 BU_NetCfg_FDCM "Backup for network ECU config data for Powertrain";
BA_ "GenSigSNA" SG_ 999 BU_NetCfg_EPPM "0h";
BA_ "GenSigSendType" SG_ 999 BU_NetCfg_EPPM 1;
BA_ "FlexKomSigStartValue" SG_ 999 BU_NetCfg_EPPM "0300000000000000h";
BA_ "FlexKomSigStartPos" SG_ 999 BU_NetCfg_EPPM 7;
BA_ "FlexKomSigName" SG_ 999 BU_NetCfg_EPPM "BU_NET_CFG_DATA_PT";
BA_ "FlexKomSigLaenge" SG_ 999 BU_NetCfg_EPPM 64;
BA_ "FlexKomSID" SG_ 999 BU_NetCfg_EPPM 872;
BA_ "FlexKomIsMotorola" SG_ 999 BU_NetCfg_EPPM 1;
BA_ "FlexKomComment" SG_ 999 BU_NetCfg_EPPM "Backup for network ECU config data for Powertrain";
BA_ "GenSigSNA" SG_ 999 BU_NetCfg_ECM "0h";
BA_ "GenSigSendType" SG_ 999 BU_NetCfg_ECM 1;
BA_ "FlexKomSigStartValue" SG_ 999 BU_NetCfg_ECM "0300000000000000h";
BA_ "FlexKomSigStartPos" SG_ 999 BU_NetCfg_ECM 7;
BA_ "FlexKomSigName" SG_ 999 BU_NetCfg_ECM "BU_NET_CFG_DATA_PT";
BA_ "FlexKomSigLaenge" SG_ 999 BU_NetCfg_ECM 64;
BA_ "FlexKomSID" SG_ 999 BU_NetCfg_ECM 872;
BA_ "FlexKomIsMotorola" SG_ 999 BU_NetCfg_ECM 1;
BA_ "FlexKomComment" SG_ 999 BU_NetCfg_ECM "Backup for network ECU config data for Powertrain";
BA_ "GenSigSNA" SG_ 999 BU_NetCfg_EPS "0h";
BA_ "GenSigSendType" SG_ 999 BU_NetCfg_EPS 1;
BA_ "FlexKomSigStartValue" SG_ 999 BU_NetCfg_EPS "0300000000000000h";
BA_ "FlexKomSigStartPos" SG_ 999 BU_NetCfg_EPS 7;
BA_ "FlexKomSigName" SG_ 999 BU_NetCfg_EPS "BU_NET_CFG_DATA_PT";
BA_ "FlexKomSigLaenge" SG_ 999 BU_NetCfg_EPS 64;
BA_ "FlexKomSID" SG_ 999 BU_NetCfg_EPS 872;
BA_ "FlexKomIsMotorola" SG_ 999 BU_NetCfg_EPS 1;
BA_ "FlexKomComment" SG_ 999 BU_NetCfg_EPS "Backup for network ECU config data for Powertrain";
BA_ "GenSigSNA" SG_ 999 BU_NetCfg_ESM "0h";
BA_ "GenSigSendType" SG_ 999 BU_NetCfg_ESM 1;
BA_ "FlexKomSigStartValue" SG_ 999 BU_NetCfg_ESM "0300000000000000h";
BA_ "FlexKomSigStartPos" SG_ 999 BU_NetCfg_ESM 7;
BA_ "FlexKomSigName" SG_ 999 BU_NetCfg_ESM "BU_NET_CFG_DATA_PT";
BA_ "FlexKomSigLaenge" SG_ 999 BU_NetCfg_ESM 64;
BA_ "FlexKomSID" SG_ 999 BU_NetCfg_ESM 872;
BA_ "FlexKomIsMotorola" SG_ 999 BU_NetCfg_ESM 1;
BA_ "FlexKomComment" SG_ 999 BU_NetCfg_ESM "Backup for network ECU config data for Powertrain";
BA_ "GenSigSNA" SG_ 999 BU_NetCfg_ESC "0h";
BA_ "GenSigSendType" SG_ 999 BU_NetCfg_ESC 1;
BA_ "FlexKomSigStartValue" SG_ 999 BU_NetCfg_ESC "0300000000000000h";
BA_ "FlexKomSigStartPos" SG_ 999 BU_NetCfg_ESC 7;
BA_ "FlexKomSigName" SG_ 999 BU_NetCfg_ESC "BU_NET_CFG_DATA_PT";
BA_ "FlexKomSigLaenge" SG_ 999 BU_NetCfg_ESC 64;
BA_ "FlexKomSID" SG_ 999 BU_NetCfg_ESC 872;
BA_ "FlexKomIsMotorola" SG_ 999 BU_NetCfg_ESC 1;
BA_ "FlexKomComment" SG_ 999 BU_NetCfg_ESC "Backup for network ECU config data for Powertrain";
BA_ "GenSigSNA" SG_ 999 BU_NetCfg_ADCM "0h";
BA_ "GenSigSendType" SG_ 999 BU_NetCfg_ADCM 1;
BA_ "FlexKomSigStartValue" SG_ 999 BU_NetCfg_ADCM "0300000000000000h";
BA_ "FlexKomSigStartPos" SG_ 999 BU_NetCfg_ADCM 7;
BA_ "FlexKomSigName" SG_ 999 BU_NetCfg_ADCM "BU_NET_CFG_DATA_PT";
BA_ "FlexKomSigLaenge" SG_ 999 BU_NetCfg_ADCM 64;
BA_ "FlexKomSID" SG_ 999 BU_NetCfg_ADCM 872;
BA_ "FlexKomIsMotorola" SG_ 999 BU_NetCfg_ADCM 1;
BA_ "FlexKomComment" SG_ 999 BU_NetCfg_ADCM "Backup for network ECU config data for Powertrain";
BA_ "GenSigSNA" SG_ 999 BU_NetCfg_AHLM "0h";
BA_ "GenSigSendType" SG_ 999 BU_NetCfg_AHLM 1;
BA_ "FlexKomSigStartValue" SG_ 999 BU_NetCfg_AHLM "0300000000000000h";
BA_ "FlexKomSigStartPos" SG_ 999 BU_NetCfg_AHLM 7;
BA_ "FlexKomSigName" SG_ 999 BU_NetCfg_AHLM "BU_NET_CFG_DATA_PT";
BA_ "FlexKomSigLaenge" SG_ 999 BU_NetCfg_AHLM 64;
BA_ "FlexKomSID" SG_ 999 BU_NetCfg_AHLM 872;
BA_ "FlexKomIsMotorola" SG_ 999 BU_NetCfg_AHLM 1;
BA_ "FlexKomComment" SG_ 999 BU_NetCfg_AHLM "Backup for network ECU config data for Powertrain";
BA_ "GenSigSNA" SG_ 999 BU_NetCfg_VSIM_C "0h";
BA_ "GenSigSendType" SG_ 999 BU_NetCfg_VSIM_C 1;
BA_ "FlexKomSigStartValue" SG_ 999 BU_NetCfg_VSIM_C "0300000000000000h";
BA_ "FlexKomSigStartPos" SG_ 999 BU_NetCfg_VSIM_C 7;
BA_ "FlexKomSigName" SG_ 999 BU_NetCfg_VSIM_C "BU_NET_CFG_DATA_PT";
BA_ "FlexKomSigLaenge" SG_ 999 BU_NetCfg_VSIM_C 64;
BA_ "FlexKomSID" SG_ 999 BU_NetCfg_VSIM_C 872;
BA_ "FlexKomIsMotorola" SG_ 999 BU_NetCfg_VSIM_C 1;
BA_ "FlexKomComment" SG_ 999 BU_NetCfg_VSIM_C "Backup for network ECU config data for Powertrain";
BA_ "GenSigSNA" SG_ 999 BU_NetCfg_ASCM "0h";
BA_ "GenSigSendType" SG_ 999 BU_NetCfg_ASCM 1;
BA_ "FlexKomSigStartValue" SG_ 999 BU_NetCfg_ASCM "0300000000000000h";
BA_ "FlexKomSigStartPos" SG_ 999 BU_NetCfg_ASCM 7;
BA_ "FlexKomSigName" SG_ 999 BU_NetCfg_ASCM "BU_NET_CFG_DATA_PT";
BA_ "FlexKomSigLaenge" SG_ 999 BU_NetCfg_ASCM 64;
BA_ "FlexKomSID" SG_ 999 BU_NetCfg_ASCM 872;
BA_ "FlexKomIsMotorola" SG_ 999 BU_NetCfg_ASCM 1;
BA_ "FlexKomComment" SG_ 999 BU_NetCfg_ASCM "Backup for network ECU config data for Powertrain";
BA_ "GenSigSNA" SG_ 999 BU_NetCfg_CBC_PT "0h";
BA_ "GenSigSendType" SG_ 999 BU_NetCfg_CBC_PT 1;
BA_ "FlexKomSigStartValue" SG_ 999 BU_NetCfg_CBC_PT "0300000000000000h";
BA_ "FlexKomSigStartPos" SG_ 999 BU_NetCfg_CBC_PT 7;
BA_ "FlexKomSigName" SG_ 999 BU_NetCfg_CBC_PT "BU_NET_CFG_DATA_PT";
BA_ "FlexKomSigLaenge" SG_ 999 BU_NetCfg_CBC_PT 64;
BA_ "FlexKomSID" SG_ 999 BU_NetCfg_CBC_PT 872;
BA_ "FlexKomIsMotorola" SG_ 999 BU_NetCfg_CBC_PT 1;
BA_ "FlexKomComment" SG_ 999 BU_NetCfg_CBC_PT "Backup for network ECU config data for Powertrain";
BA_ "GenSigStartValue" SG_ 999 BU_NET_CFG_STAT_PT 3;
BA_ "GenSigSNA" SG_ 999 BU_NET_CFG_STAT_PT "3h";
BA_ "GenSigSendType" SG_ 999 BU_NET_CFG_STAT_PT 1;
BA_ "FlexKomSigStartValue" SG_ 999 BU_NET_CFG_STAT_PT "0300000000000000h";
BA_ "FlexKomSigStartPos" SG_ 999 BU_NET_CFG_STAT_PT 7;
BA_ "FlexKomSigName" SG_ 999 BU_NET_CFG_STAT_PT "BU_NET_CFG_DATA_PT";
BA_ "FlexKomSigLaenge" SG_ 999 BU_NET_CFG_STAT_PT 64;
BA_ "FlexKomSID" SG_ 999 BU_NET_CFG_STAT_PT 872;
BA_ "FlexKomIsMotorola" SG_ 999 BU_NET_CFG_STAT_PT 1;
BA_ "FlexKomComment" SG_ 999 BU_NET_CFG_STAT_PT "Backup for network ECU config data for Powertrain";
BA_ "GenSigSNA" SG_ 999 BU_NetCfg_TTPM "0h";
BA_ "GenSigSendType" SG_ 999 BU_NetCfg_TTPM 1;
BA_ "FlexKomSigStartValue" SG_ 999 BU_NetCfg_TTPM "0300000000000000h";
BA_ "FlexKomSigStartPos" SG_ 999 BU_NetCfg_TTPM 7;
BA_ "FlexKomSigName" SG_ 999 BU_NetCfg_TTPM "BU_NET_CFG_DATA_PT";
BA_ "FlexKomSigLaenge" SG_ 999 BU_NetCfg_TTPM 64;
BA_ "FlexKomSID" SG_ 999 BU_NetCfg_TTPM 872;
BA_ "FlexKomIsMotorola" SG_ 999 BU_NetCfg_TTPM 1;
BA_ "FlexKomComment" SG_ 999 BU_NetCfg_TTPM "Backup for network ECU config data for Powertrain";
BA_ "GenSigSNA" SG_ 999 BU_NetCfg_EVCU2 "0h";
BA_ "GenSigSendType" SG_ 999 BU_NetCfg_EVCU2 1;
BA_ "FlexKomSigStartValue" SG_ 999 BU_NetCfg_EVCU2 "0300000000000000h";
BA_ "FlexKomSigStartPos" SG_ 999 BU_NetCfg_EVCU2 7;
BA_ "FlexKomSigName" SG_ 999 BU_NetCfg_EVCU2 "BU_NET_CFG_DATA_PT";
BA_ "FlexKomSigLaenge" SG_ 999 BU_NetCfg_EVCU2 64;
BA_ "FlexKomSID" SG_ 999 BU_NetCfg_EVCU2 872;
BA_ "FlexKomIsMotorola" SG_ 999 BU_NetCfg_EVCU2 1;
BA_ "FlexKomComment" SG_ 999 BU_NetCfg_EVCU2 "Backup for network ECU config data for Powertrain";
BA_ "GenSigTimeout_SCCM" SG_ 1000 VC_MODEL_YEAR 5250;
BA_ "GenSigTimeout_ORC" SG_ 1000 VC_MODEL_YEAR 1750;
BA_ "GenSigTimeout_IC" SG_ 1000 VC_MODEL_YEAR 5250;
BA_ "GenSigTimeout_ESM" SG_ 1000 VC_MODEL_YEAR 5250;
BA_ "GenSigTimeout_EHPS" SG_ 1000 VC_MODEL_YEAR 5250;
BA_ "GenSigTimeout_DTCM" SG_ 1000 VC_MODEL_YEAR 5250;
BA_ "GenSigStartValue" SG_ 1000 VC_MODEL_YEAR 63;
BA_ "GenSigSNA" SG_ 1000 VC_MODEL_YEAR "3Fh";
BA_ "GenSigSendType" SG_ 1000 VC_MODEL_YEAR 5;
BA_ "GenSigCycleTime" SG_ 1000 VC_MODEL_YEAR 500;
BA_ "FlexKomSigStartValue" SG_ 1000 VC_MODEL_YEAR "FFFF7FF0FF0FFF00h";
BA_ "FlexKomSigStartPos" SG_ 1000 VC_MODEL_YEAR 7;
BA_ "FlexKomSigName" SG_ 1000 VC_MODEL_YEAR "VehCfg1_Pkt";
BA_ "FlexKomSigLaenge" SG_ 1000 VC_MODEL_YEAR 64;
BA_ "FlexKomSID" SG_ 1000 VC_MODEL_YEAR 886;
BA_ "FlexKomIsMotorola" SG_ 1000 VC_MODEL_YEAR 1;
BA_ "FlexKomComment" SG_ 1000 VC_MODEL_YEAR "Vehicle Configuration 1 Packet";
BA_ "GenSigTimeout_SCCM" SG_ 1000 VC_COUNTRY 5250;
BA_ "GenSigTimeout_ORC" SG_ 1000 VC_COUNTRY 1750;
BA_ "GenSigTimeout_IC" SG_ 1000 VC_COUNTRY 5250;
BA_ "GenSigTimeout_ESM" SG_ 1000 VC_COUNTRY 5250;
BA_ "GenSigTimeout_EHPS" SG_ 1000 VC_COUNTRY 5250;
BA_ "GenSigTimeout_DTCM" SG_ 1000 VC_COUNTRY 5250;
BA_ "GenSigStartValue" SG_ 1000 VC_COUNTRY 31;
BA_ "GenSigSNA" SG_ 1000 VC_COUNTRY "1Fh";
BA_ "GenSigSendType" SG_ 1000 VC_COUNTRY 5;
BA_ "GenSigCycleTime" SG_ 1000 VC_COUNTRY 500;
BA_ "FlexKomSigStartValue" SG_ 1000 VC_COUNTRY "FFFF7FF0FF0FFF00h";
BA_ "FlexKomSigStartPos" SG_ 1000 VC_COUNTRY 7;
BA_ "FlexKomSigName" SG_ 1000 VC_COUNTRY "VehCfg1_Pkt";
BA_ "FlexKomSigLaenge" SG_ 1000 VC_COUNTRY 64;
BA_ "FlexKomSID" SG_ 1000 VC_COUNTRY 886;
BA_ "FlexKomIsMotorola" SG_ 1000 VC_COUNTRY 1;
BA_ "FlexKomComment" SG_ 1000 VC_COUNTRY "Vehicle Configuration 1 Packet";
BA_ "GenSigTimeout_ORC" SG_ 1000 VC_LHD_RHD 1750;
BA_ "GenSigTimeout_IC" SG_ 1000 VC_LHD_RHD 5250;
BA_ "GenSigTimeout_ESM" SG_ 1000 VC_LHD_RHD 5250;
BA_ "GenSigStartValue" SG_ 1000 VC_LHD_RHD 3;
BA_ "GenSigSNA" SG_ 1000 VC_LHD_RHD "3h";
BA_ "GenSigSendType" SG_ 1000 VC_LHD_RHD 5;
BA_ "GenSigCycleTime" SG_ 1000 VC_LHD_RHD 500;
BA_ "FlexKomSigStartValue" SG_ 1000 VC_LHD_RHD "FFFF7FF0FF0FFF00h";
BA_ "FlexKomSigStartPos" SG_ 1000 VC_LHD_RHD 7;
BA_ "FlexKomSigName" SG_ 1000 VC_LHD_RHD "VehCfg1_Pkt";
BA_ "FlexKomSigLaenge" SG_ 1000 VC_LHD_RHD 64;
BA_ "FlexKomSID" SG_ 1000 VC_LHD_RHD 886;
BA_ "FlexKomIsMotorola" SG_ 1000 VC_LHD_RHD 1;
BA_ "FlexKomComment" SG_ 1000 VC_LHD_RHD "Vehicle Configuration 1 Packet";
BA_ "GenSigTimeout_SCCM" SG_ 1000 VC_VehCfg1_Stat 5250;
BA_ "GenSigTimeout_ORC" SG_ 1000 VC_VehCfg1_Stat 1750;
BA_ "GenSigTimeout_OCM" SG_ 1000 VC_VehCfg1_Stat 5250;
BA_ "GenSigTimeout_IC" SG_ 1000 VC_VehCfg1_Stat 5250;
BA_ "GenSigTimeout_ESM" SG_ 1000 VC_VehCfg1_Stat 5250;
BA_ "GenSigTimeout_EHPS" SG_ 1000 VC_VehCfg1_Stat 5250;
BA_ "GenSigTimeout_DTCM" SG_ 1000 VC_VehCfg1_Stat 5250;
BA_ "GenSigTimeout_DPDM" SG_ 1000 VC_VehCfg1_Stat 5250;
BA_ "GenSigStartValue" SG_ 1000 VC_VehCfg1_Stat 3;
BA_ "GenSigSNA" SG_ 1000 VC_VehCfg1_Stat "3h";
BA_ "GenSigSendType" SG_ 1000 VC_VehCfg1_Stat 5;
BA_ "GenSigCycleTime" SG_ 1000 VC_VehCfg1_Stat 500;
BA_ "FlexKomSigStartValue" SG_ 1000 VC_VehCfg1_Stat "FFFF7FF0FF0FFF00h";
BA_ "FlexKomSigStartPos" SG_ 1000 VC_VehCfg1_Stat 7;
BA_ "FlexKomSigName" SG_ 1000 VC_VehCfg1_Stat "VehCfg1_Pkt";
BA_ "FlexKomSigLaenge" SG_ 1000 VC_VehCfg1_Stat 64;
BA_ "FlexKomSID" SG_ 1000 VC_VehCfg1_Stat 886;
BA_ "FlexKomIsMotorola" SG_ 1000 VC_VehCfg1_Stat 1;
BA_ "FlexKomComment" SG_ 1000 VC_VehCfg1_Stat "Vehicle Configuration 1 Packet";
BA_ "GenSigTimeout_IC" SG_ 1000 VC_RemStPrsnt 5250;
BA_ "GenSigSNA" SG_ 1000 VC_RemStPrsnt "0h";
BA_ "GenSigSendType" SG_ 1000 VC_RemStPrsnt 5;
BA_ "GenSigCycleTime" SG_ 1000 VC_RemStPrsnt 500;
BA_ "FlexKomSigStartValue" SG_ 1000 VC_RemStPrsnt "FFFF7FF0FF0FFF00h";
BA_ "FlexKomSigStartPos" SG_ 1000 VC_RemStPrsnt 7;
BA_ "FlexKomSigName" SG_ 1000 VC_RemStPrsnt "VehCfg1_Pkt";
BA_ "FlexKomSigLaenge" SG_ 1000 VC_RemStPrsnt 64;
BA_ "FlexKomSID" SG_ 1000 VC_RemStPrsnt 886;
BA_ "FlexKomIsMotorola" SG_ 1000 VC_RemStPrsnt 1;
BA_ "FlexKomComment" SG_ 1000 VC_RemStPrsnt "Vehicle Configuration 1 Packet";
BA_ "GenSigTimeout_IC" SG_ 1000 VC_AUTO_HB 5250;
BA_ "GenSigSNA" SG_ 1000 VC_AUTO_HB "0h";
BA_ "GenSigSendType" SG_ 1000 VC_AUTO_HB 5;
BA_ "GenSigCycleTime" SG_ 1000 VC_AUTO_HB 500;
BA_ "FlexKomSigStartValue" SG_ 1000 VC_AUTO_HB "FFFF7FF0FF0FFF00h";
BA_ "FlexKomSigStartPos" SG_ 1000 VC_AUTO_HB 7;
BA_ "FlexKomSigName" SG_ 1000 VC_AUTO_HB "VehCfg1_Pkt";
BA_ "FlexKomSigLaenge" SG_ 1000 VC_AUTO_HB 64;
BA_ "FlexKomSID" SG_ 1000 VC_AUTO_HB 886;
BA_ "FlexKomIsMotorola" SG_ 1000 VC_AUTO_HB 1;
BA_ "FlexKomComment" SG_ 1000 VC_AUTO_HB "Vehicle Configuration 1 Packet";
BA_ "GenSigTimeout_PTS" SG_ 1000 VC_PTS_DispTyp 2750;
BA_ "GenSigSNA" SG_ 1000 VC_PTS_DispTyp "7h";
BA_ "GenSigSendType" SG_ 1000 VC_PTS_DispTyp 5;
BA_ "GenSigCycleTime" SG_ 1000 VC_PTS_DispTyp 500;
BA_ "FlexKomSigStartValue" SG_ 1000 VC_PTS_DispTyp "FFFF7FF0FF0FFF00h";
BA_ "FlexKomSigStartPos" SG_ 1000 VC_PTS_DispTyp 7;
BA_ "FlexKomSigName" SG_ 1000 VC_PTS_DispTyp "VehCfg1_Pkt";
BA_ "FlexKomSigLaenge" SG_ 1000 VC_PTS_DispTyp 64;
BA_ "FlexKomSID" SG_ 1000 VC_PTS_DispTyp 886;
BA_ "FlexKomIsMotorola" SG_ 1000 VC_PTS_DispTyp 1;
BA_ "FlexKomComment" SG_ 1000 VC_PTS_DispTyp "Vehicle Configuration 1 Packet";
BA_ "GenSigSNA" SG_ 1000 VC_RVCM_Prsnt "0h";
BA_ "GenSigSendType" SG_ 1000 VC_RVCM_Prsnt 5;
BA_ "GenSigCycleTime" SG_ 1000 VC_RVCM_Prsnt 500;
BA_ "FlexKomSigStartValue" SG_ 1000 VC_RVCM_Prsnt "FFFF7FF0FF0FFF00h";
BA_ "FlexKomSigStartPos" SG_ 1000 VC_RVCM_Prsnt 7;
BA_ "FlexKomSigName" SG_ 1000 VC_RVCM_Prsnt "VehCfg1_Pkt";
BA_ "FlexKomSigLaenge" SG_ 1000 VC_RVCM_Prsnt 64;
BA_ "FlexKomSID" SG_ 1000 VC_RVCM_Prsnt 886;
BA_ "FlexKomIsMotorola" SG_ 1000 VC_RVCM_Prsnt 1;
BA_ "FlexKomComment" SG_ 1000 VC_RVCM_Prsnt "Vehicle Configuration 1 Packet";
BA_ "GenSigTimeout_SCCM" SG_ 1000 VC_VEH_LINE 5250;
BA_ "GenSigTimeout_ORC" SG_ 1000 VC_VEH_LINE 1750;
BA_ "GenSigTimeout_OCM" SG_ 1000 VC_VEH_LINE 2750;
BA_ "GenSigTimeout_IC" SG_ 1000 VC_VEH_LINE 5250;
BA_ "GenSigTimeout_ESM" SG_ 1000 VC_VEH_LINE 5250;
BA_ "GenSigTimeout_EHPS" SG_ 1000 VC_VEH_LINE 5250;
BA_ "GenSigTimeout_DTCM" SG_ 1000 VC_VEH_LINE 5250;
BA_ "GenSigTimeout_DPDM" SG_ 1000 VC_VEH_LINE 2750;
BA_ "GenSigStartValue" SG_ 1000 VC_VEH_LINE 255;
BA_ "GenSigSNA" SG_ 1000 VC_VEH_LINE "FFh";
BA_ "GenSigSendType" SG_ 1000 VC_VEH_LINE 5;
BA_ "GenSigCycleTime" SG_ 1000 VC_VEH_LINE 500;
BA_ "FlexKomSigStartValue" SG_ 1000 VC_VEH_LINE "FFFF7FF0FF0FFF00h";
BA_ "FlexKomSigStartPos" SG_ 1000 VC_VEH_LINE 7;
BA_ "FlexKomSigName" SG_ 1000 VC_VEH_LINE "VehCfg1_Pkt";
BA_ "FlexKomSigLaenge" SG_ 1000 VC_VEH_LINE 64;
BA_ "FlexKomSID" SG_ 1000 VC_VEH_LINE 886;
BA_ "FlexKomIsMotorola" SG_ 1000 VC_VEH_LINE 1;
BA_ "FlexKomComment" SG_ 1000 VC_VEH_LINE "Vehicle Configuration 1 Packet";
BA_ "GenSigSNA" SG_ 1000 VC_CHMCM_Prsnt "0h";
BA_ "GenSigSendType" SG_ 1000 VC_CHMCM_Prsnt 5;
BA_ "GenSigCycleTime" SG_ 1000 VC_CHMCM_Prsnt 500;
BA_ "FlexKomSigStartValue" SG_ 1000 VC_CHMCM_Prsnt "FFFF7FF0FF0FFF00h";
BA_ "FlexKomSigStartPos" SG_ 1000 VC_CHMCM_Prsnt 7;
BA_ "FlexKomSigName" SG_ 1000 VC_CHMCM_Prsnt "VehCfg1_Pkt";
BA_ "FlexKomSigLaenge" SG_ 1000 VC_CHMCM_Prsnt 64;
BA_ "FlexKomSID" SG_ 1000 VC_CHMCM_Prsnt 886;
BA_ "FlexKomIsMotorola" SG_ 1000 VC_CHMCM_Prsnt 1;
BA_ "FlexKomComment" SG_ 1000 VC_CHMCM_Prsnt "Vehicle Configuration 1 Packet";
BA_ "GenSigTimeout_IC" SG_ 1000 VC_HDC_Prsnt 5250;
BA_ "GenSigSNA" SG_ 1000 VC_HDC_Prsnt "0h";
BA_ "GenSigSendType" SG_ 1000 VC_HDC_Prsnt 5;
BA_ "GenSigCycleTime" SG_ 1000 VC_HDC_Prsnt 500;
BA_ "FlexKomSigStartValue" SG_ 1000 VC_HDC_Prsnt "FFFF7FF0FF0FFF00h";
BA_ "FlexKomSigStartPos" SG_ 1000 VC_HDC_Prsnt 7;
BA_ "FlexKomSigName" SG_ 1000 VC_HDC_Prsnt "VehCfg1_Pkt";
BA_ "FlexKomSigLaenge" SG_ 1000 VC_HDC_Prsnt 64;
BA_ "FlexKomSID" SG_ 1000 VC_HDC_Prsnt 886;
BA_ "FlexKomIsMotorola" SG_ 1000 VC_HDC_Prsnt 1;
BA_ "FlexKomComment" SG_ 1000 VC_HDC_Prsnt "Vehicle Configuration 1 Packet";
BA_ "GenSigTimeout_IC" SG_ 1000 VC_SSC_Prsnt 5250;
BA_ "GenSigSNA" SG_ 1000 VC_SSC_Prsnt "0h";
BA_ "GenSigSendType" SG_ 1000 VC_SSC_Prsnt 5;
BA_ "GenSigCycleTime" SG_ 1000 VC_SSC_Prsnt 500;
BA_ "FlexKomSigStartValue" SG_ 1000 VC_SSC_Prsnt "FFFF7FF0FF0FFF00h";
BA_ "FlexKomSigStartPos" SG_ 1000 VC_SSC_Prsnt 7;
BA_ "FlexKomSigName" SG_ 1000 VC_SSC_Prsnt "VehCfg1_Pkt";
BA_ "FlexKomSigLaenge" SG_ 1000 VC_SSC_Prsnt 64;
BA_ "FlexKomSID" SG_ 1000 VC_SSC_Prsnt 886;
BA_ "FlexKomIsMotorola" SG_ 1000 VC_SSC_Prsnt 1;
BA_ "FlexKomComment" SG_ 1000 VC_SSC_Prsnt "Vehicle Configuration 1 Packet";
BA_ "GenSigTimeout_IC" SG_ 1000 VC_PP_Prsnt 5250;
BA_ "GenSigSNA" SG_ 1000 VC_PP_Prsnt "0h";
BA_ "GenSigSendType" SG_ 1000 VC_PP_Prsnt 5;
BA_ "GenSigCycleTime" SG_ 1000 VC_PP_Prsnt 500;
BA_ "FlexKomSigStartValue" SG_ 1000 VC_PP_Prsnt "FFFF7FF0FF0FFF00h";
BA_ "FlexKomSigStartPos" SG_ 1000 VC_PP_Prsnt 7;
BA_ "FlexKomSigName" SG_ 1000 VC_PP_Prsnt "VehCfg1_Pkt";
BA_ "FlexKomSigLaenge" SG_ 1000 VC_PP_Prsnt 64;
BA_ "FlexKomSID" SG_ 1000 VC_PP_Prsnt 886;
BA_ "FlexKomIsMotorola" SG_ 1000 VC_PP_Prsnt 1;
BA_ "FlexKomComment" SG_ 1000 VC_PP_Prsnt "Vehicle Configuration 1 Packet";
BA_ "GenSigTimeout_ORC" SG_ 1000 VC_SpecialPKG 1750;
BA_ "GenSigTimeout_IC" SG_ 1000 VC_SpecialPKG 5250;
BA_ "GenSigStartValue" SG_ 1000 VC_SpecialPKG 255;
BA_ "GenSigSNA" SG_ 1000 VC_SpecialPKG "FFh";
BA_ "GenSigSendType" SG_ 1000 VC_SpecialPKG 5;
BA_ "GenSigCycleTime" SG_ 1000 VC_SpecialPKG 500;
BA_ "FlexKomSigStartValue" SG_ 1000 VC_SpecialPKG "FFFF7FF0FF0FFF00h";
BA_ "FlexKomSigStartPos" SG_ 1000 VC_SpecialPKG 7;
BA_ "FlexKomSigName" SG_ 1000 VC_SpecialPKG "VehCfg1_Pkt";
BA_ "FlexKomSigLaenge" SG_ 1000 VC_SpecialPKG 64;
BA_ "FlexKomSID" SG_ 1000 VC_SpecialPKG 886;
BA_ "FlexKomIsMotorola" SG_ 1000 VC_SpecialPKG 1;
BA_ "FlexKomComment" SG_ 1000 VC_SpecialPKG "Vehicle Configuration 1 Packet";
BA_ "GenSigSNA" SG_ 1000 VC_HdRstPrsnt "0h";
BA_ "GenSigSendType" SG_ 1000 VC_HdRstPrsnt 5;
BA_ "GenSigCycleTime" SG_ 1000 VC_HdRstPrsnt 500;
BA_ "FlexKomSigStartValue" SG_ 1000 VC_HdRstPrsnt "FFFF7FF0FF0FFF00h";
BA_ "FlexKomSigStartPos" SG_ 1000 VC_HdRstPrsnt 7;
BA_ "FlexKomSigName" SG_ 1000 VC_HdRstPrsnt "VehCfg1_Pkt";
BA_ "FlexKomSigLaenge" SG_ 1000 VC_HdRstPrsnt 64;
BA_ "FlexKomSID" SG_ 1000 VC_HdRstPrsnt 886;
BA_ "FlexKomIsMotorola" SG_ 1000 VC_HdRstPrsnt 1;
BA_ "FlexKomComment" SG_ 1000 VC_HdRstPrsnt "Vehicle Configuration 1 Packet";
BA_ "GenSigTimeout_IC" SG_ 1000 VC_SCR_Prsnt 5250;
BA_ "GenSigSNA" SG_ 1000 VC_SCR_Prsnt "0h";
BA_ "GenSigSendType" SG_ 1000 VC_SCR_Prsnt 5;
BA_ "GenSigCycleTime" SG_ 1000 VC_SCR_Prsnt 500;
BA_ "FlexKomSigStartValue" SG_ 1000 VC_SCR_Prsnt "FFFF7FF0FF0FFF00h";
BA_ "FlexKomSigStartPos" SG_ 1000 VC_SCR_Prsnt 7;
BA_ "FlexKomSigName" SG_ 1000 VC_SCR_Prsnt "VehCfg1_Pkt";
BA_ "FlexKomSigLaenge" SG_ 1000 VC_SCR_Prsnt 64;
BA_ "FlexKomSID" SG_ 1000 VC_SCR_Prsnt 886;
BA_ "FlexKomIsMotorola" SG_ 1000 VC_SCR_Prsnt 1;
BA_ "FlexKomComment" SG_ 1000 VC_SCR_Prsnt "Vehicle Configuration 1 Packet";
BA_ "GenSigTimeout_PTS" SG_ 1000 VC_PTS_Config 2750;
BA_ "GenSigTimeout_IC" SG_ 1000 VC_PTS_Config 5250;
BA_ "GenSigSNA" SG_ 1000 VC_PTS_Config "0h";
BA_ "GenSigSendType" SG_ 1000 VC_PTS_Config 5;
BA_ "GenSigCycleTime" SG_ 1000 VC_PTS_Config 500;
BA_ "FlexKomSigStartValue" SG_ 1000 VC_PTS_Config "FFFF7FF0FF0FFF00h";
BA_ "FlexKomSigStartPos" SG_ 1000 VC_PTS_Config 7;
BA_ "FlexKomSigName" SG_ 1000 VC_PTS_Config "VehCfg1_Pkt";
BA_ "FlexKomSigLaenge" SG_ 1000 VC_PTS_Config 64;
BA_ "FlexKomSID" SG_ 1000 VC_PTS_Config 886;
BA_ "FlexKomIsMotorola" SG_ 1000 VC_PTS_Config 1;
BA_ "FlexKomComment" SG_ 1000 VC_PTS_Config "Vehicle Configuration 1 Packet";
BA_ "GenSigTimeout_SCCM" SG_ 1000 VC_BODY_STYLE 5250;
BA_ "GenSigTimeout_ORC" SG_ 1000 VC_BODY_STYLE 1750;
BA_ "GenSigTimeout_IC" SG_ 1000 VC_BODY_STYLE 5250;
BA_ "GenSigTimeout_ESM" SG_ 1000 VC_BODY_STYLE 5250;
BA_ "GenSigTimeout_EHPS" SG_ 1000 VC_BODY_STYLE 5250;
BA_ "GenSigTimeout_DTCM" SG_ 1000 VC_BODY_STYLE 5250;
BA_ "GenSigStartValue" SG_ 1000 VC_BODY_STYLE 15;
BA_ "GenSigSNA" SG_ 1000 VC_BODY_STYLE "Fh";
BA_ "GenSigSendType" SG_ 1000 VC_BODY_STYLE 5;
BA_ "GenSigCycleTime" SG_ 1000 VC_BODY_STYLE 500;
BA_ "FlexKomSigStartValue" SG_ 1000 VC_BODY_STYLE "FFFF7FF0FF0FFF00h";
BA_ "FlexKomSigStartPos" SG_ 1000 VC_BODY_STYLE 7;
BA_ "FlexKomSigName" SG_ 1000 VC_BODY_STYLE "VehCfg1_Pkt";
BA_ "FlexKomSigLaenge" SG_ 1000 VC_BODY_STYLE 64;
BA_ "FlexKomSID" SG_ 1000 VC_BODY_STYLE 886;
BA_ "FlexKomIsMotorola" SG_ 1000 VC_BODY_STYLE 1;
BA_ "FlexKomComment" SG_ 1000 VC_BODY_STYLE "Vehicle Configuration 1 Packet";
BA_ "GenSigStartValue" SG_ 1000 VC_MAX_VEH_SPD 255;
BA_ "GenSigSNA" SG_ 1000 VC_MAX_VEH_SPD "FFh";
BA_ "GenSigSendType" SG_ 1000 VC_MAX_VEH_SPD 5;
BA_ "GenSigCycleTime" SG_ 1000 VC_MAX_VEH_SPD 500;
BA_ "FlexKomSigStartValue" SG_ 1000 VC_MAX_VEH_SPD "FFFF7FF0FF0FFF00h";
BA_ "FlexKomSigStartPos" SG_ 1000 VC_MAX_VEH_SPD 7;
BA_ "FlexKomSigName" SG_ 1000 VC_MAX_VEH_SPD "VehCfg1_Pkt";
BA_ "FlexKomSigLaenge" SG_ 1000 VC_MAX_VEH_SPD 64;
BA_ "FlexKomSID" SG_ 1000 VC_MAX_VEH_SPD 886;
BA_ "FlexKomIsMotorola" SG_ 1000 VC_MAX_VEH_SPD 1;
BA_ "FlexKomComment" SG_ 1000 VC_MAX_VEH_SPD "Vehicle Configuration 1 Packet";
BA_ "GenSigTimeout_IC" SG_ 1000 VC_ShftrTyp 5250;
BA_ "GenSigTimeout_ESM" SG_ 1000 VC_ShftrTyp 5250;
BA_ "GenSigStartValue" SG_ 1000 VC_ShftrTyp 15;
BA_ "GenSigSNA" SG_ 1000 VC_ShftrTyp "Fh";
BA_ "GenSigSendType" SG_ 1000 VC_ShftrTyp 5;
BA_ "GenSigCycleTime" SG_ 1000 VC_ShftrTyp 500;
BA_ "FlexKomSigStartValue" SG_ 1000 VC_ShftrTyp "FFFF7FF0FF0FFF00h";
BA_ "FlexKomSigStartPos" SG_ 1000 VC_ShftrTyp 7;
BA_ "FlexKomSigName" SG_ 1000 VC_ShftrTyp "VehCfg1_Pkt";
BA_ "FlexKomSigLaenge" SG_ 1000 VC_ShftrTyp 64;
BA_ "FlexKomSID" SG_ 1000 VC_ShftrTyp 886;
BA_ "FlexKomIsMotorola" SG_ 1000 VC_ShftrTyp 1;
BA_ "FlexKomComment" SG_ 1000 VC_ShftrTyp "Vehicle Configuration 1 Packet";
BA_ "GenSigTimeout_ORC" SG_ 1000 VC_XWD 1750;
BA_ "GenSigTimeout_IC" SG_ 1000 VC_XWD 5250;
BA_ "GenSigTimeout_ESM" SG_ 1000 VC_XWD 5250;
BA_ "GenSigSNA" SG_ 1000 VC_XWD "0h";
BA_ "GenSigSendType" SG_ 1000 VC_XWD 5;
BA_ "GenSigCycleTime" SG_ 1000 VC_XWD 500;
BA_ "FlexKomSigStartValue" SG_ 1000 VC_XWD "FFFF7FF0FF0FFF00h";
BA_ "FlexKomSigStartPos" SG_ 1000 VC_XWD 7;
BA_ "FlexKomSigName" SG_ 1000 VC_XWD "VehCfg1_Pkt";
BA_ "FlexKomSigLaenge" SG_ 1000 VC_XWD 64;
BA_ "FlexKomSID" SG_ 1000 VC_XWD 886;
BA_ "FlexKomIsMotorola" SG_ 1000 VC_XWD 1;
BA_ "FlexKomComment" SG_ 1000 VC_XWD "Vehicle Configuration 1 Packet";
BA_ "GenSigSNA" SG_ 1000 VC_EmodePrsnt "0h";
BA_ "GenSigSendType" SG_ 1000 VC_EmodePrsnt 5;
BA_ "GenSigCycleTime" SG_ 1000 VC_EmodePrsnt 500;
BA_ "FlexKomSigStartValue" SG_ 1000 VC_EmodePrsnt "FFFF7FF0FF0FFF00h";
BA_ "FlexKomSigStartPos" SG_ 1000 VC_EmodePrsnt 7;
BA_ "FlexKomSigName" SG_ 1000 VC_EmodePrsnt "VehCfg1_Pkt";
BA_ "FlexKomSigLaenge" SG_ 1000 VC_EmodePrsnt 64;
BA_ "FlexKomSID" SG_ 1000 VC_EmodePrsnt 886;
BA_ "FlexKomIsMotorola" SG_ 1000 VC_EmodePrsnt 1;
BA_ "FlexKomComment" SG_ 1000 VC_EmodePrsnt "Vehicle Configuration 1 Packet";
BA_ "GenSigTimeout_IC" SG_ 1001 VC_ThatchamPrsnt 21000;
BA_ "GenSigSNA" SG_ 1001 VC_ThatchamPrsnt "0h";
BA_ "GenSigSendType" SG_ 1001 VC_ThatchamPrsnt 5;
BA_ "GenSigCycleTime" SG_ 1001 VC_ThatchamPrsnt 2000;
BA_ "FlexKomSigStartValue" SG_ 1001 VC_ThatchamPrsnt "0300FF00FFFFFFFFh";
BA_ "FlexKomSigStartPos" SG_ 1001 VC_ThatchamPrsnt 7;
BA_ "FlexKomSigName" SG_ 1001 VC_ThatchamPrsnt "VehCfg2_Pkt";
BA_ "FlexKomSigLaenge" SG_ 1001 VC_ThatchamPrsnt 64;
BA_ "FlexKomSID" SG_ 1001 VC_ThatchamPrsnt 887;
BA_ "FlexKomIsMotorola" SG_ 1001 VC_ThatchamPrsnt 1;
BA_ "FlexKomComment" SG_ 1001 VC_ThatchamPrsnt "Vehicle Configuration 2 Packet";
BA_ "GenSigTimeout_IC" SG_ 1001 VC_MaseratiMd 21000;
BA_ "GenSigSNA" SG_ 1001 VC_MaseratiMd "3h";
BA_ "GenSigSendType" SG_ 1001 VC_MaseratiMd 5;
BA_ "GenSigCycleTime" SG_ 1001 VC_MaseratiMd 2000;
BA_ "FlexKomSigStartValue" SG_ 1001 VC_MaseratiMd "0300FF00FFFFFFFFh";
BA_ "FlexKomSigStartPos" SG_ 1001 VC_MaseratiMd 7;
BA_ "FlexKomSigName" SG_ 1001 VC_MaseratiMd "VehCfg2_Pkt";
BA_ "FlexKomSigLaenge" SG_ 1001 VC_MaseratiMd 64;
BA_ "FlexKomSID" SG_ 1001 VC_MaseratiMd 887;
BA_ "FlexKomIsMotorola" SG_ 1001 VC_MaseratiMd 1;
BA_ "FlexKomComment" SG_ 1001 VC_MaseratiMd "Vehicle Configuration 2 Packet";
BA_ "GenSigTimeout_IC" SG_ 1001 VC_RainSnsPrsnt 21000;
BA_ "GenSigSNA" SG_ 1001 VC_RainSnsPrsnt "0h";
BA_ "GenSigSendType" SG_ 1001 VC_RainSnsPrsnt 5;
BA_ "GenSigCycleTime" SG_ 1001 VC_RainSnsPrsnt 2000;
BA_ "FlexKomSigStartValue" SG_ 1001 VC_RainSnsPrsnt "0300FF00FFFFFFFFh";
BA_ "FlexKomSigStartPos" SG_ 1001 VC_RainSnsPrsnt 7;
BA_ "FlexKomSigName" SG_ 1001 VC_RainSnsPrsnt "VehCfg2_Pkt";
BA_ "FlexKomSigLaenge" SG_ 1001 VC_RainSnsPrsnt 64;
BA_ "FlexKomSID" SG_ 1001 VC_RainSnsPrsnt 887;
BA_ "FlexKomIsMotorola" SG_ 1001 VC_RainSnsPrsnt 1;
BA_ "FlexKomComment" SG_ 1001 VC_RainSnsPrsnt "Vehicle Configuration 2 Packet";
BA_ "GenSigTimeout_ORC" SG_ 1001 VC_CRUISE_PRSNT 7000;
BA_ "GenSigTimeout_IC" SG_ 1001 VC_CRUISE_PRSNT 21000;
BA_ "GenSigSNA" SG_ 1001 VC_CRUISE_PRSNT "0h";
BA_ "GenSigSendType" SG_ 1001 VC_CRUISE_PRSNT 5;
BA_ "GenSigCycleTime" SG_ 1001 VC_CRUISE_PRSNT 2000;
BA_ "FlexKomSigStartValue" SG_ 1001 VC_CRUISE_PRSNT "0300FF00FFFFFFFFh";
BA_ "FlexKomSigStartPos" SG_ 1001 VC_CRUISE_PRSNT 7;
BA_ "FlexKomSigName" SG_ 1001 VC_CRUISE_PRSNT "VehCfg2_Pkt";
BA_ "FlexKomSigLaenge" SG_ 1001 VC_CRUISE_PRSNT 64;
BA_ "FlexKomSID" SG_ 1001 VC_CRUISE_PRSNT 887;
BA_ "FlexKomIsMotorola" SG_ 1001 VC_CRUISE_PRSNT 1;
BA_ "FlexKomComment" SG_ 1001 VC_CRUISE_PRSNT "Vehicle Configuration 2 Packet";
BA_ "GenSigSNA" SG_ 1001 VC_DRVMD_Prsnt "0h";
BA_ "GenSigSendType" SG_ 1001 VC_DRVMD_Prsnt 5;
BA_ "GenSigCycleTime" SG_ 1001 VC_DRVMD_Prsnt 2000;
BA_ "FlexKomSigStartValue" SG_ 1001 VC_DRVMD_Prsnt "0300FF00FFFFFFFFh";
BA_ "FlexKomSigStartPos" SG_ 1001 VC_DRVMD_Prsnt 7;
BA_ "FlexKomSigName" SG_ 1001 VC_DRVMD_Prsnt "VehCfg2_Pkt";
BA_ "FlexKomSigLaenge" SG_ 1001 VC_DRVMD_Prsnt 64;
BA_ "FlexKomSID" SG_ 1001 VC_DRVMD_Prsnt 887;
BA_ "FlexKomIsMotorola" SG_ 1001 VC_DRVMD_Prsnt 1;
BA_ "FlexKomComment" SG_ 1001 VC_DRVMD_Prsnt "Vehicle Configuration 2 Packet";
BA_ "GenSigTimeout_IC" SG_ 1001 VC_ShftInd_Prsnt 21000;
BA_ "GenSigSNA" SG_ 1001 VC_ShftInd_Prsnt "0h";
BA_ "GenSigSendType" SG_ 1001 VC_ShftInd_Prsnt 5;
BA_ "GenSigCycleTime" SG_ 1001 VC_ShftInd_Prsnt 2000;
BA_ "FlexKomSigStartValue" SG_ 1001 VC_ShftInd_Prsnt "0300FF00FFFFFFFFh";
BA_ "FlexKomSigStartPos" SG_ 1001 VC_ShftInd_Prsnt 7;
BA_ "FlexKomSigName" SG_ 1001 VC_ShftInd_Prsnt "VehCfg2_Pkt";
BA_ "FlexKomSigLaenge" SG_ 1001 VC_ShftInd_Prsnt 64;
BA_ "FlexKomSID" SG_ 1001 VC_ShftInd_Prsnt 887;
BA_ "FlexKomIsMotorola" SG_ 1001 VC_ShftInd_Prsnt 1;
BA_ "FlexKomComment" SG_ 1001 VC_ShftInd_Prsnt "Vehicle Configuration 2 Packet";
BA_ "GenSigTimeout_IC" SG_ 1001 VC_LgtLdPressFtTr 21000;
BA_ "GenSigStartValue" SG_ 1001 VC_LgtLdPressFtTr 255;
BA_ "GenSigSNA" SG_ 1001 VC_LgtLdPressFtTr "FFh";
BA_ "GenSigSendType" SG_ 1001 VC_LgtLdPressFtTr 5;
BA_ "GenSigCycleTime" SG_ 1001 VC_LgtLdPressFtTr 2000;
BA_ "FlexKomSigStartValue" SG_ 1001 VC_LgtLdPressFtTr "0300FF00FFFFFFFFh";
BA_ "FlexKomSigStartPos" SG_ 1001 VC_LgtLdPressFtTr 7;
BA_ "FlexKomSigName" SG_ 1001 VC_LgtLdPressFtTr "VehCfg2_Pkt";
BA_ "FlexKomSigLaenge" SG_ 1001 VC_LgtLdPressFtTr 64;
BA_ "FlexKomSID" SG_ 1001 VC_LgtLdPressFtTr 887;
BA_ "FlexKomIsMotorola" SG_ 1001 VC_LgtLdPressFtTr 1;
BA_ "FlexKomComment" SG_ 1001 VC_LgtLdPressFtTr "Vehicle Configuration 2 Packet";
BA_ "GenSigTimeout_IC" SG_ 1001 VC_MaxLdPressRrTr 21000;
BA_ "GenSigStartValue" SG_ 1001 VC_MaxLdPressRrTr 255;
BA_ "GenSigSNA" SG_ 1001 VC_MaxLdPressRrTr "FFh";
BA_ "GenSigSendType" SG_ 1001 VC_MaxLdPressRrTr 5;
BA_ "GenSigCycleTime" SG_ 1001 VC_MaxLdPressRrTr 2000;
BA_ "FlexKomSigStartValue" SG_ 1001 VC_MaxLdPressRrTr "0300FF00FFFFFFFFh";
BA_ "FlexKomSigStartPos" SG_ 1001 VC_MaxLdPressRrTr 7;
BA_ "FlexKomSigName" SG_ 1001 VC_MaxLdPressRrTr "VehCfg2_Pkt";
BA_ "FlexKomSigLaenge" SG_ 1001 VC_MaxLdPressRrTr 64;
BA_ "FlexKomSID" SG_ 1001 VC_MaxLdPressRrTr 887;
BA_ "FlexKomIsMotorola" SG_ 1001 VC_MaxLdPressRrTr 1;
BA_ "FlexKomComment" SG_ 1001 VC_MaxLdPressRrTr "Vehicle Configuration 2 Packet";
BA_ "GenSigTimeout_IC" SG_ 1001 VC_MaxLdPressFtTr 21000;
BA_ "GenSigStartValue" SG_ 1001 VC_MaxLdPressFtTr 255;
BA_ "GenSigSNA" SG_ 1001 VC_MaxLdPressFtTr "FFh";
BA_ "GenSigSendType" SG_ 1001 VC_MaxLdPressFtTr 5;
BA_ "GenSigCycleTime" SG_ 1001 VC_MaxLdPressFtTr 2000;
BA_ "FlexKomSigStartValue" SG_ 1001 VC_MaxLdPressFtTr "0300FF00FFFFFFFFh";
BA_ "FlexKomSigStartPos" SG_ 1001 VC_MaxLdPressFtTr 7;
BA_ "FlexKomSigName" SG_ 1001 VC_MaxLdPressFtTr "VehCfg2_Pkt";
BA_ "FlexKomSigLaenge" SG_ 1001 VC_MaxLdPressFtTr 64;
BA_ "FlexKomSID" SG_ 1001 VC_MaxLdPressFtTr 887;
BA_ "FlexKomIsMotorola" SG_ 1001 VC_MaxLdPressFtTr 1;
BA_ "FlexKomComment" SG_ 1001 VC_MaxLdPressFtTr "Vehicle Configuration 2 Packet";
BA_ "GenSigTimeout_IC" SG_ 1001 VC_LgtLdPressRrTr 21000;
BA_ "GenSigStartValue" SG_ 1001 VC_LgtLdPressRrTr 255;
BA_ "GenSigSNA" SG_ 1001 VC_LgtLdPressRrTr "FFh";
BA_ "GenSigSendType" SG_ 1001 VC_LgtLdPressRrTr 5;
BA_ "GenSigCycleTime" SG_ 1001 VC_LgtLdPressRrTr 2000;
BA_ "FlexKomSigStartValue" SG_ 1001 VC_LgtLdPressRrTr "0300FF00FFFFFFFFh";
BA_ "FlexKomSigStartPos" SG_ 1001 VC_LgtLdPressRrTr 7;
BA_ "FlexKomSigName" SG_ 1001 VC_LgtLdPressRrTr "VehCfg2_Pkt";
BA_ "FlexKomSigLaenge" SG_ 1001 VC_LgtLdPressRrTr 64;
BA_ "FlexKomSID" SG_ 1001 VC_LgtLdPressRrTr 887;
BA_ "FlexKomIsMotorola" SG_ 1001 VC_LgtLdPressRrTr 1;
BA_ "FlexKomComment" SG_ 1001 VC_LgtLdPressRrTr "Vehicle Configuration 2 Packet";
BA_ "GenSigSNA" SG_ 1001 VC_MemoryDRVMD_Prsnt "0h";
BA_ "GenSigSendType" SG_ 1001 VC_MemoryDRVMD_Prsnt 5;
BA_ "GenSigCycleTime" SG_ 1001 VC_MemoryDRVMD_Prsnt 2000;
BA_ "FlexKomSigStartValue" SG_ 1001 VC_MemoryDRVMD_Prsnt "0300FF00FFFFFFFFh";
BA_ "FlexKomSigStartPos" SG_ 1001 VC_MemoryDRVMD_Prsnt 7;
BA_ "FlexKomSigName" SG_ 1001 VC_MemoryDRVMD_Prsnt "VehCfg2_Pkt";
BA_ "FlexKomSigLaenge" SG_ 1001 VC_MemoryDRVMD_Prsnt 64;
BA_ "FlexKomSID" SG_ 1001 VC_MemoryDRVMD_Prsnt 887;
BA_ "FlexKomIsMotorola" SG_ 1001 VC_MemoryDRVMD_Prsnt 1;
BA_ "FlexKomComment" SG_ 1001 VC_MemoryDRVMD_Prsnt "Vehicle Configuration 2 Packet";
BA_ "GenSigTimeout_IC" SG_ 1001 VC_ESCDrvMd_Prsnt 21000;
BA_ "GenSigSNA" SG_ 1001 VC_ESCDrvMd_Prsnt "0h";
BA_ "GenSigSendType" SG_ 1001 VC_ESCDrvMd_Prsnt 5;
BA_ "GenSigCycleTime" SG_ 1001 VC_ESCDrvMd_Prsnt 2000;
BA_ "FlexKomSigStartValue" SG_ 1001 VC_ESCDrvMd_Prsnt "0300FF00FFFFFFFFh";
BA_ "FlexKomSigStartPos" SG_ 1001 VC_ESCDrvMd_Prsnt 7;
BA_ "FlexKomSigName" SG_ 1001 VC_ESCDrvMd_Prsnt "VehCfg2_Pkt";
BA_ "FlexKomSigLaenge" SG_ 1001 VC_ESCDrvMd_Prsnt 64;
BA_ "FlexKomSID" SG_ 1001 VC_ESCDrvMd_Prsnt 887;
BA_ "FlexKomIsMotorola" SG_ 1001 VC_ESCDrvMd_Prsnt 1;
BA_ "FlexKomComment" SG_ 1001 VC_ESCDrvMd_Prsnt "Vehicle Configuration 2 Packet";
BA_ "GenSigTimeout_IC" SG_ 1001 VC_EngPowerDrvMd_Prsnt 21000;
BA_ "GenSigSNA" SG_ 1001 VC_EngPowerDrvMd_Prsnt "0h";
BA_ "GenSigSendType" SG_ 1001 VC_EngPowerDrvMd_Prsnt 5;
BA_ "GenSigCycleTime" SG_ 1001 VC_EngPowerDrvMd_Prsnt 2000;
BA_ "FlexKomSigStartValue" SG_ 1001 VC_EngPowerDrvMd_Prsnt "0300FF00FFFFFFFFh";
BA_ "FlexKomSigStartPos" SG_ 1001 VC_EngPowerDrvMd_Prsnt 7;
BA_ "FlexKomSigName" SG_ 1001 VC_EngPowerDrvMd_Prsnt "VehCfg2_Pkt";
BA_ "FlexKomSigLaenge" SG_ 1001 VC_EngPowerDrvMd_Prsnt 64;
BA_ "FlexKomSID" SG_ 1001 VC_EngPowerDrvMd_Prsnt 887;
BA_ "FlexKomIsMotorola" SG_ 1001 VC_EngPowerDrvMd_Prsnt 1;
BA_ "FlexKomComment" SG_ 1001 VC_EngPowerDrvMd_Prsnt "Vehicle Configuration 2 Packet";
BA_ "GenSigTimeout_IC" SG_ 1001 VC_SecPrkPrsnt 21000;
BA_ "GenSigSNA" SG_ 1001 VC_SecPrkPrsnt "0h";
BA_ "GenSigSendType" SG_ 1001 VC_SecPrkPrsnt 5;
BA_ "GenSigCycleTime" SG_ 1001 VC_SecPrkPrsnt 2000;
BA_ "FlexKomSigStartValue" SG_ 1001 VC_SecPrkPrsnt "0300FF00FFFFFFFFh";
BA_ "FlexKomSigStartPos" SG_ 1001 VC_SecPrkPrsnt 7;
BA_ "FlexKomSigName" SG_ 1001 VC_SecPrkPrsnt "VehCfg2_Pkt";
BA_ "FlexKomSigLaenge" SG_ 1001 VC_SecPrkPrsnt 64;
BA_ "FlexKomSID" SG_ 1001 VC_SecPrkPrsnt 887;
BA_ "FlexKomIsMotorola" SG_ 1001 VC_SecPrkPrsnt 1;
BA_ "FlexKomComment" SG_ 1001 VC_SecPrkPrsnt "Vehicle Configuration 2 Packet";
BA_ "GenSigTimeout_IC" SG_ 1001 VC_FG_PRSNT 21000;
BA_ "GenSigSNA" SG_ 1001 VC_FG_PRSNT "0h";
BA_ "GenSigSendType" SG_ 1001 VC_FG_PRSNT 5;
BA_ "GenSigCycleTime" SG_ 1001 VC_FG_PRSNT 2000;
BA_ "FlexKomSigStartValue" SG_ 1001 VC_FG_PRSNT "0300FF00FFFFFFFFh";
BA_ "FlexKomSigStartPos" SG_ 1001 VC_FG_PRSNT 7;
BA_ "FlexKomSigName" SG_ 1001 VC_FG_PRSNT "VehCfg2_Pkt";
BA_ "FlexKomSigLaenge" SG_ 1001 VC_FG_PRSNT 64;
BA_ "FlexKomSID" SG_ 1001 VC_FG_PRSNT 887;
BA_ "FlexKomIsMotorola" SG_ 1001 VC_FG_PRSNT 1;
BA_ "FlexKomComment" SG_ 1001 VC_FG_PRSNT "Vehicle Configuration 2 Packet";
BA_ "GenSigSNA" SG_ 1001 VC_FULL_SPARE "0h";
BA_ "GenSigSendType" SG_ 1001 VC_FULL_SPARE 5;
BA_ "GenSigCycleTime" SG_ 1001 VC_FULL_SPARE 2000;
BA_ "FlexKomSigStartValue" SG_ 1001 VC_FULL_SPARE "0300FF00FFFFFFFFh";
BA_ "FlexKomSigStartPos" SG_ 1001 VC_FULL_SPARE 7;
BA_ "FlexKomSigName" SG_ 1001 VC_FULL_SPARE "VehCfg2_Pkt";
BA_ "FlexKomSigLaenge" SG_ 1001 VC_FULL_SPARE 64;
BA_ "FlexKomSID" SG_ 1001 VC_FULL_SPARE 887;
BA_ "FlexKomIsMotorola" SG_ 1001 VC_FULL_SPARE 1;
BA_ "FlexKomComment" SG_ 1001 VC_FULL_SPARE "Vehicle Configuration 2 Packet";
BA_ "GenSigTimeout_ORC" SG_ 1001 VC_OffRoad 7000;
BA_ "GenSigTimeout_IC" SG_ 1001 VC_OffRoad 21000;
BA_ "GenSigSNA" SG_ 1001 VC_OffRoad "0h";
BA_ "GenSigSendType" SG_ 1001 VC_OffRoad 5;
BA_ "GenSigCycleTime" SG_ 1001 VC_OffRoad 2000;
BA_ "FlexKomSigStartValue" SG_ 1001 VC_OffRoad "0300FF00FFFFFFFFh";
BA_ "FlexKomSigStartPos" SG_ 1001 VC_OffRoad 7;
BA_ "FlexKomSigName" SG_ 1001 VC_OffRoad "VehCfg2_Pkt";
BA_ "FlexKomSigLaenge" SG_ 1001 VC_OffRoad 64;
BA_ "FlexKomSID" SG_ 1001 VC_OffRoad 887;
BA_ "FlexKomIsMotorola" SG_ 1001 VC_OffRoad 1;
BA_ "FlexKomComment" SG_ 1001 VC_OffRoad "Vehicle Configuration 2 Packet";
BA_ "GenSigTimeout_IC" SG_ 1001 VC_ECO_Indicator 21000;
BA_ "GenSigSNA" SG_ 1001 VC_ECO_Indicator "0h";
BA_ "GenSigSendType" SG_ 1001 VC_ECO_Indicator 5;
BA_ "GenSigCycleTime" SG_ 1001 VC_ECO_Indicator 2000;
BA_ "FlexKomSigStartValue" SG_ 1001 VC_ECO_Indicator "0300FF00FFFFFFFFh";
BA_ "FlexKomSigStartPos" SG_ 1001 VC_ECO_Indicator 7;
BA_ "FlexKomSigName" SG_ 1001 VC_ECO_Indicator "VehCfg2_Pkt";
BA_ "FlexKomSigLaenge" SG_ 1001 VC_ECO_Indicator 64;
BA_ "FlexKomSID" SG_ 1001 VC_ECO_Indicator 887;
BA_ "FlexKomIsMotorola" SG_ 1001 VC_ECO_Indicator 1;
BA_ "FlexKomComment" SG_ 1001 VC_ECO_Indicator "Vehicle Configuration 2 Packet";
BA_ "GenSigSNA" SG_ 1001 VC_SKIM_PRSNT "0h";
BA_ "GenSigSendType" SG_ 1001 VC_SKIM_PRSNT 5;
BA_ "GenSigCycleTime" SG_ 1001 VC_SKIM_PRSNT 2000;
BA_ "FlexKomSigStartValue" SG_ 1001 VC_SKIM_PRSNT "0300FF00FFFFFFFFh";
BA_ "FlexKomSigStartPos" SG_ 1001 VC_SKIM_PRSNT 7;
BA_ "FlexKomSigName" SG_ 1001 VC_SKIM_PRSNT "VehCfg2_Pkt";
BA_ "FlexKomSigLaenge" SG_ 1001 VC_SKIM_PRSNT 64;
BA_ "FlexKomSID" SG_ 1001 VC_SKIM_PRSNT 887;
BA_ "FlexKomIsMotorola" SG_ 1001 VC_SKIM_PRSNT 1;
BA_ "FlexKomComment" SG_ 1001 VC_SKIM_PRSNT "Vehicle Configuration 2 Packet";
BA_ "GenSigSNA" SG_ 1001 VC_AC_Prsnt "0h";
BA_ "GenSigSendType" SG_ 1001 VC_AC_Prsnt 5;
BA_ "GenSigCycleTime" SG_ 1001 VC_AC_Prsnt 2000;
BA_ "FlexKomSigStartValue" SG_ 1001 VC_AC_Prsnt "0300FF00FFFFFFFFh";
BA_ "FlexKomSigStartPos" SG_ 1001 VC_AC_Prsnt 7;
BA_ "FlexKomSigName" SG_ 1001 VC_AC_Prsnt "VehCfg2_Pkt";
BA_ "FlexKomSigLaenge" SG_ 1001 VC_AC_Prsnt 64;
BA_ "FlexKomSID" SG_ 1001 VC_AC_Prsnt 887;
BA_ "FlexKomIsMotorola" SG_ 1001 VC_AC_Prsnt 1;
BA_ "FlexKomComment" SG_ 1001 VC_AC_Prsnt "Vehicle Configuration 2 Packet";
BA_ "GenSigTimeout_ORC" SG_ 1001 VC_PADS_Prsnt 7000;
BA_ "GenSigTimeout_IC" SG_ 1001 VC_PADS_Prsnt 21000;
BA_ "GenSigSNA" SG_ 1001 VC_PADS_Prsnt "0h";
BA_ "GenSigSendType" SG_ 1001 VC_PADS_Prsnt 5;
BA_ "GenSigCycleTime" SG_ 1001 VC_PADS_Prsnt 2000;
BA_ "FlexKomSigStartValue" SG_ 1001 VC_PADS_Prsnt "0300FF00FFFFFFFFh";
BA_ "FlexKomSigStartPos" SG_ 1001 VC_PADS_Prsnt 7;
BA_ "FlexKomSigName" SG_ 1001 VC_PADS_Prsnt "VehCfg2_Pkt";
BA_ "FlexKomSigLaenge" SG_ 1001 VC_PADS_Prsnt 64;
BA_ "FlexKomSID" SG_ 1001 VC_PADS_Prsnt 887;
BA_ "FlexKomIsMotorola" SG_ 1001 VC_PADS_Prsnt 1;
BA_ "FlexKomComment" SG_ 1001 VC_PADS_Prsnt "Vehicle Configuration 2 Packet";
BA_ "GenSigTimeout_IC" SG_ 1001 VC_RunFlatTirePrsnt 21000;
BA_ "GenSigSNA" SG_ 1001 VC_RunFlatTirePrsnt "0h";
BA_ "GenSigSendType" SG_ 1001 VC_RunFlatTirePrsnt 5;
BA_ "GenSigCycleTime" SG_ 1001 VC_RunFlatTirePrsnt 2000;
BA_ "FlexKomSigStartValue" SG_ 1001 VC_RunFlatTirePrsnt "0300FF00FFFFFFFFh";
BA_ "FlexKomSigStartPos" SG_ 1001 VC_RunFlatTirePrsnt 7;
BA_ "FlexKomSigName" SG_ 1001 VC_RunFlatTirePrsnt "VehCfg2_Pkt";
BA_ "FlexKomSigLaenge" SG_ 1001 VC_RunFlatTirePrsnt 64;
BA_ "FlexKomSID" SG_ 1001 VC_RunFlatTirePrsnt 887;
BA_ "FlexKomIsMotorola" SG_ 1001 VC_RunFlatTirePrsnt 1;
BA_ "FlexKomComment" SG_ 1001 VC_RunFlatTirePrsnt "Vehicle Configuration 2 Packet";
BA_ "GenSigTimeout_ORC" SG_ 1001 VC_VehCfg2_Stat 7000;
BA_ "GenSigTimeout_IC" SG_ 1001 VC_VehCfg2_Stat 21000;
BA_ "GenSigStartValue" SG_ 1001 VC_VehCfg2_Stat 3;
BA_ "GenSigSNA" SG_ 1001 VC_VehCfg2_Stat "3h";
BA_ "GenSigSendType" SG_ 1001 VC_VehCfg2_Stat 5;
BA_ "GenSigCycleTime" SG_ 1001 VC_VehCfg2_Stat 2000;
BA_ "FlexKomSigStartValue" SG_ 1001 VC_VehCfg2_Stat "0300FF00FFFFFFFFh";
BA_ "FlexKomSigStartPos" SG_ 1001 VC_VehCfg2_Stat 7;
BA_ "FlexKomSigName" SG_ 1001 VC_VehCfg2_Stat "VehCfg2_Pkt";
BA_ "FlexKomSigLaenge" SG_ 1001 VC_VehCfg2_Stat 64;
BA_ "FlexKomSID" SG_ 1001 VC_VehCfg2_Stat 887;
BA_ "FlexKomIsMotorola" SG_ 1001 VC_VehCfg2_Stat 1;
BA_ "FlexKomComment" SG_ 1001 VC_VehCfg2_Stat "Vehicle Configuration 2 Packet";
BA_ "GenSigSNA" SG_ 1001 VC_PwrIvtrTyp "0h";
BA_ "GenSigSendType" SG_ 1001 VC_PwrIvtrTyp 5;
BA_ "GenSigCycleTime" SG_ 1001 VC_PwrIvtrTyp 2000;
BA_ "FlexKomSigStartValue" SG_ 1001 VC_PwrIvtrTyp "0300FF00FFFFFFFFh";
BA_ "FlexKomSigStartPos" SG_ 1001 VC_PwrIvtrTyp 7;
BA_ "FlexKomSigName" SG_ 1001 VC_PwrIvtrTyp "VehCfg2_Pkt";
BA_ "FlexKomSigLaenge" SG_ 1001 VC_PwrIvtrTyp 64;
BA_ "FlexKomSID" SG_ 1001 VC_PwrIvtrTyp 887;
BA_ "FlexKomIsMotorola" SG_ 1001 VC_PwrIvtrTyp 1;
BA_ "FlexKomComment" SG_ 1001 VC_PwrIvtrTyp "Vehicle Configuration 2 Packet";
BA_ "GenSigTimeout_ORC" SG_ 1001 VC_SpecialPKG_IC 7000;
BA_ "GenSigTimeout_IC" SG_ 1001 VC_SpecialPKG_IC 21000;
BA_ "GenSigStartValue" SG_ 1001 VC_SpecialPKG_IC 255;
BA_ "GenSigSNA" SG_ 1001 VC_SpecialPKG_IC "FFh";
BA_ "GenSigSendType" SG_ 1001 VC_SpecialPKG_IC 5;
BA_ "GenSigCycleTime" SG_ 1001 VC_SpecialPKG_IC 2000;
BA_ "FlexKomSigStartValue" SG_ 1001 VC_SpecialPKG_IC "0300FF00FFFFFFFFh";
BA_ "FlexKomSigStartPos" SG_ 1001 VC_SpecialPKG_IC 7;
BA_ "FlexKomSigName" SG_ 1001 VC_SpecialPKG_IC "VehCfg2_Pkt";
BA_ "FlexKomSigLaenge" SG_ 1001 VC_SpecialPKG_IC 64;
BA_ "FlexKomSID" SG_ 1001 VC_SpecialPKG_IC 887;
BA_ "FlexKomIsMotorola" SG_ 1001 VC_SpecialPKG_IC 1;
BA_ "FlexKomComment" SG_ 1001 VC_SpecialPKG_IC "Vehicle Configuration 2 Packet";
BA_ "GenSigTimeout_IC" SG_ 1002 VC_PDDL_PRSNT 21000;
BA_ "GenSigSNA" SG_ 1002 VC_PDDL_PRSNT "0h";
BA_ "GenSigSendType" SG_ 1002 VC_PDDL_PRSNT 5;
BA_ "GenSigCycleTime" SG_ 1002 VC_PDDL_PRSNT 2000;
BA_ "FlexKomSigStartValue" SG_ 1002 VC_PDDL_PRSNT "0370FF037FFF0000h";
BA_ "FlexKomSigStartPos" SG_ 1002 VC_PDDL_PRSNT 7;
BA_ "FlexKomSigName" SG_ 1002 VC_PDDL_PRSNT "VehCfg3_Pkt";
BA_ "FlexKomSigLaenge" SG_ 1002 VC_PDDL_PRSNT 64;
BA_ "FlexKomSID" SG_ 1002 VC_PDDL_PRSNT 888;
BA_ "FlexKomIsMotorola" SG_ 1002 VC_PDDL_PRSNT 1;
BA_ "FlexKomComment" SG_ 1002 VC_PDDL_PRSNT "Vehicle Configuration 3 Packet";
BA_ "GenSigTimeout_IC" SG_ 1002 VC_SPORT_PRSNT 21000;
BA_ "GenSigSNA" SG_ 1002 VC_SPORT_PRSNT "0h";
BA_ "GenSigSendType" SG_ 1002 VC_SPORT_PRSNT 5;
BA_ "GenSigCycleTime" SG_ 1002 VC_SPORT_PRSNT 2000;
BA_ "FlexKomSigStartValue" SG_ 1002 VC_SPORT_PRSNT "0370FF037FFF0000h";
BA_ "FlexKomSigStartPos" SG_ 1002 VC_SPORT_PRSNT 7;
BA_ "FlexKomSigName" SG_ 1002 VC_SPORT_PRSNT "VehCfg3_Pkt";
BA_ "FlexKomSigLaenge" SG_ 1002 VC_SPORT_PRSNT 64;
BA_ "FlexKomSID" SG_ 1002 VC_SPORT_PRSNT 888;
BA_ "FlexKomIsMotorola" SG_ 1002 VC_SPORT_PRSNT 1;
BA_ "FlexKomComment" SG_ 1002 VC_SPORT_PRSNT "Vehicle Configuration 3 Packet";
BA_ "GenSigSNA" SG_ 1002 VC_HID_HL "0h";
BA_ "GenSigSendType" SG_ 1002 VC_HID_HL 5;
BA_ "GenSigCycleTime" SG_ 1002 VC_HID_HL 2000;
BA_ "FlexKomSigStartValue" SG_ 1002 VC_HID_HL "0370FF037FFF0000h";
BA_ "FlexKomSigStartPos" SG_ 1002 VC_HID_HL 7;
BA_ "FlexKomSigName" SG_ 1002 VC_HID_HL "VehCfg3_Pkt";
BA_ "FlexKomSigLaenge" SG_ 1002 VC_HID_HL 64;
BA_ "FlexKomSID" SG_ 1002 VC_HID_HL 888;
BA_ "FlexKomIsMotorola" SG_ 1002 VC_HID_HL 1;
BA_ "FlexKomComment" SG_ 1002 VC_HID_HL "Vehicle Configuration 3 Packet";
BA_ "GenSigSNA" SG_ 1002 VC_SecLkPrsnt "0h";
BA_ "GenSigSendType" SG_ 1002 VC_SecLkPrsnt 5;
BA_ "GenSigCycleTime" SG_ 1002 VC_SecLkPrsnt 2000;
BA_ "FlexKomSigStartValue" SG_ 1002 VC_SecLkPrsnt "0370FF037FFF0000h";
BA_ "FlexKomSigStartPos" SG_ 1002 VC_SecLkPrsnt 7;
BA_ "FlexKomSigName" SG_ 1002 VC_SecLkPrsnt "VehCfg3_Pkt";
BA_ "FlexKomSigLaenge" SG_ 1002 VC_SecLkPrsnt 64;
BA_ "FlexKomSID" SG_ 1002 VC_SecLkPrsnt 888;
BA_ "FlexKomIsMotorola" SG_ 1002 VC_SecLkPrsnt 1;
BA_ "FlexKomComment" SG_ 1002 VC_SecLkPrsnt "Vehicle Configuration 3 Packet";
BA_ "GenSigTimeout_IC" SG_ 1002 VC_Liftgate_Trunk 21000;
BA_ "GenSigSNA" SG_ 1002 VC_Liftgate_Trunk "3h";
BA_ "GenSigSendType" SG_ 1002 VC_Liftgate_Trunk 5;
BA_ "GenSigCycleTime" SG_ 1002 VC_Liftgate_Trunk 2000;
BA_ "FlexKomSigStartValue" SG_ 1002 VC_Liftgate_Trunk "0370FF037FFF0000h";
BA_ "FlexKomSigStartPos" SG_ 1002 VC_Liftgate_Trunk 7;
BA_ "FlexKomSigName" SG_ 1002 VC_Liftgate_Trunk "VehCfg3_Pkt";
BA_ "FlexKomSigLaenge" SG_ 1002 VC_Liftgate_Trunk 64;
BA_ "FlexKomSID" SG_ 1002 VC_Liftgate_Trunk 888;
BA_ "FlexKomIsMotorola" SG_ 1002 VC_Liftgate_Trunk 1;
BA_ "FlexKomComment" SG_ 1002 VC_Liftgate_Trunk "Vehicle Configuration 3 Packet";
BA_ "GenSigTimeout_ORC" SG_ 1002 VC_CMS 7000;
BA_ "GenSigSNA" SG_ 1002 VC_CMS "0h";
BA_ "GenSigSendType" SG_ 1002 VC_CMS 5;
BA_ "GenSigCycleTime" SG_ 1002 VC_CMS 2000;
BA_ "FlexKomSigStartValue" SG_ 1002 VC_CMS "0370FF037FFF0000h";
BA_ "FlexKomSigStartPos" SG_ 1002 VC_CMS 7;
BA_ "FlexKomSigName" SG_ 1002 VC_CMS "VehCfg3_Pkt";
BA_ "FlexKomSigLaenge" SG_ 1002 VC_CMS 64;
BA_ "FlexKomSID" SG_ 1002 VC_CMS 888;
BA_ "FlexKomIsMotorola" SG_ 1002 VC_CMS 1;
BA_ "FlexKomComment" SG_ 1002 VC_CMS "Vehicle Configuration 3 Packet";
BA_ "GenSigTimeout_ORC" SG_ 1002 VC_FCW 7000;
BA_ "GenSigSNA" SG_ 1002 VC_FCW "0h";
BA_ "GenSigSendType" SG_ 1002 VC_FCW 5;
BA_ "GenSigCycleTime" SG_ 1002 VC_FCW 2000;
BA_ "FlexKomSigStartValue" SG_ 1002 VC_FCW "0370FF037FFF0000h";
BA_ "FlexKomSigStartPos" SG_ 1002 VC_FCW 7;
BA_ "FlexKomSigName" SG_ 1002 VC_FCW "VehCfg3_Pkt";
BA_ "FlexKomSigLaenge" SG_ 1002 VC_FCW 64;
BA_ "FlexKomSID" SG_ 1002 VC_FCW 888;
BA_ "FlexKomIsMotorola" SG_ 1002 VC_FCW 1;
BA_ "FlexKomComment" SG_ 1002 VC_FCW "Vehicle Configuration 3 Packet";
BA_ "GenSigTimeout_ORC" SG_ 1002 VC_Base_TPM 7000;
BA_ "GenSigTimeout_IC" SG_ 1002 VC_Base_TPM 21000;
BA_ "GenSigSNA" SG_ 1002 VC_Base_TPM "0h";
BA_ "GenSigSendType" SG_ 1002 VC_Base_TPM 5;
BA_ "GenSigCycleTime" SG_ 1002 VC_Base_TPM 2000;
BA_ "FlexKomSigStartValue" SG_ 1002 VC_Base_TPM "0370FF037FFF0000h";
BA_ "FlexKomSigStartPos" SG_ 1002 VC_Base_TPM 7;
BA_ "FlexKomSigName" SG_ 1002 VC_Base_TPM "VehCfg3_Pkt";
BA_ "FlexKomSigLaenge" SG_ 1002 VC_Base_TPM 64;
BA_ "FlexKomSID" SG_ 1002 VC_Base_TPM 888;
BA_ "FlexKomIsMotorola" SG_ 1002 VC_Base_TPM 1;
BA_ "FlexKomComment" SG_ 1002 VC_Base_TPM "Vehicle Configuration 3 Packet";
BA_ "GenSigTimeout_IC" SG_ 1002 VC_TEMP_DISP 21000;
BA_ "GenSigSNA" SG_ 1002 VC_TEMP_DISP "0h";
BA_ "GenSigSendType" SG_ 1002 VC_TEMP_DISP 5;
BA_ "GenSigCycleTime" SG_ 1002 VC_TEMP_DISP 2000;
BA_ "FlexKomSigStartValue" SG_ 1002 VC_TEMP_DISP "0370FF037FFF0000h";
BA_ "FlexKomSigStartPos" SG_ 1002 VC_TEMP_DISP 7;
BA_ "FlexKomSigName" SG_ 1002 VC_TEMP_DISP "VehCfg3_Pkt";
BA_ "FlexKomSigLaenge" SG_ 1002 VC_TEMP_DISP 64;
BA_ "FlexKomSID" SG_ 1002 VC_TEMP_DISP 888;
BA_ "FlexKomIsMotorola" SG_ 1002 VC_TEMP_DISP 1;
BA_ "FlexKomComment" SG_ 1002 VC_TEMP_DISP "Vehicle Configuration 3 Packet";
BA_ "GenSigTimeout_IC" SG_ 1002 VC_HVAC_Config 21000;
BA_ "GenSigStartValue" SG_ 1002 VC_HVAC_Config 15;
BA_ "GenSigSNA" SG_ 1002 VC_HVAC_Config "Fh";
BA_ "GenSigSendType" SG_ 1002 VC_HVAC_Config 5;
BA_ "GenSigCycleTime" SG_ 1002 VC_HVAC_Config 2000;
BA_ "FlexKomSigStartValue" SG_ 1002 VC_HVAC_Config "0370FF037FFF0000h";
BA_ "FlexKomSigStartPos" SG_ 1002 VC_HVAC_Config 7;
BA_ "FlexKomSigName" SG_ 1002 VC_HVAC_Config "VehCfg3_Pkt";
BA_ "FlexKomSigLaenge" SG_ 1002 VC_HVAC_Config 64;
BA_ "FlexKomSID" SG_ 1002 VC_HVAC_Config 888;
BA_ "FlexKomIsMotorola" SG_ 1002 VC_HVAC_Config 1;
BA_ "FlexKomComment" SG_ 1002 VC_HVAC_Config "Vehicle Configuration 3 Packet";
BA_ "GenSigTimeout_IC" SG_ 1002 VC_VEH_BRAND 21000;
BA_ "GenSigStartValue" SG_ 1002 VC_VEH_BRAND 15;
BA_ "GenSigSNA" SG_ 1002 VC_VEH_BRAND "Fh";
BA_ "GenSigSendType" SG_ 1002 VC_VEH_BRAND 5;
BA_ "GenSigCycleTime" SG_ 1002 VC_VEH_BRAND 2000;
BA_ "FlexKomSigStartValue" SG_ 1002 VC_VEH_BRAND "0370FF037FFF0000h";
BA_ "FlexKomSigStartPos" SG_ 1002 VC_VEH_BRAND 7;
BA_ "FlexKomSigName" SG_ 1002 VC_VEH_BRAND "VehCfg3_Pkt";
BA_ "FlexKomSigLaenge" SG_ 1002 VC_VEH_BRAND 64;
BA_ "FlexKomSID" SG_ 1002 VC_VEH_BRAND 888;
BA_ "FlexKomIsMotorola" SG_ 1002 VC_VEH_BRAND 1;
BA_ "FlexKomComment" SG_ 1002 VC_VEH_BRAND "Vehicle Configuration 3 Packet";
BA_ "GenSigTimeout_IC" SG_ 1002 VC_CMP_DISP 21000;
BA_ "GenSigSNA" SG_ 1002 VC_CMP_DISP "0h";
BA_ "GenSigSendType" SG_ 1002 VC_CMP_DISP 5;
BA_ "GenSigCycleTime" SG_ 1002 VC_CMP_DISP 2000;
BA_ "FlexKomSigStartValue" SG_ 1002 VC_CMP_DISP "0370FF037FFF0000h";
BA_ "FlexKomSigStartPos" SG_ 1002 VC_CMP_DISP 7;
BA_ "FlexKomSigName" SG_ 1002 VC_CMP_DISP "VehCfg3_Pkt";
BA_ "FlexKomSigLaenge" SG_ 1002 VC_CMP_DISP 64;
BA_ "FlexKomSID" SG_ 1002 VC_CMP_DISP 888;
BA_ "FlexKomIsMotorola" SG_ 1002 VC_CMP_DISP 1;
BA_ "FlexKomComment" SG_ 1002 VC_CMP_DISP "Vehicle Configuration 3 Packet";
BA_ "GenSigSNA" SG_ 1002 VC_IntEC_MIRR "0h";
BA_ "GenSigSendType" SG_ 1002 VC_IntEC_MIRR 5;
BA_ "GenSigCycleTime" SG_ 1002 VC_IntEC_MIRR 2000;
BA_ "FlexKomSigStartValue" SG_ 1002 VC_IntEC_MIRR "0370FF037FFF0000h";
BA_ "FlexKomSigStartPos" SG_ 1002 VC_IntEC_MIRR 7;
BA_ "FlexKomSigName" SG_ 1002 VC_IntEC_MIRR "VehCfg3_Pkt";
BA_ "FlexKomSigLaenge" SG_ 1002 VC_IntEC_MIRR 64;
BA_ "FlexKomSID" SG_ 1002 VC_IntEC_MIRR 888;
BA_ "FlexKomIsMotorola" SG_ 1002 VC_IntEC_MIRR 1;
BA_ "FlexKomComment" SG_ 1002 VC_IntEC_MIRR "Vehicle Configuration 3 Packet";
BA_ "GenSigTimeout_ORC" SG_ 1002 VC_SRT_PRSNT 7000;
BA_ "GenSigTimeout_IC" SG_ 1002 VC_SRT_PRSNT 21000;
BA_ "GenSigSNA" SG_ 1002 VC_SRT_PRSNT "0h";
BA_ "GenSigSendType" SG_ 1002 VC_SRT_PRSNT 5;
BA_ "GenSigCycleTime" SG_ 1002 VC_SRT_PRSNT 2000;
BA_ "FlexKomSigStartValue" SG_ 1002 VC_SRT_PRSNT "0370FF037FFF0000h";
BA_ "FlexKomSigStartPos" SG_ 1002 VC_SRT_PRSNT 7;
BA_ "FlexKomSigName" SG_ 1002 VC_SRT_PRSNT "VehCfg3_Pkt";
BA_ "FlexKomSigLaenge" SG_ 1002 VC_SRT_PRSNT 64;
BA_ "FlexKomSID" SG_ 1002 VC_SRT_PRSNT 888;
BA_ "FlexKomIsMotorola" SG_ 1002 VC_SRT_PRSNT 1;
BA_ "FlexKomComment" SG_ 1002 VC_SRT_PRSNT "Vehicle Configuration 3 Packet";
BA_ "GenSigTimeout_IC" SG_ 1002 VC_DSBL_CLK_DISP 21000;
BA_ "GenSigSNA" SG_ 1002 VC_DSBL_CLK_DISP "0h";
BA_ "GenSigSendType" SG_ 1002 VC_DSBL_CLK_DISP 5;
BA_ "GenSigCycleTime" SG_ 1002 VC_DSBL_CLK_DISP 2000;
BA_ "FlexKomSigStartValue" SG_ 1002 VC_DSBL_CLK_DISP "0370FF037FFF0000h";
BA_ "FlexKomSigStartPos" SG_ 1002 VC_DSBL_CLK_DISP 7;
BA_ "FlexKomSigName" SG_ 1002 VC_DSBL_CLK_DISP "VehCfg3_Pkt";
BA_ "FlexKomSigLaenge" SG_ 1002 VC_DSBL_CLK_DISP 64;
BA_ "FlexKomSID" SG_ 1002 VC_DSBL_CLK_DISP 888;
BA_ "FlexKomIsMotorola" SG_ 1002 VC_DSBL_CLK_DISP 1;
BA_ "FlexKomComment" SG_ 1002 VC_DSBL_CLK_DISP "Vehicle Configuration 3 Packet";
BA_ "GenSigSNA" SG_ 1002 VC_SunShade_Present "0h";
BA_ "GenSigSendType" SG_ 1002 VC_SunShade_Present 5;
BA_ "GenSigCycleTime" SG_ 1002 VC_SunShade_Present 2000;
BA_ "FlexKomSigStartValue" SG_ 1002 VC_SunShade_Present "0370FF037FFF0000h";
BA_ "FlexKomSigStartPos" SG_ 1002 VC_SunShade_Present 7;
BA_ "FlexKomSigName" SG_ 1002 VC_SunShade_Present "VehCfg3_Pkt";
BA_ "FlexKomSigLaenge" SG_ 1002 VC_SunShade_Present 64;
BA_ "FlexKomSID" SG_ 1002 VC_SunShade_Present 888;
BA_ "FlexKomIsMotorola" SG_ 1002 VC_SunShade_Present 1;
BA_ "FlexKomComment" SG_ 1002 VC_SunShade_Present "Vehicle Configuration 3 Packet";
BA_ "GenSigStartValue" SG_ 1002 VC_WIN_EXPR_FEAT 3;
BA_ "GenSigSNA" SG_ 1002 VC_WIN_EXPR_FEAT "3h";
BA_ "GenSigSendType" SG_ 1002 VC_WIN_EXPR_FEAT 5;
BA_ "GenSigCycleTime" SG_ 1002 VC_WIN_EXPR_FEAT 2000;
BA_ "FlexKomSigStartValue" SG_ 1002 VC_WIN_EXPR_FEAT "0370FF037FFF0000h";
BA_ "FlexKomSigStartPos" SG_ 1002 VC_WIN_EXPR_FEAT 7;
BA_ "FlexKomSigName" SG_ 1002 VC_WIN_EXPR_FEAT "VehCfg3_Pkt";
BA_ "FlexKomSigLaenge" SG_ 1002 VC_WIN_EXPR_FEAT 64;
BA_ "FlexKomSID" SG_ 1002 VC_WIN_EXPR_FEAT 888;
BA_ "FlexKomIsMotorola" SG_ 1002 VC_WIN_EXPR_FEAT 1;
BA_ "FlexKomComment" SG_ 1002 VC_WIN_EXPR_FEAT "Vehicle Configuration 3 Packet";
BA_ "GenSigTimeout_IC" SG_ 1002 VC_DualFuelSens 21000;
BA_ "GenSigSNA" SG_ 1002 VC_DualFuelSens "0h";
BA_ "GenSigSendType" SG_ 1002 VC_DualFuelSens 5;
BA_ "GenSigCycleTime" SG_ 1002 VC_DualFuelSens 2000;
BA_ "FlexKomSigStartValue" SG_ 1002 VC_DualFuelSens "0370FF037FFF0000h";
BA_ "FlexKomSigStartPos" SG_ 1002 VC_DualFuelSens 7;
BA_ "FlexKomSigName" SG_ 1002 VC_DualFuelSens "VehCfg3_Pkt";
BA_ "FlexKomSigLaenge" SG_ 1002 VC_DualFuelSens 64;
BA_ "FlexKomSID" SG_ 1002 VC_DualFuelSens 888;
BA_ "FlexKomIsMotorola" SG_ 1002 VC_DualFuelSens 1;
BA_ "FlexKomComment" SG_ 1002 VC_DualFuelSens "Vehicle Configuration 3 Packet";
BA_ "GenSigTimeout_PTS" SG_ 1002 VC_ChassisType 21000;
BA_ "GenSigTimeout_ORC" SG_ 1002 VC_ChassisType 7000;
BA_ "GenSigTimeout_EHPS" SG_ 1002 VC_ChassisType 21000;
BA_ "GenSigStartValue" SG_ 1002 VC_ChassisType 127;
BA_ "GenSigSNA" SG_ 1002 VC_ChassisType "7Fh";
BA_ "GenSigSendType" SG_ 1002 VC_ChassisType 5;
BA_ "GenSigCycleTime" SG_ 1002 VC_ChassisType 2000;
BA_ "FlexKomSigStartValue" SG_ 1002 VC_ChassisType "0370FF037FFF0000h";
BA_ "FlexKomSigStartPos" SG_ 1002 VC_ChassisType 7;
BA_ "FlexKomSigName" SG_ 1002 VC_ChassisType "VehCfg3_Pkt";
BA_ "FlexKomSigLaenge" SG_ 1002 VC_ChassisType 64;
BA_ "FlexKomSID" SG_ 1002 VC_ChassisType 888;
BA_ "FlexKomIsMotorola" SG_ 1002 VC_ChassisType 1;
BA_ "FlexKomComment" SG_ 1002 VC_ChassisType "Vehicle Configuration 3 Packet";
BA_ "GenSigSNA" SG_ 1002 VC_ESCL_PRSNT "0h";
BA_ "GenSigSendType" SG_ 1002 VC_ESCL_PRSNT 5;
BA_ "GenSigCycleTime" SG_ 1002 VC_ESCL_PRSNT 2000;
BA_ "FlexKomSigStartValue" SG_ 1002 VC_ESCL_PRSNT "0370FF037FFF0000h";
BA_ "FlexKomSigStartPos" SG_ 1002 VC_ESCL_PRSNT 7;
BA_ "FlexKomSigName" SG_ 1002 VC_ESCL_PRSNT "VehCfg3_Pkt";
BA_ "FlexKomSigLaenge" SG_ 1002 VC_ESCL_PRSNT 64;
BA_ "FlexKomSID" SG_ 1002 VC_ESCL_PRSNT 888;
BA_ "FlexKomIsMotorola" SG_ 1002 VC_ESCL_PRSNT 1;
BA_ "FlexKomComment" SG_ 1002 VC_ESCL_PRSNT "Vehicle Configuration 3 Packet";
BA_ "GenSigTimeout_ORC" SG_ 1002 VC_Prem_TPM 7000;
BA_ "GenSigTimeout_IC" SG_ 1002 VC_Prem_TPM 21000;
BA_ "GenSigSNA" SG_ 1002 VC_Prem_TPM "0h";
BA_ "GenSigSendType" SG_ 1002 VC_Prem_TPM 5;
BA_ "GenSigCycleTime" SG_ 1002 VC_Prem_TPM 2000;
BA_ "FlexKomSigStartValue" SG_ 1002 VC_Prem_TPM "0370FF037FFF0000h";
BA_ "FlexKomSigStartPos" SG_ 1002 VC_Prem_TPM 7;
BA_ "FlexKomSigName" SG_ 1002 VC_Prem_TPM "VehCfg3_Pkt";
BA_ "FlexKomSigLaenge" SG_ 1002 VC_Prem_TPM 64;
BA_ "FlexKomSID" SG_ 1002 VC_Prem_TPM 888;
BA_ "FlexKomIsMotorola" SG_ 1002 VC_Prem_TPM 1;
BA_ "FlexKomComment" SG_ 1002 VC_Prem_TPM "Vehicle Configuration 3 Packet";
BA_ "GenSigTimeout_IC" SG_ 1002 VC_AutoParkPrsnt 21000;
BA_ "GenSigSNA" SG_ 1002 VC_AutoParkPrsnt "0h";
BA_ "GenSigSendType" SG_ 1002 VC_AutoParkPrsnt 5;
BA_ "GenSigCycleTime" SG_ 1002 VC_AutoParkPrsnt 2000;
BA_ "FlexKomSigStartValue" SG_ 1002 VC_AutoParkPrsnt "0370FF037FFF0000h";
BA_ "FlexKomSigStartPos" SG_ 1002 VC_AutoParkPrsnt 7;
BA_ "FlexKomSigName" SG_ 1002 VC_AutoParkPrsnt "VehCfg3_Pkt";
BA_ "FlexKomSigLaenge" SG_ 1002 VC_AutoParkPrsnt 64;
BA_ "FlexKomSID" SG_ 1002 VC_AutoParkPrsnt 888;
BA_ "FlexKomIsMotorola" SG_ 1002 VC_AutoParkPrsnt 1;
BA_ "FlexKomComment" SG_ 1002 VC_AutoParkPrsnt "Vehicle Configuration 3 Packet";
BA_ "GenSigSNA" SG_ 1002 VC_ADJ_PDL_PRSNT "0h";
BA_ "GenSigSendType" SG_ 1002 VC_ADJ_PDL_PRSNT 5;
BA_ "GenSigCycleTime" SG_ 1002 VC_ADJ_PDL_PRSNT 2000;
BA_ "FlexKomSigStartValue" SG_ 1002 VC_ADJ_PDL_PRSNT "0370FF037FFF0000h";
BA_ "FlexKomSigStartPos" SG_ 1002 VC_ADJ_PDL_PRSNT 7;
BA_ "FlexKomSigName" SG_ 1002 VC_ADJ_PDL_PRSNT "VehCfg3_Pkt";
BA_ "FlexKomSigLaenge" SG_ 1002 VC_ADJ_PDL_PRSNT 64;
BA_ "FlexKomSID" SG_ 1002 VC_ADJ_PDL_PRSNT 888;
BA_ "FlexKomIsMotorola" SG_ 1002 VC_ADJ_PDL_PRSNT 1;
BA_ "FlexKomComment" SG_ 1002 VC_ADJ_PDL_PRSNT "Vehicle Configuration 3 Packet";
BA_ "GenSigTimeout_IC" SG_ 1002 VC_AUTO_HL 21000;
BA_ "GenSigSNA" SG_ 1002 VC_AUTO_HL "0h";
BA_ "GenSigSendType" SG_ 1002 VC_AUTO_HL 5;
BA_ "GenSigCycleTime" SG_ 1002 VC_AUTO_HL 2000;
BA_ "FlexKomSigStartValue" SG_ 1002 VC_AUTO_HL "0370FF037FFF0000h";
BA_ "FlexKomSigStartPos" SG_ 1002 VC_AUTO_HL 7;
BA_ "FlexKomSigName" SG_ 1002 VC_AUTO_HL "VehCfg3_Pkt";
BA_ "FlexKomSigLaenge" SG_ 1002 VC_AUTO_HL 64;
BA_ "FlexKomSID" SG_ 1002 VC_AUTO_HL 888;
BA_ "FlexKomIsMotorola" SG_ 1002 VC_AUTO_HL 1;
BA_ "FlexKomComment" SG_ 1002 VC_AUTO_HL "Vehicle Configuration 3 Packet";
BA_ "GenSigTimeout_IC" SG_ 1002 VC_DrAlrPrsnt 21000;
BA_ "GenSigSNA" SG_ 1002 VC_DrAlrPrsnt "0h";
BA_ "GenSigSendType" SG_ 1002 VC_DrAlrPrsnt 5;
BA_ "GenSigCycleTime" SG_ 1002 VC_DrAlrPrsnt 2000;
BA_ "FlexKomSigStartValue" SG_ 1002 VC_DrAlrPrsnt "0370FF037FFF0000h";
BA_ "FlexKomSigStartPos" SG_ 1002 VC_DrAlrPrsnt 7;
BA_ "FlexKomSigName" SG_ 1002 VC_DrAlrPrsnt "VehCfg3_Pkt";
BA_ "FlexKomSigLaenge" SG_ 1002 VC_DrAlrPrsnt 64;
BA_ "FlexKomSID" SG_ 1002 VC_DrAlrPrsnt 888;
BA_ "FlexKomIsMotorola" SG_ 1002 VC_DrAlrPrsnt 1;
BA_ "FlexKomComment" SG_ 1002 VC_DrAlrPrsnt "Vehicle Configuration 3 Packet";
BA_ "GenSigTimeout_ORC" SG_ 1002 VC_WHL_BASE 7000;
BA_ "GenSigStartValue" SG_ 1002 VC_WHL_BASE 3;
BA_ "GenSigSNA" SG_ 1002 VC_WHL_BASE "3h";
BA_ "GenSigSendType" SG_ 1002 VC_WHL_BASE 5;
BA_ "GenSigCycleTime" SG_ 1002 VC_WHL_BASE 2000;
BA_ "FlexKomSigStartValue" SG_ 1002 VC_WHL_BASE "0370FF037FFF0000h";
BA_ "FlexKomSigStartPos" SG_ 1002 VC_WHL_BASE 7;
BA_ "FlexKomSigName" SG_ 1002 VC_WHL_BASE "VehCfg3_Pkt";
BA_ "FlexKomSigLaenge" SG_ 1002 VC_WHL_BASE 64;
BA_ "FlexKomSID" SG_ 1002 VC_WHL_BASE 888;
BA_ "FlexKomIsMotorola" SG_ 1002 VC_WHL_BASE 1;
BA_ "FlexKomComment" SG_ 1002 VC_WHL_BASE "Vehicle Configuration 3 Packet";
BA_ "GenSigStartValue" SG_ 1002 VC_FOBIKsafeENBL 1;
BA_ "GenSigSNA" SG_ 1002 VC_FOBIKsafeENBL "1h";
BA_ "GenSigSendType" SG_ 1002 VC_FOBIKsafeENBL 5;
BA_ "GenSigCycleTime" SG_ 1002 VC_FOBIKsafeENBL 2000;
BA_ "FlexKomSigStartValue" SG_ 1002 VC_FOBIKsafeENBL "0370FF037FFF0000h";
BA_ "FlexKomSigStartPos" SG_ 1002 VC_FOBIKsafeENBL 7;
BA_ "FlexKomSigName" SG_ 1002 VC_FOBIKsafeENBL "VehCfg3_Pkt";
BA_ "FlexKomSigLaenge" SG_ 1002 VC_FOBIKsafeENBL 64;
BA_ "FlexKomSID" SG_ 1002 VC_FOBIKsafeENBL 888;
BA_ "FlexKomIsMotorola" SG_ 1002 VC_FOBIKsafeENBL 1;
BA_ "FlexKomComment" SG_ 1002 VC_FOBIKsafeENBL "Vehicle Configuration 3 Packet";
BA_ "GenSigSNA" SG_ 1002 VC_ELV_Prsnt "0h";
BA_ "GenSigSendType" SG_ 1002 VC_ELV_Prsnt 5;
BA_ "GenSigCycleTime" SG_ 1002 VC_ELV_Prsnt 2000;
BA_ "FlexKomSigStartValue" SG_ 1002 VC_ELV_Prsnt "0370FF037FFF0000h";
BA_ "FlexKomSigStartPos" SG_ 1002 VC_ELV_Prsnt 7;
BA_ "FlexKomSigName" SG_ 1002 VC_ELV_Prsnt "VehCfg3_Pkt";
BA_ "FlexKomSigLaenge" SG_ 1002 VC_ELV_Prsnt 64;
BA_ "FlexKomSID" SG_ 1002 VC_ELV_Prsnt 888;
BA_ "FlexKomIsMotorola" SG_ 1002 VC_ELV_Prsnt 1;
BA_ "FlexKomComment" SG_ 1002 VC_ELV_Prsnt "Vehicle Configuration 3 Packet";
BA_ "GenSigTimeout_IC" SG_ 1002 VC_FUEL_CAP 21000;
BA_ "GenSigStartValue" SG_ 1002 VC_FUEL_CAP 255;
BA_ "GenSigSNA" SG_ 1002 VC_FUEL_CAP "FFh";
BA_ "GenSigSendType" SG_ 1002 VC_FUEL_CAP 5;
BA_ "GenSigCycleTime" SG_ 1002 VC_FUEL_CAP 2000;
BA_ "FlexKomSigStartValue" SG_ 1002 VC_FUEL_CAP "0370FF037FFF0000h";
BA_ "FlexKomSigStartPos" SG_ 1002 VC_FUEL_CAP 7;
BA_ "FlexKomSigName" SG_ 1002 VC_FUEL_CAP "VehCfg3_Pkt";
BA_ "FlexKomSigLaenge" SG_ 1002 VC_FUEL_CAP 64;
BA_ "FlexKomSID" SG_ 1002 VC_FUEL_CAP 888;
BA_ "FlexKomIsMotorola" SG_ 1002 VC_FUEL_CAP 1;
BA_ "FlexKomComment" SG_ 1002 VC_FUEL_CAP "Vehicle Configuration 3 Packet";
BA_ "GenSigTimeout_ORC" SG_ 1002 VC_VehCfg3_Stat 7000;
BA_ "GenSigTimeout_IC" SG_ 1002 VC_VehCfg3_Stat 21000;
BA_ "GenSigTimeout_EHPS" SG_ 1002 VC_VehCfg3_Stat 21000;
BA_ "GenSigStartValue" SG_ 1002 VC_VehCfg3_Stat 3;
BA_ "GenSigSNA" SG_ 1002 VC_VehCfg3_Stat "3h";
BA_ "GenSigSendType" SG_ 1002 VC_VehCfg3_Stat 5;
BA_ "GenSigCycleTime" SG_ 1002 VC_VehCfg3_Stat 2000;
BA_ "FlexKomSigStartValue" SG_ 1002 VC_VehCfg3_Stat "0370FF037FFF0000h";
BA_ "FlexKomSigStartPos" SG_ 1002 VC_VehCfg3_Stat 7;
BA_ "FlexKomSigName" SG_ 1002 VC_VehCfg3_Stat "VehCfg3_Pkt";
BA_ "FlexKomSigLaenge" SG_ 1002 VC_VehCfg3_Stat 64;
BA_ "FlexKomSID" SG_ 1002 VC_VehCfg3_Stat 888;
BA_ "FlexKomIsMotorola" SG_ 1002 VC_VehCfg3_Stat 1;
BA_ "FlexKomComment" SG_ 1002 VC_VehCfg3_Stat "Vehicle Configuration 3 Packet";
BA_ "GenSigTimeout_ORC" SG_ 1002 VC_POLICE 7000;
BA_ "GenSigTimeout_IC" SG_ 1002 VC_POLICE 21000;
BA_ "GenSigSNA" SG_ 1002 VC_POLICE "0h";
BA_ "GenSigSendType" SG_ 1002 VC_POLICE 5;
BA_ "GenSigCycleTime" SG_ 1002 VC_POLICE 2000;
BA_ "FlexKomSigStartValue" SG_ 1002 VC_POLICE "0370FF037FFF0000h";
BA_ "FlexKomSigStartPos" SG_ 1002 VC_POLICE 7;
BA_ "FlexKomSigName" SG_ 1002 VC_POLICE "VehCfg3_Pkt";
BA_ "FlexKomSigLaenge" SG_ 1002 VC_POLICE 64;
BA_ "FlexKomSID" SG_ 1002 VC_POLICE 888;
BA_ "FlexKomIsMotorola" SG_ 1002 VC_POLICE 1;
BA_ "FlexKomComment" SG_ 1002 VC_POLICE "Vehicle Configuration 3 Packet";
BA_ "GenSigSNA" SG_ 1002 VC_PWR_LFT_GT "0h";
BA_ "GenSigSendType" SG_ 1002 VC_PWR_LFT_GT 5;
BA_ "GenSigCycleTime" SG_ 1002 VC_PWR_LFT_GT 2000;
BA_ "FlexKomSigStartValue" SG_ 1002 VC_PWR_LFT_GT "0370FF037FFF0000h";
BA_ "FlexKomSigStartPos" SG_ 1002 VC_PWR_LFT_GT 7;
BA_ "FlexKomSigName" SG_ 1002 VC_PWR_LFT_GT "VehCfg3_Pkt";
BA_ "FlexKomSigLaenge" SG_ 1002 VC_PWR_LFT_GT 64;
BA_ "FlexKomSID" SG_ 1002 VC_PWR_LFT_GT 888;
BA_ "FlexKomIsMotorola" SG_ 1002 VC_PWR_LFT_GT 1;
BA_ "FlexKomComment" SG_ 1002 VC_PWR_LFT_GT "Vehicle Configuration 3 Packet";
BA_ "GenSigSNA" SG_ 1002 VC_PWR_RT_SLDR "0h";
BA_ "GenSigSendType" SG_ 1002 VC_PWR_RT_SLDR 5;
BA_ "GenSigCycleTime" SG_ 1002 VC_PWR_RT_SLDR 2000;
BA_ "FlexKomSigStartValue" SG_ 1002 VC_PWR_RT_SLDR "0370FF037FFF0000h";
BA_ "FlexKomSigStartPos" SG_ 1002 VC_PWR_RT_SLDR 7;
BA_ "FlexKomSigName" SG_ 1002 VC_PWR_RT_SLDR "VehCfg3_Pkt";
BA_ "FlexKomSigLaenge" SG_ 1002 VC_PWR_RT_SLDR 64;
BA_ "FlexKomSID" SG_ 1002 VC_PWR_RT_SLDR 888;
BA_ "FlexKomIsMotorola" SG_ 1002 VC_PWR_RT_SLDR 1;
BA_ "FlexKomComment" SG_ 1002 VC_PWR_RT_SLDR "Vehicle Configuration 3 Packet";
BA_ "GenSigSNA" SG_ 1002 VC_PWR_LT_SLDR "0h";
BA_ "GenSigSendType" SG_ 1002 VC_PWR_LT_SLDR 5;
BA_ "GenSigCycleTime" SG_ 1002 VC_PWR_LT_SLDR 2000;
BA_ "FlexKomSigStartValue" SG_ 1002 VC_PWR_LT_SLDR "0370FF037FFF0000h";
BA_ "FlexKomSigStartPos" SG_ 1002 VC_PWR_LT_SLDR 7;
BA_ "FlexKomSigName" SG_ 1002 VC_PWR_LT_SLDR "VehCfg3_Pkt";
BA_ "FlexKomSigLaenge" SG_ 1002 VC_PWR_LT_SLDR 64;
BA_ "FlexKomSID" SG_ 1002 VC_PWR_LT_SLDR 888;
BA_ "FlexKomIsMotorola" SG_ 1002 VC_PWR_LT_SLDR 1;
BA_ "FlexKomComment" SG_ 1002 VC_PWR_LT_SLDR "Vehicle Configuration 3 Packet";
BA_ "GenSigTimeout_IC" SG_ 1002 VC_RKE_PRSNT 21000;
BA_ "GenSigSNA" SG_ 1002 VC_RKE_PRSNT "0h";
BA_ "GenSigSendType" SG_ 1002 VC_RKE_PRSNT 5;
BA_ "GenSigCycleTime" SG_ 1002 VC_RKE_PRSNT 2000;
BA_ "FlexKomSigStartValue" SG_ 1002 VC_RKE_PRSNT "0370FF037FFF0000h";
BA_ "FlexKomSigStartPos" SG_ 1002 VC_RKE_PRSNT 7;
BA_ "FlexKomSigName" SG_ 1002 VC_RKE_PRSNT "VehCfg3_Pkt";
BA_ "FlexKomSigLaenge" SG_ 1002 VC_RKE_PRSNT 64;
BA_ "FlexKomSID" SG_ 1002 VC_RKE_PRSNT 888;
BA_ "FlexKomIsMotorola" SG_ 1002 VC_RKE_PRSNT 1;
BA_ "FlexKomComment" SG_ 1002 VC_RKE_PRSNT "Vehicle Configuration 3 Packet";
BA_ "GenSigSNA" SG_ 1002 VC_TcaseTyp "0h";
BA_ "GenSigSendType" SG_ 1002 VC_TcaseTyp 5;
BA_ "GenSigCycleTime" SG_ 1002 VC_TcaseTyp 2000;
BA_ "FlexKomSigStartValue" SG_ 1002 VC_TcaseTyp "0370FF037FFF0000h";
BA_ "FlexKomSigStartPos" SG_ 1002 VC_TcaseTyp 7;
BA_ "FlexKomSigName" SG_ 1002 VC_TcaseTyp "VehCfg3_Pkt";
BA_ "FlexKomSigLaenge" SG_ 1002 VC_TcaseTyp 64;
BA_ "FlexKomSID" SG_ 1002 VC_TcaseTyp 888;
BA_ "FlexKomIsMotorola" SG_ 1002 VC_TcaseTyp 1;
BA_ "FlexKomComment" SG_ 1002 VC_TcaseTyp "Vehicle Configuration 3 Packet";
BA_ "GenSigTimeout_IC" SG_ 1002 VC_PE_Prsnt 21000;
BA_ "GenSigSNA" SG_ 1002 VC_PE_Prsnt "0h";
BA_ "GenSigSendType" SG_ 1002 VC_PE_Prsnt 5;
BA_ "GenSigCycleTime" SG_ 1002 VC_PE_Prsnt 2000;
BA_ "FlexKomSigStartValue" SG_ 1002 VC_PE_Prsnt "0370FF037FFF0000h";
BA_ "FlexKomSigStartPos" SG_ 1002 VC_PE_Prsnt 7;
BA_ "FlexKomSigName" SG_ 1002 VC_PE_Prsnt "VehCfg3_Pkt";
BA_ "FlexKomSigLaenge" SG_ 1002 VC_PE_Prsnt 64;
BA_ "FlexKomSID" SG_ 1002 VC_PE_Prsnt 888;
BA_ "FlexKomIsMotorola" SG_ 1002 VC_PE_Prsnt 1;
BA_ "FlexKomComment" SG_ 1002 VC_PE_Prsnt "Vehicle Configuration 3 Packet";
BA_ "GenSigTimeout_IC" SG_ 1002 VC_KG_Prsnt 21000;
BA_ "GenSigSNA" SG_ 1002 VC_KG_Prsnt "0h";
BA_ "GenSigSendType" SG_ 1002 VC_KG_Prsnt 5;
BA_ "GenSigCycleTime" SG_ 1002 VC_KG_Prsnt 2000;
BA_ "FlexKomSigStartValue" SG_ 1002 VC_KG_Prsnt "0370FF037FFF0000h";
BA_ "FlexKomSigStartPos" SG_ 1002 VC_KG_Prsnt 7;
BA_ "FlexKomSigName" SG_ 1002 VC_KG_Prsnt "VehCfg3_Pkt";
BA_ "FlexKomSigLaenge" SG_ 1002 VC_KG_Prsnt 64;
BA_ "FlexKomSID" SG_ 1002 VC_KG_Prsnt 888;
BA_ "FlexKomIsMotorola" SG_ 1002 VC_KG_Prsnt 1;
BA_ "FlexKomComment" SG_ 1002 VC_KG_Prsnt "Vehicle Configuration 3 Packet";
BA_ "GenSigTimeout_TCM" SG_ 1003 VC_TCASE_HI_RATIO 3500;
BA_ "GenSigStartValue" SG_ 1003 VC_TCASE_HI_RATIO 16383;
BA_ "GenSigSNA" SG_ 1003 VC_TCASE_HI_RATIO "3FFFh";
BA_ "GenSigSendType" SG_ 1003 VC_TCASE_HI_RATIO 5;
BA_ "GenSigCycleTime" SG_ 1003 VC_TCASE_HI_RATIO 1000;
BA_ "FlexKomSigStartValue" SG_ 1003 VC_TCASE_HI_RATIO "FFFFFFFFFFFFFFFFh";
BA_ "FlexKomSigStartPos" SG_ 1003 VC_TCASE_HI_RATIO 7;
BA_ "FlexKomSigName" SG_ 1003 VC_TCASE_HI_RATIO "VehCfg4_Pkt";
BA_ "FlexKomSigLaenge" SG_ 1003 VC_TCASE_HI_RATIO 64;
BA_ "FlexKomSID" SG_ 1003 VC_TCASE_HI_RATIO 1035;
BA_ "FlexKomIsMotorola" SG_ 1003 VC_TCASE_HI_RATIO 1;
BA_ "FlexKomComment" SG_ 1003 VC_TCASE_HI_RATIO "Vehicle Configuration 4 Packet";
BA_ "GenSigTimeout_TCM" SG_ 1003 VC_AXLE_RATIO 3500;
BA_ "GenSigStartValue" SG_ 1003 VC_AXLE_RATIO 65535;
BA_ "GenSigSNA" SG_ 1003 VC_AXLE_RATIO "FFFFh";
BA_ "GenSigSendType" SG_ 1003 VC_AXLE_RATIO 5;
BA_ "GenSigCycleTime" SG_ 1003 VC_AXLE_RATIO 1000;
BA_ "FlexKomSigStartValue" SG_ 1003 VC_AXLE_RATIO "FFFFFFFFFFFFFFFFh";
BA_ "FlexKomSigStartPos" SG_ 1003 VC_AXLE_RATIO 7;
BA_ "FlexKomSigName" SG_ 1003 VC_AXLE_RATIO "VehCfg4_Pkt";
BA_ "FlexKomSigLaenge" SG_ 1003 VC_AXLE_RATIO 64;
BA_ "FlexKomSID" SG_ 1003 VC_AXLE_RATIO 1035;
BA_ "FlexKomIsMotorola" SG_ 1003 VC_AXLE_RATIO 1;
BA_ "FlexKomComment" SG_ 1003 VC_AXLE_RATIO "Vehicle Configuration 4 Packet";
BA_ "GenSigTimeout_TCM" SG_ 1003 VC_TCASE_LO_RATIO 3500;
BA_ "GenSigStartValue" SG_ 1003 VC_TCASE_LO_RATIO 65535;
BA_ "GenSigSNA" SG_ 1003 VC_TCASE_LO_RATIO "FFFFh";
BA_ "GenSigSendType" SG_ 1003 VC_TCASE_LO_RATIO 5;
BA_ "GenSigCycleTime" SG_ 1003 VC_TCASE_LO_RATIO 1000;
BA_ "FlexKomSigStartValue" SG_ 1003 VC_TCASE_LO_RATIO "FFFFFFFFFFFFFFFFh";
BA_ "FlexKomSigStartPos" SG_ 1003 VC_TCASE_LO_RATIO 7;
BA_ "FlexKomSigName" SG_ 1003 VC_TCASE_LO_RATIO "VehCfg4_Pkt";
BA_ "FlexKomSigLaenge" SG_ 1003 VC_TCASE_LO_RATIO 64;
BA_ "FlexKomSID" SG_ 1003 VC_TCASE_LO_RATIO 1035;
BA_ "FlexKomIsMotorola" SG_ 1003 VC_TCASE_LO_RATIO 1;
BA_ "FlexKomComment" SG_ 1003 VC_TCASE_LO_RATIO "Vehicle Configuration 4 Packet";
BA_ "GenSigTimeout_ORC" SG_ 1003 VC_TIRE_CIRCUMF 3500;
BA_ "GenSigTimeout_EHPS" SG_ 1003 VC_TIRE_CIRCUMF 10500;
BA_ "GenSigTimeout_DTCM" SG_ 1003 VC_TIRE_CIRCUMF 5500;
BA_ "GenSigStartValue" SG_ 1003 VC_TIRE_CIRCUMF 65535;
BA_ "GenSigSNA" SG_ 1003 VC_TIRE_CIRCUMF "FFFFh";
BA_ "GenSigSendType" SG_ 1003 VC_TIRE_CIRCUMF 5;
BA_ "GenSigCycleTime" SG_ 1003 VC_TIRE_CIRCUMF 1000;
BA_ "FlexKomSigStartValue" SG_ 1003 VC_TIRE_CIRCUMF "FFFFFFFFFFFFFFFFh";
BA_ "FlexKomSigStartPos" SG_ 1003 VC_TIRE_CIRCUMF 7;
BA_ "FlexKomSigName" SG_ 1003 VC_TIRE_CIRCUMF "VehCfg4_Pkt";
BA_ "FlexKomSigLaenge" SG_ 1003 VC_TIRE_CIRCUMF 64;
BA_ "FlexKomSID" SG_ 1003 VC_TIRE_CIRCUMF 1035;
BA_ "FlexKomIsMotorola" SG_ 1003 VC_TIRE_CIRCUMF 1;
BA_ "FlexKomComment" SG_ 1003 VC_TIRE_CIRCUMF "Vehicle Configuration 4 Packet";
BA_ "GenSigTimeout_RF_HUB" SG_ 1003 VC_VehCfg4_Stat 10500;
BA_ "GenSigTimeout_ORC" SG_ 1003 VC_VehCfg4_Stat 3500;
BA_ "GenSigTimeout_EHPS" SG_ 1003 VC_VehCfg4_Stat 10500;
BA_ "GenSigStartValue" SG_ 1003 VC_VehCfg4_Stat 3;
BA_ "GenSigSNA" SG_ 1003 VC_VehCfg4_Stat "3h";
BA_ "GenSigSendType" SG_ 1003 VC_VehCfg4_Stat 5;
BA_ "GenSigCycleTime" SG_ 1003 VC_VehCfg4_Stat 1000;
BA_ "FlexKomSigStartValue" SG_ 1003 VC_VehCfg4_Stat "FFFFFFFFFFFFFFFFh";
BA_ "FlexKomSigStartPos" SG_ 1003 VC_VehCfg4_Stat 7;
BA_ "FlexKomSigName" SG_ 1003 VC_VehCfg4_Stat "VehCfg4_Pkt";
BA_ "FlexKomSigLaenge" SG_ 1003 VC_VehCfg4_Stat 64;
BA_ "FlexKomSID" SG_ 1003 VC_VehCfg4_Stat 1035;
BA_ "FlexKomIsMotorola" SG_ 1003 VC_VehCfg4_Stat 1;
BA_ "FlexKomComment" SG_ 1003 VC_VehCfg4_Stat "Vehicle Configuration 4 Packet";
BA_ "GenSigStartValue" SG_ 1004 VC_BU_VehCfg1_Stat 3;
BA_ "GenSigSNA" SG_ 1004 VC_BU_VehCfg1_Stat "3h";
BA_ "GenSigSendType" SG_ 1004 VC_BU_VehCfg1_Stat 1;
BA_ "FlexKomSigStartValue" SG_ 1004 VC_BU_VehCfg1_Stat "FFFF7FF0FF0FFF00h";
BA_ "FlexKomSigStartPos" SG_ 1004 VC_BU_VehCfg1_Stat 7;
BA_ "FlexKomSigName" SG_ 1004 VC_BU_VehCfg1_Stat "VehCfgBU1_Pkt";
BA_ "FlexKomSigLaenge" SG_ 1004 VC_BU_VehCfg1_Stat 64;
BA_ "FlexKomSID" SG_ 1004 VC_BU_VehCfg1_Stat 919;
BA_ "FlexKomIsMotorola" SG_ 1004 VC_BU_VehCfg1_Stat 1;
BA_ "FlexKomComment" SG_ 1004 VC_BU_VehCfg1_Stat "Backup for Vehicle Configuration 1 Packet";
BA_ "GenSigStartValue" SG_ 1004 VC_BU_COUNTRY 31;
BA_ "GenSigSNA" SG_ 1004 VC_BU_COUNTRY "1Fh";
BA_ "GenSigSendType" SG_ 1004 VC_BU_COUNTRY 1;
BA_ "FlexKomSigStartValue" SG_ 1004 VC_BU_COUNTRY "FFFF7FF0FF0FFF00h";
BA_ "FlexKomSigStartPos" SG_ 1004 VC_BU_COUNTRY 7;
BA_ "FlexKomSigName" SG_ 1004 VC_BU_COUNTRY "VehCfgBU1_Pkt";
BA_ "FlexKomSigLaenge" SG_ 1004 VC_BU_COUNTRY 64;
BA_ "FlexKomSID" SG_ 1004 VC_BU_COUNTRY 919;
BA_ "FlexKomIsMotorola" SG_ 1004 VC_BU_COUNTRY 1;
BA_ "FlexKomComment" SG_ 1004 VC_BU_COUNTRY "Backup for Vehicle Configuration 1 Packet";
BA_ "GenSigStartValue" SG_ 1004 VC_BU_MAX_VEH_SPD 255;
BA_ "GenSigSNA" SG_ 1004 VC_BU_MAX_VEH_SPD "FFh";
BA_ "GenSigSendType" SG_ 1004 VC_BU_MAX_VEH_SPD 1;
BA_ "FlexKomSigStartValue" SG_ 1004 VC_BU_MAX_VEH_SPD "FFFF7FF0FF0FFF00h";
BA_ "FlexKomSigStartPos" SG_ 1004 VC_BU_MAX_VEH_SPD 7;
BA_ "FlexKomSigName" SG_ 1004 VC_BU_MAX_VEH_SPD "VehCfgBU1_Pkt";
BA_ "FlexKomSigLaenge" SG_ 1004 VC_BU_MAX_VEH_SPD 64;
BA_ "FlexKomSID" SG_ 1004 VC_BU_MAX_VEH_SPD 919;
BA_ "FlexKomIsMotorola" SG_ 1004 VC_BU_MAX_VEH_SPD 1;
BA_ "FlexKomComment" SG_ 1004 VC_BU_MAX_VEH_SPD "Backup for Vehicle Configuration 1 Packet";
BA_ "GenSigSNA" SG_ 1004 VC_BU_PTS_DispTyp "7h";
BA_ "GenSigSendType" SG_ 1004 VC_BU_PTS_DispTyp 1;
BA_ "FlexKomSigStartValue" SG_ 1004 VC_BU_PTS_DispTyp "FFFF7FF0FF0FFF00h";
BA_ "FlexKomSigStartPos" SG_ 1004 VC_BU_PTS_DispTyp 7;
BA_ "FlexKomSigName" SG_ 1004 VC_BU_PTS_DispTyp "VehCfgBU1_Pkt";
BA_ "FlexKomSigLaenge" SG_ 1004 VC_BU_PTS_DispTyp 64;
BA_ "FlexKomSID" SG_ 1004 VC_BU_PTS_DispTyp 919;
BA_ "FlexKomIsMotorola" SG_ 1004 VC_BU_PTS_DispTyp 1;
BA_ "FlexKomComment" SG_ 1004 VC_BU_PTS_DispTyp "Backup for Vehicle Configuration 1 Packet";
BA_ "GenSigSNA" SG_ 1004 VC_BU_HdRstPrsnt "0h";
BA_ "GenSigSendType" SG_ 1004 VC_BU_HdRstPrsnt 1;
BA_ "FlexKomSigStartValue" SG_ 1004 VC_BU_HdRstPrsnt "FFFF7FF0FF0FFF00h";
BA_ "FlexKomSigStartPos" SG_ 1004 VC_BU_HdRstPrsnt 7;
BA_ "FlexKomSigName" SG_ 1004 VC_BU_HdRstPrsnt "VehCfgBU1_Pkt";
BA_ "FlexKomSigLaenge" SG_ 1004 VC_BU_HdRstPrsnt 64;
BA_ "FlexKomSID" SG_ 1004 VC_BU_HdRstPrsnt 919;
BA_ "FlexKomIsMotorola" SG_ 1004 VC_BU_HdRstPrsnt 1;
BA_ "FlexKomComment" SG_ 1004 VC_BU_HdRstPrsnt "Backup for Vehicle Configuration 1 Packet";
BA_ "GenSigSNA" SG_ 1004 VC_BU_RVCM_Prsnt "0h";
BA_ "GenSigSendType" SG_ 1004 VC_BU_RVCM_Prsnt 1;
BA_ "FlexKomSigStartValue" SG_ 1004 VC_BU_RVCM_Prsnt "FFFF7FF0FF0FFF00h";
BA_ "FlexKomSigStartPos" SG_ 1004 VC_BU_RVCM_Prsnt 7;
BA_ "FlexKomSigName" SG_ 1004 VC_BU_RVCM_Prsnt "VehCfgBU1_Pkt";
BA_ "FlexKomSigLaenge" SG_ 1004 VC_BU_RVCM_Prsnt 64;
BA_ "FlexKomSID" SG_ 1004 VC_BU_RVCM_Prsnt 919;
BA_ "FlexKomIsMotorola" SG_ 1004 VC_BU_RVCM_Prsnt 1;
BA_ "FlexKomComment" SG_ 1004 VC_BU_RVCM_Prsnt "Backup for Vehicle Configuration 1 Packet";
BA_ "GenSigSNA" SG_ 1004 VC_BU_SSC_Prsnt "0h";
BA_ "GenSigSendType" SG_ 1004 VC_BU_SSC_Prsnt 1;
BA_ "FlexKomSigStartValue" SG_ 1004 VC_BU_SSC_Prsnt "FFFF7FF0FF0FFF00h";
BA_ "FlexKomSigStartPos" SG_ 1004 VC_BU_SSC_Prsnt 7;
BA_ "FlexKomSigName" SG_ 1004 VC_BU_SSC_Prsnt "VehCfgBU1_Pkt";
BA_ "FlexKomSigLaenge" SG_ 1004 VC_BU_SSC_Prsnt 64;
BA_ "FlexKomSID" SG_ 1004 VC_BU_SSC_Prsnt 919;
BA_ "FlexKomIsMotorola" SG_ 1004 VC_BU_SSC_Prsnt 1;
BA_ "FlexKomComment" SG_ 1004 VC_BU_SSC_Prsnt "Backup for Vehicle Configuration 1 Packet";
BA_ "GenSigSNA" SG_ 1004 VC_BU_CHMCM_Prsnt "0h";
BA_ "GenSigSendType" SG_ 1004 VC_BU_CHMCM_Prsnt 1;
BA_ "FlexKomSigStartValue" SG_ 1004 VC_BU_CHMCM_Prsnt "FFFF7FF0FF0FFF00h";
BA_ "FlexKomSigStartPos" SG_ 1004 VC_BU_CHMCM_Prsnt 7;
BA_ "FlexKomSigName" SG_ 1004 VC_BU_CHMCM_Prsnt "VehCfgBU1_Pkt";
BA_ "FlexKomSigLaenge" SG_ 1004 VC_BU_CHMCM_Prsnt 64;
BA_ "FlexKomSID" SG_ 1004 VC_BU_CHMCM_Prsnt 919;
BA_ "FlexKomIsMotorola" SG_ 1004 VC_BU_CHMCM_Prsnt 1;
BA_ "FlexKomComment" SG_ 1004 VC_BU_CHMCM_Prsnt "Backup for Vehicle Configuration 1 Packet";
BA_ "GenSigSNA" SG_ 1004 VC_BU_HDC_Prsnt "0h";
BA_ "GenSigSendType" SG_ 1004 VC_BU_HDC_Prsnt 1;
BA_ "FlexKomSigStartValue" SG_ 1004 VC_BU_HDC_Prsnt "FFFF7FF0FF0FFF00h";
BA_ "FlexKomSigStartPos" SG_ 1004 VC_BU_HDC_Prsnt 7;
BA_ "FlexKomSigName" SG_ 1004 VC_BU_HDC_Prsnt "VehCfgBU1_Pkt";
BA_ "FlexKomSigLaenge" SG_ 1004 VC_BU_HDC_Prsnt 64;
BA_ "FlexKomSID" SG_ 1004 VC_BU_HDC_Prsnt 919;
BA_ "FlexKomIsMotorola" SG_ 1004 VC_BU_HDC_Prsnt 1;
BA_ "FlexKomComment" SG_ 1004 VC_BU_HDC_Prsnt "Backup for Vehicle Configuration 1 Packet";
BA_ "GenSigSNA" SG_ 1004 VC_BU_SCR_Prsnt "0h";
BA_ "GenSigSendType" SG_ 1004 VC_BU_SCR_Prsnt 1;
BA_ "FlexKomSigStartValue" SG_ 1004 VC_BU_SCR_Prsnt "FFFF7FF0FF0FFF00h";
BA_ "FlexKomSigStartPos" SG_ 1004 VC_BU_SCR_Prsnt 7;
BA_ "FlexKomSigName" SG_ 1004 VC_BU_SCR_Prsnt "VehCfgBU1_Pkt";
BA_ "FlexKomSigLaenge" SG_ 1004 VC_BU_SCR_Prsnt 64;
BA_ "FlexKomSID" SG_ 1004 VC_BU_SCR_Prsnt 919;
BA_ "FlexKomIsMotorola" SG_ 1004 VC_BU_SCR_Prsnt 1;
BA_ "FlexKomComment" SG_ 1004 VC_BU_SCR_Prsnt "Backup for Vehicle Configuration 1 Packet";
BA_ "GenSigSNA" SG_ 1004 VC_BU_PTS_Config "0h";
BA_ "GenSigSendType" SG_ 1004 VC_BU_PTS_Config 1;
BA_ "FlexKomSigStartValue" SG_ 1004 VC_BU_PTS_Config "FFFF7FF0FF0FFF00h";
BA_ "FlexKomSigStartPos" SG_ 1004 VC_BU_PTS_Config 7;
BA_ "FlexKomSigName" SG_ 1004 VC_BU_PTS_Config "VehCfgBU1_Pkt";
BA_ "FlexKomSigLaenge" SG_ 1004 VC_BU_PTS_Config 64;
BA_ "FlexKomSID" SG_ 1004 VC_BU_PTS_Config 919;
BA_ "FlexKomIsMotorola" SG_ 1004 VC_BU_PTS_Config 1;
BA_ "FlexKomComment" SG_ 1004 VC_BU_PTS_Config "Backup for Vehicle Configuration 1 Packet";
BA_ "GenSigSNA" SG_ 1004 VC_BU_PP_Prsnt "0h";
BA_ "GenSigSendType" SG_ 1004 VC_BU_PP_Prsnt 1;
BA_ "FlexKomSigStartValue" SG_ 1004 VC_BU_PP_Prsnt "FFFF7FF0FF0FFF00h";
BA_ "FlexKomSigStartPos" SG_ 1004 VC_BU_PP_Prsnt 7;
BA_ "FlexKomSigName" SG_ 1004 VC_BU_PP_Prsnt "VehCfgBU1_Pkt";
BA_ "FlexKomSigLaenge" SG_ 1004 VC_BU_PP_Prsnt 64;
BA_ "FlexKomSID" SG_ 1004 VC_BU_PP_Prsnt 919;
BA_ "FlexKomIsMotorola" SG_ 1004 VC_BU_PP_Prsnt 1;
BA_ "FlexKomComment" SG_ 1004 VC_BU_PP_Prsnt "Backup for Vehicle Configuration 1 Packet";
BA_ "GenSigStartValue" SG_ 1004 VC_BU_SpecialPKG 255;
BA_ "GenSigSNA" SG_ 1004 VC_BU_SpecialPKG "FFh";
BA_ "GenSigSendType" SG_ 1004 VC_BU_SpecialPKG 1;
BA_ "FlexKomSigStartValue" SG_ 1004 VC_BU_SpecialPKG "FFFF7FF0FF0FFF00h";
BA_ "FlexKomSigStartPos" SG_ 1004 VC_BU_SpecialPKG 7;
BA_ "FlexKomSigName" SG_ 1004 VC_BU_SpecialPKG "VehCfgBU1_Pkt";
BA_ "FlexKomSigLaenge" SG_ 1004 VC_BU_SpecialPKG 64;
BA_ "FlexKomSID" SG_ 1004 VC_BU_SpecialPKG 919;
BA_ "FlexKomIsMotorola" SG_ 1004 VC_BU_SpecialPKG 1;
BA_ "FlexKomComment" SG_ 1004 VC_BU_SpecialPKG "Backup for Vehicle Configuration 1 Packet";
BA_ "GenSigStartValue" SG_ 1004 VC_BU_ShftrTyp 15;
BA_ "GenSigSNA" SG_ 1004 VC_BU_ShftrTyp "Fh";
BA_ "GenSigSendType" SG_ 1004 VC_BU_ShftrTyp 1;
BA_ "FlexKomSigStartValue" SG_ 1004 VC_BU_ShftrTyp "FFFF7FF0FF0FFF00h";
BA_ "FlexKomSigStartPos" SG_ 1004 VC_BU_ShftrTyp 7;
BA_ "FlexKomSigName" SG_ 1004 VC_BU_ShftrTyp "VehCfgBU1_Pkt";
BA_ "FlexKomSigLaenge" SG_ 1004 VC_BU_ShftrTyp 64;
BA_ "FlexKomSID" SG_ 1004 VC_BU_ShftrTyp 919;
BA_ "FlexKomIsMotorola" SG_ 1004 VC_BU_ShftrTyp 1;
BA_ "FlexKomComment" SG_ 1004 VC_BU_ShftrTyp "Backup for Vehicle Configuration 1 Packet";
BA_ "GenSigStartValue" SG_ 1004 VC_BU_LHD_RHD 3;
BA_ "GenSigSNA" SG_ 1004 VC_BU_LHD_RHD "3h";
BA_ "GenSigSendType" SG_ 1004 VC_BU_LHD_RHD 1;
BA_ "FlexKomSigStartValue" SG_ 1004 VC_BU_LHD_RHD "FFFF7FF0FF0FFF00h";
BA_ "FlexKomSigStartPos" SG_ 1004 VC_BU_LHD_RHD 7;
BA_ "FlexKomSigName" SG_ 1004 VC_BU_LHD_RHD "VehCfgBU1_Pkt";
BA_ "FlexKomSigLaenge" SG_ 1004 VC_BU_LHD_RHD 64;
BA_ "FlexKomSID" SG_ 1004 VC_BU_LHD_RHD 919;
BA_ "FlexKomIsMotorola" SG_ 1004 VC_BU_LHD_RHD 1;
BA_ "FlexKomComment" SG_ 1004 VC_BU_LHD_RHD "Backup for Vehicle Configuration 1 Packet";
BA_ "GenSigSNA" SG_ 1004 VC_BU_RemStPrsnt "0h";
BA_ "GenSigSendType" SG_ 1004 VC_BU_RemStPrsnt 1;
BA_ "FlexKomSigStartValue" SG_ 1004 VC_BU_RemStPrsnt "FFFF7FF0FF0FFF00h";
BA_ "FlexKomSigStartPos" SG_ 1004 VC_BU_RemStPrsnt 7;
BA_ "FlexKomSigName" SG_ 1004 VC_BU_RemStPrsnt "VehCfgBU1_Pkt";
BA_ "FlexKomSigLaenge" SG_ 1004 VC_BU_RemStPrsnt 64;
BA_ "FlexKomSID" SG_ 1004 VC_BU_RemStPrsnt 919;
BA_ "FlexKomIsMotorola" SG_ 1004 VC_BU_RemStPrsnt 1;
BA_ "FlexKomComment" SG_ 1004 VC_BU_RemStPrsnt "Backup for Vehicle Configuration 1 Packet";
BA_ "GenSigSNA" SG_ 1004 VC_BU_XWD "0h";
BA_ "GenSigSendType" SG_ 1004 VC_BU_XWD 1;
BA_ "FlexKomSigStartValue" SG_ 1004 VC_BU_XWD "FFFF7FF0FF0FFF00h";
BA_ "FlexKomSigStartPos" SG_ 1004 VC_BU_XWD 7;
BA_ "FlexKomSigName" SG_ 1004 VC_BU_XWD "VehCfgBU1_Pkt";
BA_ "FlexKomSigLaenge" SG_ 1004 VC_BU_XWD 64;
BA_ "FlexKomSID" SG_ 1004 VC_BU_XWD 919;
BA_ "FlexKomIsMotorola" SG_ 1004 VC_BU_XWD 1;
BA_ "FlexKomComment" SG_ 1004 VC_BU_XWD "Backup for Vehicle Configuration 1 Packet";
BA_ "GenSigSNA" SG_ 1004 VC_BU_EmodePrsnt "0h";
BA_ "GenSigSendType" SG_ 1004 VC_BU_EmodePrsnt 1;
BA_ "FlexKomSigStartValue" SG_ 1004 VC_BU_EmodePrsnt "FFFF7FF0FF0FFF00h";
BA_ "FlexKomSigStartPos" SG_ 1004 VC_BU_EmodePrsnt 7;
BA_ "FlexKomSigName" SG_ 1004 VC_BU_EmodePrsnt "VehCfgBU1_Pkt";
BA_ "FlexKomSigLaenge" SG_ 1004 VC_BU_EmodePrsnt 64;
BA_ "FlexKomSID" SG_ 1004 VC_BU_EmodePrsnt 919;
BA_ "FlexKomIsMotorola" SG_ 1004 VC_BU_EmodePrsnt 1;
BA_ "FlexKomComment" SG_ 1004 VC_BU_EmodePrsnt "Backup for Vehicle Configuration 1 Packet";
BA_ "GenSigSNA" SG_ 1004 VC_BU_AUTO_HB "0h";
BA_ "GenSigSendType" SG_ 1004 VC_BU_AUTO_HB 1;
BA_ "FlexKomSigStartValue" SG_ 1004 VC_BU_AUTO_HB "FFFF7FF0FF0FFF00h";
BA_ "FlexKomSigStartPos" SG_ 1004 VC_BU_AUTO_HB 7;
BA_ "FlexKomSigName" SG_ 1004 VC_BU_AUTO_HB "VehCfgBU1_Pkt";
BA_ "FlexKomSigLaenge" SG_ 1004 VC_BU_AUTO_HB 64;
BA_ "FlexKomSID" SG_ 1004 VC_BU_AUTO_HB 919;
BA_ "FlexKomIsMotorola" SG_ 1004 VC_BU_AUTO_HB 1;
BA_ "FlexKomComment" SG_ 1004 VC_BU_AUTO_HB "Backup for Vehicle Configuration 1 Packet";
BA_ "GenSigStartValue" SG_ 1004 VC_BU_BODY_STYLE 15;
BA_ "GenSigSNA" SG_ 1004 VC_BU_BODY_STYLE "Fh";
BA_ "GenSigSendType" SG_ 1004 VC_BU_BODY_STYLE 1;
BA_ "FlexKomSigStartValue" SG_ 1004 VC_BU_BODY_STYLE "FFFF7FF0FF0FFF00h";
BA_ "FlexKomSigStartPos" SG_ 1004 VC_BU_BODY_STYLE 7;
BA_ "FlexKomSigName" SG_ 1004 VC_BU_BODY_STYLE "VehCfgBU1_Pkt";
BA_ "FlexKomSigLaenge" SG_ 1004 VC_BU_BODY_STYLE 64;
BA_ "FlexKomSID" SG_ 1004 VC_BU_BODY_STYLE 919;
BA_ "FlexKomIsMotorola" SG_ 1004 VC_BU_BODY_STYLE 1;
BA_ "FlexKomComment" SG_ 1004 VC_BU_BODY_STYLE "Backup for Vehicle Configuration 1 Packet";
BA_ "GenSigStartValue" SG_ 1004 VC_BU_MODEL_YEAR 63;
BA_ "GenSigSNA" SG_ 1004 VC_BU_MODEL_YEAR "3Fh";
BA_ "GenSigSendType" SG_ 1004 VC_BU_MODEL_YEAR 1;
BA_ "FlexKomSigStartValue" SG_ 1004 VC_BU_MODEL_YEAR "FFFF7FF0FF0FFF00h";
BA_ "FlexKomSigStartPos" SG_ 1004 VC_BU_MODEL_YEAR 7;
BA_ "FlexKomSigName" SG_ 1004 VC_BU_MODEL_YEAR "VehCfgBU1_Pkt";
BA_ "FlexKomSigLaenge" SG_ 1004 VC_BU_MODEL_YEAR 64;
BA_ "FlexKomSID" SG_ 1004 VC_BU_MODEL_YEAR 919;
BA_ "FlexKomIsMotorola" SG_ 1004 VC_BU_MODEL_YEAR 1;
BA_ "FlexKomComment" SG_ 1004 VC_BU_MODEL_YEAR "Backup for Vehicle Configuration 1 Packet";
BA_ "GenSigStartValue" SG_ 1004 VC_BU_VEH_LINE 255;
BA_ "GenSigSNA" SG_ 1004 VC_BU_VEH_LINE "FFh";
BA_ "GenSigSendType" SG_ 1004 VC_BU_VEH_LINE 1;
BA_ "FlexKomSigStartValue" SG_ 1004 VC_BU_VEH_LINE "FFFF7FF0FF0FFF00h";
BA_ "FlexKomSigStartPos" SG_ 1004 VC_BU_VEH_LINE 7;
BA_ "FlexKomSigName" SG_ 1004 VC_BU_VEH_LINE "VehCfgBU1_Pkt";
BA_ "FlexKomSigLaenge" SG_ 1004 VC_BU_VEH_LINE 64;
BA_ "FlexKomSID" SG_ 1004 VC_BU_VEH_LINE 919;
BA_ "FlexKomIsMotorola" SG_ 1004 VC_BU_VEH_LINE 1;
BA_ "FlexKomComment" SG_ 1004 VC_BU_VEH_LINE "Backup for Vehicle Configuration 1 Packet";
VAL_ 996 NetCfg_DPDM 0 "Not_Present" 1 "Present" ;
VAL_ 996 NetCfg_SGW 0 "Not_Present" 1 "Present" ;
VAL_ 996 NetCfg_GPF 0 "Not_Present" 1 "Present" ;
VAL_ 996 NetCfg_BSMO 0 "Not_Present" 1 "Present" ;
VAL_ 996 NET_CFG_STAT_PT 0 "NA" 1 "PROGAMMED" 2 "REQUEST_DATA" 3 "SNA" ;
VAL_ 996 NetCfg_ASBS 0 "Not_Present" 1 "Present" ;
VAL_ 998 BU_NetCfg_ANC_I 0 "Not_Present" 1 "Present" ;
VAL_ 998 BU_NET_CFG_STAT_INT 0 "NA" 1 "PROGAMMED" 2 "NA1" 3 "SNA" ;
VAL_ 999 BU_NetCfg_ASBS 0 "Not_Present" 1 "Present" ;
VAL_ 999 BU_NetCfg_GPF 0 "Not_Present" 1 "Present" ;
VAL_ 999 BU_NetCfg_BSMO 0 "Not_Present" 1 "Present" ;
VAL_ 999 BU_NetCfg_DPDM 0 "Not_Present" 1 "Present" ;
VAL_ 999 BU_NetCfg_SGW 0 "Not_Present" 1 "Present" ;
VAL_ 999 BU_NET_CFG_STAT_PT 0 "NA" 1 "PROGAMMED" 2 "NA1" 3 "SNA" ;
VAL_ 1000 VC_MODEL_YEAR 63 "SNA" ;
VAL_ 1000 VC_COUNTRY 0 "ROW" 2 "USA" 3 "EU" 4 "CND" 5 "GB" 6 "JPN" 7 "GER" 8 "SWISS" 9 "MLY" 10 "AUS" 11 "IND" 12 "GULF" 13 "VEN" 14 "MEX" 15 "BRZ" 16 "CHINA" 17 "EGYPT" 20 "S_KOR" 21 "ECE" 22 "AR" 23 "CL" 31 "COUNTRY_SNA" ;
VAL_ 1000 VC_LHD_RHD 0 "NA" 1 "LHD" 2 "RHD" 3 "SNA" ;
VAL_ 1000 VC_VehCfg1_Stat 0 "NA" 1 "PROGAMMED" 2 "REQUEST_DATA" 3 "SNA" ;
VAL_ 1000 VC_PTS_DispTyp 0 "HEAD_DISP" 1 "CCN_DISP" 2 "AUDIO_DISP" 7 "SNA" ;
VAL_ 1000 VC_VEH_LINE 0 "VEH_NONE" 1 "VEH_WK" 2 "VEH_LX" 22 "VEH_JC" 29 "VEH_DS" 31 "VEH_D2" 32 "VEH_DD" 33 "VEH_DP" 34 "VEH_DJ" 35 "VEH_WD" 39 "VEH_DX" 41 "VEH_LD" 42 "VEH_M156" 43 "VEH_ZD" 44 "VEH_LA" 45 "VEH_RU" 46 "VEH_M161" 47 "VEH_WS" 48 "VEH_DF" 49 "VEH_JL" 50 "VEH_M157" 51 "VEH_RA" 52 "VEH_WL" 53 "VEH_DT" 54 "VEH_DU" 55 "VEH_JT" 56 "VEH_RU_PACIFICA" 80 "VEH_PF" 81 "VEH_KL" 82 "VEH_UF" 83 "VEH_UT" 84 "VEH_M145" 85 "VEH_M145BD" 86 "VEH_K8" 87 "VEH_FF" 88 "FF_Abarth" 108 "VEH_M182" 199 "VEH_598" 200 "VEH_M1" 201 "VEH_M6" 202 "VEH_M4" 203 "VEH_M7" 204 "VEH_MP" 205 "VEH_MV" 255 "SNA" ;
VAL_ 1000 VC_SpecialPKG 0 "NONE" 255 "SNA" ;
VAL_ 1000 VC_PTS_Config 0 "REAR" 1 "FRT_REAR" 3 "SEMI" ;
VAL_ 1000 VC_BODY_STYLE 0 "BODY_NONE" 1 "BODY_4DS" 2 "BODY_2DS" 3 "BODY_CONV" 4 "BODY_WAGON" 5 "BODY_4DH" 6 "BODY_2DP" 7 "BODY_4DP" 8 "BODY_4DMP" 15 "BODY_SNA" ;
VAL_ 1000 VC_MAX_VEH_SPD 255 "SNA" ;
VAL_ 1000 VC_ShftrTyp 0 "TYPE_NA" 1 "TYPE_ERS4" 2 "TYPE_AS4" 3 "TYPE_ERS5" 4 "TYPE_AS5" 5 "TYPE_RS5M" 6 "TYPE_RS5S" 7 "TYPE_RS5L" 8 "TYPE_ERS4ESW" 9 "TYPE_MS7D" 10 "TYPE_MS7M156" 11 "TYPE_RS4" 12 "TYPE_MS7S" 13 "TYPE_MS7" 14 "TYPE_PS5" 15 "SNA" ;
VAL_ 1000 VC_XWD 0 "2FT" 1 "2RR" 2 "ALLWD" 3 "4WD" ;
VAL_ 1001 VC_MaseratiMd 0 "NORMAL" 1 "GTS" 2 "RACE" 3 "SNA" ;
VAL_ 1001 VC_ShftInd_Prsnt 0 "NONE" 1 "GSI" 2 "PSI" 3 "PGSI" ;
VAL_ 1001 VC_LgtLdPressFtTr 255 "SNA" ;
VAL_ 1001 VC_MaxLdPressRrTr 255 "SNA" ;
VAL_ 1001 VC_MaxLdPressFtTr 255 "SNA" ;
VAL_ 1001 VC_LgtLdPressRrTr 255 "SNA" ;
VAL_ 1001 VC_VehCfg2_Stat 0 "NA" 1 "PROGAMMED" 2 "REQUEST_DATA" 3 "SNA" ;
VAL_ 1001 VC_PwrIvtrTyp 0 "NoPwrIvtr" 1 "MtrySw" 2 "LchSw" ;
VAL_ 1001 VC_SpecialPKG_IC 0 "NONE" 1 "PKG_70JP" 2 "PKG_300S" 3 "PKG_BEATS" 4 "PKG_SUPERBEE" 5 "MOPAR" 6 "Hellcat" 7 "Shaker" 8 "Scat" 9 "ADR" 10 "Scat_Drag" 11 "High_Output" 12 "Hellcat_HO" 16 "LARAMIE" 17 "BIGHORN" 18 "LONGHORN" 19 "LONESTAR" 20 "LIMITED" 21 "MOSSY_OAK" 22 "ORT" 23 "POWERWAGON" 24 "HD_DX" 25 "SPORT" 26 "PWGN_Laramie" 27 "RAM_1500" 28 "PWGN_GOODYEAR" 29 "LONGHORN_BLACK" 30 "LONGHORN_BROWN" 31 "RAM_2500" 32 "RAM_3500" 33 "RAM_4500" 34 "RAM_5500" 35 "RAM_TRX21" 36 "VOYAGER" 37 "PACIFICA" 38 "GRAND_CARAVAN" 39 "50th_Anniversary" 40 "80th_Anniversary" 41 "J9_Splash_Screen" 42 "Hellcat_LA" 100 "WRANGLER_SPORT" 101 "WRANGLER_SAHARA" 102 "WRANGLER_RUBICON" 103 "JEEP_SPORT" 104 "JEEP_SPORT_X" 105 "JEEP_RUBICON" 106 "JEEP_PRO_FIGHTER" 107 "10th_Anniversary" 108 "Limited_10th_Anniversary" 109 "TRX_Ignition" 110 "RED" 150 "TRAILHAWK_SUPERCHARGED" 151 "TRX_Final_Edition" 246 "DODGE_100" 247 "VARVATOS" 255 "SNA" ;
VAL_ 1002 VC_Liftgate_Trunk 0 "TRUNK" 1 "PLG" 2 "MANUAL_LG" 3 "SNA" ;
VAL_ 1002 VC_HVAC_Config 0 "1_ZN_MTC" 1 "1_ZN_MTC_p_RR" 2 "1_ZN_ATC" 3 "2_ZN_MTC" 4 "2_ZN_ATC" 5 "2_ZN_ATC_p_RR" 6 "2_ZN_MTC_p_RR" 15 "SNA" ;
VAL_ 1002 VC_VEH_BRAND 1 "CHRYSLER" 2 "DODGE" 3 "JEEP" 4 "MERCEDES_BENZ" 5 "MITSUBISHI" 6 "VOLKSWAGEN" 7 "FREIGHTLINER" 8 "ALPHA" 9 "FIAT" 10 "LANCIA" 11 "MASERATI" 12 "RAM" 15 "SNA" ;
VAL_ 1002 VC_WIN_EXPR_FEAT 0 "WIN_EXPR_DRV" 1 "WIN_EXPR_FT" 2 "WIN_EXPR_ALL" 3 "WIN_EXPR_NN" ;
VAL_ 1002 VC_ChassisType 127 "SNA" ;
VAL_ 1002 VC_WHL_BASE 0 "SHORT" 1 "LONG" 2 "XLONG" 3 "SNA" ;
VAL_ 1002 VC_FUEL_CAP 255 "SNA" ;
VAL_ 1002 VC_VehCfg3_Stat 0 "NA" 1 "PROGAMMED" 2 "REQUEST_DATA" 3 "SNA" ;
VAL_ 1002 VC_TcaseTyp 0 "NOT_PRSNT" 1 "TCASE_143_144" 2 "BW4445_46_48_WS" 3 "Tcase_253_1522" 4 "Tcase_BW4444" 5 "Tcase_BW4446" 6 "Tcase_MPT3025C" 7 "Tcase_241_MPT1222C" 8 "BW4447_WOS" 9 "Tcase_243" 10 "BW4447_49_WS" 11 "Tcase_273" 12 "Tcase_MAS_ATC" 13 "Tcase_BW4440" 14 "Tcase_156" 15 "Tcase_256_3022" ;
VAL_ 1003 VC_TCASE_HI_RATIO 16383 "SNA" ;
VAL_ 1003 VC_AXLE_RATIO 65535 "SNA" ;
VAL_ 1003 VC_TCASE_LO_RATIO 65535 "SNA" ;
VAL_ 1003 VC_TIRE_CIRCUMF 65535 "SNA" ;
VAL_ 1003 VC_VehCfg4_Stat 0 "NA" 1 "PROGAMMED" 2 "REQUEST_DATA" 3 "SNA" ;
VAL_ 1004 VC_BU_VehCfg1_Stat 0 "NA" 1 "PROGAMMED" 2 "NA1" 3 "SNA" ;
VAL_ 1004 VC_BU_COUNTRY 0 "ROW" 2 "USA" 3 "EU" 4 "CND" 5 "GB" 6 "JPN" 7 "GER" 8 "SWISS" 9 "MLY" 10 "AUS" 11 "IND" 12 "GULF" 13 "VEN" 14 "MEX" 15 "BRZ" 16 "CHINA" 17 "EGYPT" 20 "S_KOR" 21 "ECE" 22 "AR" 23 "CL" 31 "COUNTRY_SNA" ;
VAL_ 1004 VC_BU_MAX_VEH_SPD 255 "SNA" ;
VAL_ 1004 VC_BU_PTS_DispTyp 0 "HEAD_DISP" 1 "CCN_DISP" 2 "AUDIO_DISP" 7 "SNA" ;
VAL_ 1004 VC_BU_PTS_Config 0 "REAR" 1 "FRT_REAR" 3 "SEMI" ;
VAL_ 1004 VC_BU_SpecialPKG 0 "NONE" 255 "SNA" ;
VAL_ 1004 VC_BU_ShftrTyp 0 "TYPE_NA" 1 "TYPE_ERS4" 2 "TYPE_AS4" 3 "TYPE_ERS5" 4 "TYPE_AS5" 5 "TYPE_RS5M" 6 "TYPE_RS5S" 7 "TYPE_RS5L" 8 "TYPE_ERS4ESW" 9 "TYPE_MS7D" 10 "TYPE_MS7M156" 11 "TYPE_RS4" 12 "TYPE_MS7S" 13 "TYPE_MS7" 14 "TYPE_PS5" 15 "SNA" ;
VAL_ 1004 VC_BU_LHD_RHD 0 "NA" 1 "LHD" 2 "RHD" 3 "SNA" ;
VAL_ 1004 VC_BU_RemStPrsnt 0 "SNA" ;
VAL_ 1004 VC_BU_XWD 0 "2FT" 1 "2RR" 2 "ALLWD" 3 "4WD" ;
VAL_ 1004 VC_BU_BODY_STYLE 0 "BODY_NONE" 1 "BODY_4DS" 2 "BODY_2DS" 3 "BODY_CONV" 4 "BODY_WAGON" 5 "BODY_4DH" 6 "BODY_2DP" 7 "BODY_4DP" 8 "BODY_4DMP" 15 "BODY_SNA" ;
VAL_ 1004 VC_BU_MODEL_YEAR 63 "SNA" ;
VAL_ 1004 VC_BU_VEH_LINE 0 "VEH_NONE" 1 "VEH_WK" 2 "VEH_LX" 22 "VEH_JC" 29 "VEH_DS" 31 "VEH_D2" 32 "VEH_DD" 33 "VEH_DP" 34 "VEH_DJ" 35 "VEH_WD" 39 "VEH_DX" 41 "VEH_LD" 42 "VEH_M156" 43 "VEH_ZD" 44 "VEH_LA" 45 "VEH_RU" 46 "VEH_M161" 47 "VEH_WS" 48 "VEH_DF" 49 "VEH_JL" 50 "VEH_M157" 51 "VEH_RA" 52 "VEH_WL" 53 "VEH_DT" 54 "VEH_DU" 55 "VEH_JT" 56 "VEH_RU_PACIFICA" 80 "VEH_PF" 81 "VEH_KL" 82 "VEH_UF" 83 "VEH_UT" 84 "VEH_M145" 85 "VEH_M145BD" 86 "VEH_K8" 87 "VEH_FF" 88 "FF_Abarth" 108 "VEH_M182" 199 "VEH_598" 200 "VEH_M1" 201 "VEH_M6" 202 "VEH_M4" 203 "VEH_M7" 204 "VEH_MP" 205 "VEH_MV" 255 "SNA" ;
